VERSION ""

NS_ :

BS_:

BU_: Vector__XXX

BO_ 608 f_CellTemperatures: 8 Vector__XXX
SG_ f_CellTemperatures_Mux M : 7|8@0+ (1,0) [0|0] "" Vector__XXX
SG_ CellTemperature_000_invalidFlag m0 : 8|1@0+ (1,0) [0|1] "" Vector__XXX
SG_ CellTemperature_001_invalidFlag m0 : 9|1@0+ (1,0) [0|1] "" Vector__XXX
SG_ CellTemperature_002_invalidFlag m0 : 10|1@0+ (1,0) [0|1] "" Vector__XXX
SG_ CellTemperature_003_invalidFlag m0 : 11|1@0+ (1,0) [0|1] "" Vector__XXX
SG_ CellTemperature_004_invalidFlag m0 : 12|1@0+ (1,0) [0|1] "" Vector__XXX
SG_ CellTemperature_005_invalidFlag m0 : 13|1@0+ (1,0) [0|1] "" Vector__XXX
SG_ CellTemperature_000 m0 : 23|8@0- (1,0) [-128|127] "degC" Vector__XXX
SG_ CellTemperature_001 m0 : 31|8@0- (1,0) [-128|127] "degC" Vector__XXX
SG_ CellTemperature_002 m0 : 39|8@0- (1,0) [-128|127] "degC" Vector__XXX
SG_ CellTemperature_003 m0 : 47|8@0- (1,0) [-128|127] "degC" Vector__XXX
SG_ CellTemperature_004 m0 : 55|8@0- (1,0) [-128|127] "degC" Vector__XXX
SG_ CellTemperature_005 m0 : 63|8@0- (1,0) [-128|127] "degC" Vector__XXX
SG_ CellTemperature_006_invalidFlag m1 : 8|1@0+ (1,0) [0|1] "" Vector__XXX
SG_ CellTemperature_007_invalidFlag m1 : 9|1@0+ (1,0) [0|1] "" Vector__XXX
SG_ CellTemperature_008_invalidFlag m1 : 10|1@0+ (1,0) [0|1] "" Vector__XXX
SG_ CellTemperature_009_invalidFlag m1 : 11|1@0+ (1,0) [0|1] "" Vector__XXX
SG_ CellTemperature_010_invalidFlag m1 : 12|1@0+ (1,0) [0|1] "" Vector__XXX
SG_ CellTemperature_011_invalidFlag m1 : 13|1@0+ (1,0) [0|1] "" Vector__XXX
SG_ CellTemperature_006 m1 : 23|8@0- (1,0) [-128|127] "degC" Vector__XXX
SG_ CellTemperature_007 m1 : 31|8@0- (1,0) [-128|127] "degC" Vector__XXX
SG_ CellTemperature_008 m1 : 39|8@0- (1,0) [-128|127] "degC" Vector__XXX
SG_ CellTemperature_009 m1 : 47|8@0- (1,0) [-128|127] "degC" Vector__XXX
SG_ CellTemperature_010 m1 : 55|8@0- (1,0) [-128|127] "degC" Vector__XXX
SG_ CellTemperature_011 m1 : 63|8@0- (1,0) [-128|127] "degC" Vector__XXX
SG_ CellTemperature_012_invalidFlag m2 : 8|1@0+ (1,0) [0|1] "" Vector__XXX
SG_ CellTemperature_013_invalidFlag m2 : 9|1@0+ (1,0) [0|1] "" Vector__XXX
SG_ CellTemperature_014_invalidFlag m2 : 10|1@0+ (1,0) [0|1] "" Vector__XXX
SG_ CellTemperature_015_invalidFlag m2 : 11|1@0+ (1,0) [0|1] "" Vector__XXX
SG_ CellTemperature_016_invalidFlag m2 : 12|1@0+ (1,0) [0|1] "" Vector__XXX
SG_ CellTemperature_017_invalidFlag m2 : 13|1@0+ (1,0) [0|1] "" Vector__XXX
SG_ CellTemperature_012 m2 : 23|8@0- (1,0) [-128|127] "degC" Vector__XXX
SG_ CellTemperature_013 m2 : 31|8@0- (1,0) [-128|127] "degC" Vector__XXX
SG_ CellTemperature_014 m2 : 39|8@0- (1,0) [-128|127] "degC" Vector__XXX
SG_ CellTemperature_015 m2 : 47|8@0- (1,0) [-128|127] "degC" Vector__XXX
SG_ CellTemperature_016 m2 : 55|8@0- (1,0) [-128|127] "degC" Vector__XXX
SG_ CellTemperature_017 m2 : 63|8@0- (1,0) [-128|127] "degC" Vector__XXX
SG_ CellTemperature_018_invalidFlag m3 : 8|1@0+ (1,0) [0|1] "" Vector__XXX
SG_ CellTemperature_019_invalidFlag m3 : 9|1@0+ (1,0) [0|1] "" Vector__XXX
SG_ CellTemperature_020_invalidFlag m3 : 10|1@0+ (1,0) [0|1] "" Vector__XXX
SG_ CellTemperature_021_invalidFlag m3 : 11|1@0+ (1,0) [0|1] "" Vector__XXX
SG_ CellTemperature_022_invalidFlag m3 : 12|1@0+ (1,0) [0|1] "" Vector__XXX
SG_ CellTemperature_023_invalidFlag m3 : 13|1@0+ (1,0) [0|1] "" Vector__XXX
SG_ CellTemperature_018 m3 : 23|8@0- (1,0) [-128|127] "degC" Vector__XXX
SG_ CellTemperature_019 m3 : 31|8@0- (1,0) [-128|127] "degC" Vector__XXX
SG_ CellTemperature_020 m3 : 39|8@0- (1,0) [-128|127] "degC" Vector__XXX
SG_ CellTemperature_021 m3 : 47|8@0- (1,0) [-128|127] "degC" Vector__XXX
SG_ CellTemperature_022 m3 : 55|8@0- (1,0) [-128|127] "degC" Vector__XXX
SG_ CellTemperature_023 m3 : 63|8@0- (1,0) [-128|127] "degC" Vector__XXX
SG_ CellTemperature_024_invalidFlag m4 : 8|1@0+ (1,0) [0|1] "" Vector__XXX
SG_ CellTemperature_025_invalidFlag m4 : 9|1@0+ (1,0) [0|1] "" Vector__XXX
SG_ CellTemperature_026_invalidFlag m4 : 10|1@0+ (1,0) [0|1] "" Vector__XXX
SG_ CellTemperature_027_invalidFlag m4 : 11|1@0+ (1,0) [0|1] "" Vector__XXX
SG_ CellTemperature_028_invalidFlag m4 : 12|1@0+ (1,0) [0|1] "" Vector__XXX
SG_ CellTemperature_029_invalidFlag m4 : 13|1@0+ (1,0) [0|1] "" Vector__XXX
SG_ CellTemperature_024 m4 : 23|8@0- (1,0) [-128|127] "degC" Vector__XXX
SG_ CellTemperature_025 m4 : 31|8@0- (1,0) [-128|127] "degC" Vector__XXX
SG_ CellTemperature_026 m4 : 39|8@0- (1,0) [-128|127] "degC" Vector__XXX
SG_ CellTemperature_027 m4 : 47|8@0- (1,0) [-128|127] "degC" Vector__XXX
SG_ CellTemperature_028 m4 : 55|8@0- (1,0) [-128|127] "degC" Vector__XXX
SG_ CellTemperature_029 m4 : 63|8@0- (1,0) [-128|127] "degC" Vector__XXX
SG_ CellTemperature_030_invalidFlag m5 : 8|1@0+ (1,0) [0|1] "" Vector__XXX
SG_ CellTemperature_031_invalidFlag m5 : 9|1@0+ (1,0) [0|1] "" Vector__XXX
SG_ CellTemperature_032_invalidFlag m5 : 10|1@0+ (1,0) [0|1] "" Vector__XXX
SG_ CellTemperature_033_invalidFlag m5 : 11|1@0+ (1,0) [0|1] "" Vector__XXX
SG_ CellTemperature_034_invalidFlag m5 : 12|1@0+ (1,0) [0|1] "" Vector__XXX
SG_ CellTemperature_035_invalidFlag m5 : 13|1@0+ (1,0) [0|1] "" Vector__XXX
SG_ CellTemperature_030 m5 : 23|8@0- (1,0) [-128|127] "degC" Vector__XXX
SG_ CellTemperature_031 m5 : 31|8@0- (1,0) [-128|127] "degC" Vector__XXX
SG_ CellTemperature_032 m5 : 39|8@0- (1,0) [-128|127] "degC" Vector__XXX
SG_ CellTemperature_033 m5 : 47|8@0- (1,0) [-128|127] "degC" Vector__XXX
SG_ CellTemperature_034 m5 : 55|8@0- (1,0) [-128|127] "degC" Vector__XXX
SG_ CellTemperature_035 m5 : 63|8@0- (1,0) [-128|127] "degC" Vector__XXX
SG_ CellTemperature_036_invalidFlag m6 : 8|1@0+ (1,0) [0|1] "" Vector__XXX
SG_ CellTemperature_037_invalidFlag m6 : 9|1@0+ (1,0) [0|1] "" Vector__XXX
SG_ CellTemperature_038_invalidFlag m6 : 10|1@0+ (1,0) [0|1] "" Vector__XXX
SG_ CellTemperature_039_invalidFlag m6 : 11|1@0+ (1,0) [0|1] "" Vector__XXX
SG_ CellTemperature_040_invalidFlag m6 : 12|1@0+ (1,0) [0|1] "" Vector__XXX
SG_ CellTemperature_041_invalidFlag m6 : 13|1@0+ (1,0) [0|1] "" Vector__XXX
SG_ CellTemperature_036 m6 : 23|8@0- (1,0) [-128|127] "degC" Vector__XXX
SG_ CellTemperature_037 m6 : 31|8@0- (1,0) [-128|127] "degC" Vector__XXX
SG_ CellTemperature_038 m6 : 39|8@0- (1,0) [-128|127] "degC" Vector__XXX
SG_ CellTemperature_039 m6 : 47|8@0- (1,0) [-128|127] "degC" Vector__XXX
SG_ CellTemperature_040 m6 : 55|8@0- (1,0) [-128|127] "degC" Vector__XXX
SG_ CellTemperature_041 m6 : 63|8@0- (1,0) [-128|127] "degC" Vector__XXX
SG_ CellTemperature_042_invalidFlag m7 : 8|1@0+ (1,0) [0|1] "" Vector__XXX
SG_ CellTemperature_043_invalidFlag m7 : 9|1@0+ (1,0) [0|1] "" Vector__XXX
SG_ CellTemperature_044_invalidFlag m7 : 10|1@0+ (1,0) [0|1] "" Vector__XXX
SG_ CellTemperature_045_invalidFlag m7 : 11|1@0+ (1,0) [0|1] "" Vector__XXX
SG_ CellTemperature_046_invalidFlag m7 : 12|1@0+ (1,0) [0|1] "" Vector__XXX
SG_ CellTemperature_047_invalidFlag m7 : 13|1@0+ (1,0) [0|1] "" Vector__XXX
SG_ CellTemperature_042 m7 : 23|8@0- (1,0) [-128|127] "degC" Vector__XXX
SG_ CellTemperature_043 m7 : 31|8@0- (1,0) [-128|127] "degC" Vector__XXX
SG_ CellTemperature_044 m7 : 39|8@0- (1,0) [-128|127] "degC" Vector__XXX
SG_ CellTemperature_045 m7 : 47|8@0- (1,0) [-128|127] "degC" Vector__XXX
SG_ CellTemperature_046 m7 : 55|8@0- (1,0) [-128|127] "degC" Vector__XXX
SG_ CellTemperature_047 m7 : 63|8@0- (1,0) [-128|127] "degC" Vector__XXX
SG_ CellTemperature_048_invalidFlag m8 : 8|1@0+ (1,0) [0|1] "" Vector__XXX
SG_ CellTemperature_049_invalidFlag m8 : 9|1@0+ (1,0) [0|1] "" Vector__XXX
SG_ CellTemperature_050_invalidFlag m8 : 10|1@0+ (1,0) [0|1] "" Vector__XXX
SG_ CellTemperature_051_invalidFlag m8 : 11|1@0+ (1,0) [0|1] "" Vector__XXX
SG_ CellTemperature_052_invalidFlag m8 : 12|1@0+ (1,0) [0|1] "" Vector__XXX
SG_ CellTemperature_053_invalidFlag m8 : 13|1@0+ (1,0) [0|1] "" Vector__XXX
SG_ CellTemperature_048 m8 : 23|8@0- (1,0) [-128|127] "degC" Vector__XXX
SG_ CellTemperature_049 m8 : 31|8@0- (1,0) [-128|127] "degC" Vector__XXX
SG_ CellTemperature_050 m8 : 39|8@0- (1,0) [-128|127] "degC" Vector__XXX
SG_ CellTemperature_051 m8 : 47|8@0- (1,0) [-128|127] "degC" Vector__XXX
SG_ CellTemperature_052 m8 : 55|8@0- (1,0) [-128|127] "degC" Vector__XXX
SG_ CellTemperature_053 m8 : 63|8@0- (1,0) [-128|127] "degC" Vector__XXX
SG_ CellTemperature_054_invalidFlag m9 : 8|1@0+ (1,0) [0|1] "" Vector__XXX
SG_ CellTemperature_055_invalidFlag m9 : 9|1@0+ (1,0) [0|1] "" Vector__XXX
SG_ CellTemperature_056_invalidFlag m9 : 10|1@0+ (1,0) [0|1] "" Vector__XXX
SG_ CellTemperature_057_invalidFlag m9 : 11|1@0+ (1,0) [0|1] "" Vector__XXX
SG_ CellTemperature_058_invalidFlag m9 : 12|1@0+ (1,0) [0|1] "" Vector__XXX
SG_ CellTemperature_059_invalidFlag m9 : 13|1@0+ (1,0) [0|1] "" Vector__XXX
SG_ CellTemperature_054 m9 : 23|8@0- (1,0) [-128|127] "degC" Vector__XXX
SG_ CellTemperature_055 m9 : 31|8@0- (1,0) [-128|127] "degC" Vector__XXX
SG_ CellTemperature_056 m9 : 39|8@0- (1,0) [-128|127] "degC" Vector__XXX
SG_ CellTemperature_057 m9 : 47|8@0- (1,0) [-128|127] "degC" Vector__XXX
SG_ CellTemperature_058 m9 : 55|8@0- (1,0) [-128|127] "degC" Vector__XXX
SG_ CellTemperature_059 m9 : 63|8@0- (1,0) [-128|127] "degC" Vector__XXX
SG_ CellTemperature_060_invalidFlag m10 : 8|1@0+ (1,0) [0|1] "" Vector__XXX
SG_ CellTemperature_061_invalidFlag m10 : 9|1@0+ (1,0) [0|1] "" Vector__XXX
SG_ CellTemperature_062_invalidFlag m10 : 10|1@0+ (1,0) [0|1] "" Vector__XXX
SG_ CellTemperature_063_invalidFlag m10 : 11|1@0+ (1,0) [0|1] "" Vector__XXX
SG_ CellTemperature_064_invalidFlag m10 : 12|1@0+ (1,0) [0|1] "" Vector__XXX
SG_ CellTemperature_065_invalidFlag m10 : 13|1@0+ (1,0) [0|1] "" Vector__XXX
SG_ CellTemperature_060 m10 : 23|8@0- (1,0) [-128|127] "degC" Vector__XXX
SG_ CellTemperature_061 m10 : 31|8@0- (1,0) [-128|127] "degC" Vector__XXX
SG_ CellTemperature_062 m10 : 39|8@0- (1,0) [-128|127] "degC" Vector__XXX
SG_ CellTemperature_063 m10 : 47|8@0- (1,0) [-128|127] "degC" Vector__XXX
SG_ CellTemperature_064 m10 : 55|8@0- (1,0) [-128|127] "degC" Vector__XXX
SG_ CellTemperature_065 m10 : 63|8@0- (1,0) [-128|127] "degC" Vector__XXX
SG_ CellTemperature_066_invalidFlag m11 : 8|1@0+ (1,0) [0|1] "" Vector__XXX
SG_ CellTemperature_067_invalidFlag m11 : 9|1@0+ (1,0) [0|1] "" Vector__XXX
SG_ CellTemperature_068_invalidFlag m11 : 10|1@0+ (1,0) [0|1] "" Vector__XXX
SG_ CellTemperature_069_invalidFlag m11 : 11|1@0+ (1,0) [0|1] "" Vector__XXX
SG_ CellTemperature_070_invalidFlag m11 : 12|1@0+ (1,0) [0|1] "" Vector__XXX
SG_ CellTemperature_071_invalidFlag m11 : 13|1@0+ (1,0) [0|1] "" Vector__XXX
SG_ CellTemperature_066 m11 : 23|8@0- (1,0) [-128|127] "degC" Vector__XXX
SG_ CellTemperature_067 m11 : 31|8@0- (1,0) [-128|127] "degC" Vector__XXX
SG_ CellTemperature_068 m11 : 39|8@0- (1,0) [-128|127] "degC" Vector__XXX
SG_ CellTemperature_069 m11 : 47|8@0- (1,0) [-128|127] "degC" Vector__XXX
SG_ CellTemperature_070 m11 : 55|8@0- (1,0) [-128|127] "degC" Vector__XXX
SG_ CellTemperature_071 m11 : 63|8@0- (1,0) [-128|127] "degC" Vector__XXX
SG_ CellTemperature_072_invalidFlag m12 : 8|1@0+ (1,0) [0|1] "" Vector__XXX
SG_ CellTemperature_073_invalidFlag m12 : 9|1@0+ (1,0) [0|1] "" Vector__XXX
SG_ CellTemperature_074_invalidFlag m12 : 10|1@0+ (1,0) [0|1] "" Vector__XXX
SG_ CellTemperature_075_invalidFlag m12 : 11|1@0+ (1,0) [0|1] "" Vector__XXX
SG_ CellTemperature_076_invalidFlag m12 : 12|1@0+ (1,0) [0|1] "" Vector__XXX
SG_ CellTemperature_077_invalidFlag m12 : 13|1@0+ (1,0) [0|1] "" Vector__XXX
SG_ CellTemperature_072 m12 : 23|8@0- (1,0) [-128|127] "degC" Vector__XXX
SG_ CellTemperature_073 m12 : 31|8@0- (1,0) [-128|127] "degC" Vector__XXX
SG_ CellTemperature_074 m12 : 39|8@0- (1,0) [-128|127] "degC" Vector__XXX
SG_ CellTemperature_075 m12 : 47|8@0- (1,0) [-128|127] "degC" Vector__XXX
SG_ CellTemperature_076 m12 : 55|8@0- (1,0) [-128|127] "degC" Vector__XXX
SG_ CellTemperature_077 m12 : 63|8@0- (1,0) [-128|127] "degC" Vector__XXX
SG_ CellTemperature_078_invalidFlag m13 : 8|1@0+ (1,0) [0|1] "" Vector__XXX
SG_ CellTemperature_079_invalidFlag m13 : 9|1@0+ (1,0) [0|1] "" Vector__XXX
SG_ CellTemperature_080_invalidFlag m13 : 10|1@0+ (1,0) [0|1] "" Vector__XXX
SG_ CellTemperature_081_invalidFlag m13 : 11|1@0+ (1,0) [0|1] "" Vector__XXX
SG_ CellTemperature_082_invalidFlag m13 : 12|1@0+ (1,0) [0|1] "" Vector__XXX
SG_ CellTemperature_083_invalidFlag m13 : 13|1@0+ (1,0) [0|1] "" Vector__XXX
SG_ CellTemperature_078 m13 : 23|8@0- (1,0) [-128|127] "degC" Vector__XXX
SG_ CellTemperature_079 m13 : 31|8@0- (1,0) [-128|127] "degC" Vector__XXX
SG_ CellTemperature_080 m13 : 39|8@0- (1,0) [-128|127] "degC" Vector__XXX
SG_ CellTemperature_081 m13 : 47|8@0- (1,0) [-128|127] "degC" Vector__XXX
SG_ CellTemperature_082 m13 : 55|8@0- (1,0) [-128|127] "degC" Vector__XXX
SG_ CellTemperature_083 m13 : 63|8@0- (1,0) [-128|127] "degC" Vector__XXX
SG_ CellTemperature_084_invalidFlag m14 : 8|1@0+ (1,0) [0|1] "" Vector__XXX
SG_ CellTemperature_085_invalidFlag m14 : 9|1@0+ (1,0) [0|1] "" Vector__XXX
SG_ CellTemperature_086_invalidFlag m14 : 10|1@0+ (1,0) [0|1] "" Vector__XXX
SG_ CellTemperature_087_invalidFlag m14 : 11|1@0+ (1,0) [0|1] "" Vector__XXX
SG_ CellTemperature_088_invalidFlag m14 : 12|1@0+ (1,0) [0|1] "" Vector__XXX
SG_ CellTemperature_089_invalidFlag m14 : 13|1@0+ (1,0) [0|1] "" Vector__XXX
SG_ CellTemperature_084 m14 : 23|8@0- (1,0) [-128|127] "degC" Vector__XXX
SG_ CellTemperature_085 m14 : 31|8@0- (1,0) [-128|127] "degC" Vector__XXX
SG_ CellTemperature_086 m14 : 39|8@0- (1,0) [-128|127] "degC" Vector__XXX
SG_ CellTemperature_087 m14 : 47|8@0- (1,0) [-128|127] "degC" Vector__XXX
SG_ CellTemperature_088 m14 : 55|8@0- (1,0) [-128|127] "degC" Vector__XXX
SG_ CellTemperature_089 m14 : 63|8@0- (1,0) [-128|127] "degC" Vector__XXX
SG_ CellTemperature_090_invalidFlag m15 : 8|1@0+ (1,0) [0|1] "" Vector__XXX
SG_ CellTemperature_091_invalidFlag m15 : 9|1@0+ (1,0) [0|1] "" Vector__XXX
SG_ CellTemperature_092_invalidFlag m15 : 10|1@0+ (1,0) [0|1] "" Vector__XXX
SG_ CellTemperature_093_invalidFlag m15 : 11|1@0+ (1,0) [0|1] "" Vector__XXX
SG_ CellTemperature_094_invalidFlag m15 : 12|1@0+ (1,0) [0|1] "" Vector__XXX
SG_ CellTemperature_095_invalidFlag m15 : 13|1@0+ (1,0) [0|1] "" Vector__XXX
SG_ CellTemperature_090 m15 : 23|8@0- (1,0) [-128|127] "degC" Vector__XXX
SG_ CellTemperature_091 m15 : 31|8@0- (1,0) [-128|127] "degC" Vector__XXX
SG_ CellTemperature_092 m15 : 39|8@0- (1,0) [-128|127] "degC" Vector__XXX
SG_ CellTemperature_093 m15 : 47|8@0- (1,0) [-128|127] "degC" Vector__XXX
SG_ CellTemperature_094 m15 : 55|8@0- (1,0) [-128|127] "degC" Vector__XXX
SG_ CellTemperature_095 m15 : 63|8@0- (1,0) [-128|127] "degC" Vector__XXX
SG_ CellTemperature_096_invalidFlag m16 : 8|1@0+ (1,0) [0|1] "" Vector__XXX
SG_ CellTemperature_097_invalidFlag m16 : 9|1@0+ (1,0) [0|1] "" Vector__XXX
SG_ CellTemperature_098_invalidFlag m16 : 10|1@0+ (1,0) [0|1] "" Vector__XXX
SG_ CellTemperature_099_invalidFlag m16 : 11|1@0+ (1,0) [0|1] "" Vector__XXX
SG_ CellTemperature_100_invalidFlag m16 : 12|1@0+ (1,0) [0|1] "" Vector__XXX
SG_ CellTemperature_101_invalidFlag m16 : 13|1@0+ (1,0) [0|1] "" Vector__XXX
SG_ CellTemperature_096 m16 : 23|8@0- (1,0) [-128|127] "degC" Vector__XXX
SG_ CellTemperature_097 m16 : 31|8@0- (1,0) [-128|127] "degC" Vector__XXX
SG_ CellTemperature_098 m16 : 39|8@0- (1,0) [-128|127] "degC" Vector__XXX
SG_ CellTemperature_099 m16 : 47|8@0- (1,0) [-128|127] "degC" Vector__XXX
SG_ CellTemperature_100 m16 : 55|8@0- (1,0) [-128|127] "degC" Vector__XXX
SG_ CellTemperature_101 m16 : 63|8@0- (1,0) [-128|127] "degC" Vector__XXX
SG_ CellTemperature_102_invalidFlag m17 : 8|1@0+ (1,0) [0|1] "" Vector__XXX
SG_ CellTemperature_103_invalidFlag m17 : 9|1@0+ (1,0) [0|1] "" Vector__XXX
SG_ CellTemperature_104_invalidFlag m17 : 10|1@0+ (1,0) [0|1] "" Vector__XXX
SG_ CellTemperature_105_invalidFlag m17 : 11|1@0+ (1,0) [0|1] "" Vector__XXX
SG_ CellTemperature_106_invalidFlag m17 : 12|1@0+ (1,0) [0|1] "" Vector__XXX
SG_ CellTemperature_107_invalidFlag m17 : 13|1@0+ (1,0) [0|1] "" Vector__XXX
SG_ CellTemperature_102 m17 : 23|8@0- (1,0) [-128|127] "degC" Vector__XXX
SG_ CellTemperature_103 m17 : 31|8@0- (1,0) [-128|127] "degC" Vector__XXX
SG_ CellTemperature_104 m17 : 39|8@0- (1,0) [-128|127] "degC" Vector__XXX
SG_ CellTemperature_105 m17 : 47|8@0- (1,0) [-128|127] "degC" Vector__XXX
SG_ CellTemperature_106 m17 : 55|8@0- (1,0) [-128|127] "degC" Vector__XXX
SG_ CellTemperature_107 m17 : 63|8@0- (1,0) [-128|127] "degC" Vector__XXX
SG_ CellTemperature_108_invalidFlag m18 : 8|1@0+ (1,0) [0|1] "" Vector__XXX
SG_ CellTemperature_109_invalidFlag m18 : 9|1@0+ (1,0) [0|1] "" Vector__XXX
SG_ CellTemperature_110_invalidFlag m18 : 10|1@0+ (1,0) [0|1] "" Vector__XXX
SG_ CellTemperature_111_invalidFlag m18 : 11|1@0+ (1,0) [0|1] "" Vector__XXX
SG_ CellTemperature_112_invalidFlag m18 : 12|1@0+ (1,0) [0|1] "" Vector__XXX
SG_ CellTemperature_113_invalidFlag m18 : 13|1@0+ (1,0) [0|1] "" Vector__XXX
SG_ CellTemperature_108 m18 : 23|8@0- (1,0) [-128|127] "degC" Vector__XXX
SG_ CellTemperature_109 m18 : 31|8@0- (1,0) [-128|127] "degC" Vector__XXX
SG_ CellTemperature_110 m18 : 39|8@0- (1,0) [-128|127] "degC" Vector__XXX
SG_ CellTemperature_111 m18 : 47|8@0- (1,0) [-128|127] "degC" Vector__XXX
SG_ CellTemperature_112 m18 : 55|8@0- (1,0) [-128|127] "degC" Vector__XXX
SG_ CellTemperature_113 m18 : 63|8@0- (1,0) [-128|127] "degC" Vector__XXX
SG_ CellTemperature_114_invalidFlag m19 : 8|1@0+ (1,0) [0|1] "" Vector__XXX
SG_ CellTemperature_115_invalidFlag m19 : 9|1@0+ (1,0) [0|1] "" Vector__XXX
SG_ CellTemperature_116_invalidFlag m19 : 10|1@0+ (1,0) [0|1] "" Vector__XXX
SG_ CellTemperature_117_invalidFlag m19 : 11|1@0+ (1,0) [0|1] "" Vector__XXX
SG_ CellTemperature_118_invalidFlag m19 : 12|1@0+ (1,0) [0|1] "" Vector__XXX
SG_ CellTemperature_119_invalidFlag m19 : 13|1@0+ (1,0) [0|1] "" Vector__XXX
SG_ CellTemperature_114 m19 : 23|8@0- (1,0) [-128|127] "degC" Vector__XXX
SG_ CellTemperature_115 m19 : 31|8@0- (1,0) [-128|127] "degC" Vector__XXX
SG_ CellTemperature_116 m19 : 39|8@0- (1,0) [-128|127] "degC" Vector__XXX
SG_ CellTemperature_117 m19 : 47|8@0- (1,0) [-128|127] "degC" Vector__XXX
SG_ CellTemperature_118 m19 : 55|8@0- (1,0) [-128|127] "degC" Vector__XXX
SG_ CellTemperature_119 m19 : 63|8@0- (1,0) [-128|127] "degC" Vector__XXX
SG_ CellTemperature_120_invalidFlag m20 : 8|1@0+ (1,0) [0|1] "" Vector__XXX
SG_ CellTemperature_121_invalidFlag m20 : 9|1@0+ (1,0) [0|1] "" Vector__XXX
SG_ CellTemperature_122_invalidFlag m20 : 10|1@0+ (1,0) [0|1] "" Vector__XXX
SG_ CellTemperature_123_invalidFlag m20 : 11|1@0+ (1,0) [0|1] "" Vector__XXX
SG_ CellTemperature_124_invalidFlag m20 : 12|1@0+ (1,0) [0|1] "" Vector__XXX
SG_ CellTemperature_125_invalidFlag m20 : 13|1@0+ (1,0) [0|1] "" Vector__XXX
SG_ CellTemperature_120 m20 : 23|8@0- (1,0) [-128|127] "degC" Vector__XXX
SG_ CellTemperature_121 m20 : 31|8@0- (1,0) [-128|127] "degC" Vector__XXX
SG_ CellTemperature_122 m20 : 39|8@0- (1,0) [-128|127] "degC" Vector__XXX
SG_ CellTemperature_123 m20 : 47|8@0- (1,0) [-128|127] "degC" Vector__XXX
SG_ CellTemperature_124 m20 : 55|8@0- (1,0) [-128|127] "degC" Vector__XXX
SG_ CellTemperature_125 m20 : 63|8@0- (1,0) [-128|127] "degC" Vector__XXX
SG_ CellTemperature_126_invalidFlag m21 : 8|1@0+ (1,0) [0|1] "" Vector__XXX
SG_ CellTemperature_127_invalidFlag m21 : 9|1@0+ (1,0) [0|1] "" Vector__XXX
SG_ CellTemperature_128_invalidFlag m21 : 10|1@0+ (1,0) [0|1] "" Vector__XXX
SG_ CellTemperature_129_invalidFlag m21 : 11|1@0+ (1,0) [0|1] "" Vector__XXX
SG_ CellTemperature_130_invalidFlag m21 : 12|1@0+ (1,0) [0|1] "" Vector__XXX
SG_ CellTemperature_131_invalidFlag m21 : 13|1@0+ (1,0) [0|1] "" Vector__XXX
SG_ CellTemperature_126 m21 : 23|8@0- (1,0) [-128|127] "degC" Vector__XXX
SG_ CellTemperature_127 m21 : 31|8@0- (1,0) [-128|127] "degC" Vector__XXX
SG_ CellTemperature_128 m21 : 39|8@0- (1,0) [-128|127] "degC" Vector__XXX
SG_ CellTemperature_129 m21 : 47|8@0- (1,0) [-128|127] "degC" Vector__XXX
SG_ CellTemperature_130 m21 : 55|8@0- (1,0) [-128|127] "degC" Vector__XXX
SG_ CellTemperature_131 m21 : 63|8@0- (1,0) [-128|127] "degC" Vector__XXX
SG_ CellTemperature_132_invalidFlag m22 : 8|1@0+ (1,0) [0|1] "" Vector__XXX
SG_ CellTemperature_133_invalidFlag m22 : 9|1@0+ (1,0) [0|1] "" Vector__XXX
SG_ CellTemperature_134_invalidFlag m22 : 10|1@0+ (1,0) [0|1] "" Vector__XXX
SG_ CellTemperature_135_invalidFlag m22 : 11|1@0+ (1,0) [0|1] "" Vector__XXX
SG_ CellTemperature_136_invalidFlag m22 : 12|1@0+ (1,0) [0|1] "" Vector__XXX
SG_ CellTemperature_137_invalidFlag m22 : 13|1@0+ (1,0) [0|1] "" Vector__XXX
SG_ CellTemperature_132 m22 : 23|8@0- (1,0) [-128|127] "degC" Vector__XXX
SG_ CellTemperature_133 m22 : 31|8@0- (1,0) [-128|127] "degC" Vector__XXX
SG_ CellTemperature_134 m22 : 39|8@0- (1,0) [-128|127] "degC" Vector__XXX
SG_ CellTemperature_135 m22 : 47|8@0- (1,0) [-128|127] "degC" Vector__XXX
SG_ CellTemperature_136 m22 : 55|8@0- (1,0) [-128|127] "degC" Vector__XXX
SG_ CellTemperature_137 m22 : 63|8@0- (1,0) [-128|127] "degC" Vector__XXX
SG_ CellTemperature_138_invalidFlag m23 : 8|1@0+ (1,0) [0|1] "" Vector__XXX
SG_ CellTemperature_139_invalidFlag m23 : 9|1@0+ (1,0) [0|1] "" Vector__XXX
SG_ CellTemperature_140_invalidFlag m23 : 10|1@0+ (1,0) [0|1] "" Vector__XXX
SG_ CellTemperature_141_invalidFlag m23 : 11|1@0+ (1,0) [0|1] "" Vector__XXX
SG_ CellTemperature_142_invalidFlag m23 : 12|1@0+ (1,0) [0|1] "" Vector__XXX
SG_ CellTemperature_143_invalidFlag m23 : 13|1@0+ (1,0) [0|1] "" Vector__XXX
SG_ CellTemperature_138 m23 : 23|8@0- (1,0) [-128|127] "degC" Vector__XXX
SG_ CellTemperature_139 m23 : 31|8@0- (1,0) [-128|127] "degC" Vector__XXX
SG_ CellTemperature_140 m23 : 39|8@0- (1,0) [-128|127] "degC" Vector__XXX
SG_ CellTemperature_141 m23 : 47|8@0- (1,0) [-128|127] "degC" Vector__XXX
SG_ CellTemperature_142 m23 : 55|8@0- (1,0) [-128|127] "degC" Vector__XXX
SG_ CellTemperature_143 m23 : 63|8@0- (1,0) [-128|127] "degC" Vector__XXX
SG_ CellTemperature_144_invalidFlag m24 : 8|1@0+ (1,0) [0|1] "" Vector__XXX
SG_ CellTemperature_145_invalidFlag m24 : 9|1@0+ (1,0) [0|1] "" Vector__XXX
SG_ CellTemperature_146_invalidFlag m24 : 10|1@0+ (1,0) [0|1] "" Vector__XXX
SG_ CellTemperature_147_invalidFlag m24 : 11|1@0+ (1,0) [0|1] "" Vector__XXX
SG_ CellTemperature_148_invalidFlag m24 : 12|1@0+ (1,0) [0|1] "" Vector__XXX
SG_ CellTemperature_149_invalidFlag m24 : 13|1@0+ (1,0) [0|1] "" Vector__XXX
SG_ CellTemperature_144 m24 : 23|8@0- (1,0) [-128|127] "degC" Vector__XXX
SG_ CellTemperature_145 m24 : 31|8@0- (1,0) [-128|127] "degC" Vector__XXX
SG_ CellTemperature_146 m24 : 39|8@0- (1,0) [-128|127] "degC" Vector__XXX
SG_ CellTemperature_147 m24 : 47|8@0- (1,0) [-128|127] "degC" Vector__XXX
SG_ CellTemperature_148 m24 : 55|8@0- (1,0) [-128|127] "degC" Vector__XXX
SG_ CellTemperature_149 m24 : 63|8@0- (1,0) [-128|127] "degC" Vector__XXX
SG_ CellTemperature_150_invalidFlag m25 : 8|1@0+ (1,0) [0|1] "" Vector__XXX
SG_ CellTemperature_151_invalidFlag m25 : 9|1@0+ (1,0) [0|1] "" Vector__XXX
SG_ CellTemperature_152_invalidFlag m25 : 10|1@0+ (1,0) [0|1] "" Vector__XXX
SG_ CellTemperature_153_invalidFlag m25 : 11|1@0+ (1,0) [0|1] "" Vector__XXX
SG_ CellTemperature_154_invalidFlag m25 : 12|1@0+ (1,0) [0|1] "" Vector__XXX
SG_ CellTemperature_155_invalidFlag m25 : 13|1@0+ (1,0) [0|1] "" Vector__XXX
SG_ CellTemperature_150 m25 : 23|8@0- (1,0) [-128|127] "degC" Vector__XXX
SG_ CellTemperature_151 m25 : 31|8@0- (1,0) [-128|127] "degC" Vector__XXX
SG_ CellTemperature_152 m25 : 39|8@0- (1,0) [-128|127] "degC" Vector__XXX
SG_ CellTemperature_153 m25 : 47|8@0- (1,0) [-128|127] "degC" Vector__XXX
SG_ CellTemperature_154 m25 : 55|8@0- (1,0) [-128|127] "degC" Vector__XXX
SG_ CellTemperature_155 m25 : 63|8@0- (1,0) [-128|127] "degC" Vector__XXX
SG_ CellTemperature_156_invalidFlag m26 : 8|1@0+ (1,0) [0|1] "" Vector__XXX
SG_ CellTemperature_157_invalidFlag m26 : 9|1@0+ (1,0) [0|1] "" Vector__XXX
SG_ CellTemperature_158_invalidFlag m26 : 10|1@0+ (1,0) [0|1] "" Vector__XXX
SG_ CellTemperature_159_invalidFlag m26 : 11|1@0+ (1,0) [0|1] "" Vector__XXX
SG_ CellTemperature_160_invalidFlag m26 : 12|1@0+ (1,0) [0|1] "" Vector__XXX
SG_ CellTemperature_161_invalidFlag m26 : 13|1@0+ (1,0) [0|1] "" Vector__XXX
SG_ CellTemperature_156 m26 : 23|8@0- (1,0) [-128|127] "degC" Vector__XXX
SG_ CellTemperature_157 m26 : 31|8@0- (1,0) [-128|127] "degC" Vector__XXX
SG_ CellTemperature_158 m26 : 39|8@0- (1,0) [-128|127] "degC" Vector__XXX
SG_ CellTemperature_159 m26 : 47|8@0- (1,0) [-128|127] "degC" Vector__XXX
SG_ CellTemperature_160 m26 : 55|8@0- (1,0) [-128|127] "degC" Vector__XXX
SG_ CellTemperature_161 m26 : 63|8@0- (1,0) [-128|127] "degC" Vector__XXX
SG_ CellTemperature_162_invalidFlag m27 : 8|1@0+ (1,0) [0|1] "" Vector__XXX
SG_ CellTemperature_163_invalidFlag m27 : 9|1@0+ (1,0) [0|1] "" Vector__XXX
SG_ CellTemperature_164_invalidFlag m27 : 10|1@0+ (1,0) [0|1] "" Vector__XXX
SG_ CellTemperature_165_invalidFlag m27 : 11|1@0+ (1,0) [0|1] "" Vector__XXX
SG_ CellTemperature_166_invalidFlag m27 : 12|1@0+ (1,0) [0|1] "" Vector__XXX
SG_ CellTemperature_167_invalidFlag m27 : 13|1@0+ (1,0) [0|1] "" Vector__XXX
SG_ CellTemperature_162 m27 : 23|8@0- (1,0) [-128|127] "degC" Vector__XXX
SG_ CellTemperature_163 m27 : 31|8@0- (1,0) [-128|127] "degC" Vector__XXX
SG_ CellTemperature_164 m27 : 39|8@0- (1,0) [-128|127] "degC" Vector__XXX
SG_ CellTemperature_165 m27 : 47|8@0- (1,0) [-128|127] "degC" Vector__XXX
SG_ CellTemperature_166 m27 : 55|8@0- (1,0) [-128|127] "degC" Vector__XXX
SG_ CellTemperature_167 m27 : 63|8@0- (1,0) [-128|127] "degC" Vector__XXX
SG_ CellTemperature_168_invalidFlag m28 : 8|1@0+ (1,0) [0|1] "" Vector__XXX
SG_ CellTemperature_169_invalidFlag m28 : 9|1@0+ (1,0) [0|1] "" Vector__XXX
SG_ CellTemperature_170_invalidFlag m28 : 10|1@0+ (1,0) [0|1] "" Vector__XXX
SG_ CellTemperature_171_invalidFlag m28 : 11|1@0+ (1,0) [0|1] "" Vector__XXX
SG_ CellTemperature_172_invalidFlag m28 : 12|1@0+ (1,0) [0|1] "" Vector__XXX
SG_ CellTemperature_173_invalidFlag m28 : 13|1@0+ (1,0) [0|1] "" Vector__XXX
SG_ CellTemperature_168 m28 : 23|8@0- (1,0) [-128|127] "degC" Vector__XXX
SG_ CellTemperature_169 m28 : 31|8@0- (1,0) [-128|127] "degC" Vector__XXX
SG_ CellTemperature_170 m28 : 39|8@0- (1,0) [-128|127] "degC" Vector__XXX
SG_ CellTemperature_171 m28 : 47|8@0- (1,0) [-128|127] "degC" Vector__XXX
SG_ CellTemperature_172 m28 : 55|8@0- (1,0) [-128|127] "degC" Vector__XXX
SG_ CellTemperature_173 m28 : 63|8@0- (1,0) [-128|127] "degC" Vector__XXX
SG_ CellTemperature_174_invalidFlag m29 : 8|1@0+ (1,0) [0|1] "" Vector__XXX
SG_ CellTemperature_175_invalidFlag m29 : 9|1@0+ (1,0) [0|1] "" Vector__XXX
SG_ CellTemperature_176_invalidFlag m29 : 10|1@0+ (1,0) [0|1] "" Vector__XXX
SG_ CellTemperature_177_invalidFlag m29 : 11|1@0+ (1,0) [0|1] "" Vector__XXX
SG_ CellTemperature_178_invalidFlag m29 : 12|1@0+ (1,0) [0|1] "" Vector__XXX
SG_ CellTemperature_179_invalidFlag m29 : 13|1@0+ (1,0) [0|1] "" Vector__XXX
SG_ CellTemperature_174 m29 : 23|8@0- (1,0) [-128|127] "degC" Vector__XXX
SG_ CellTemperature_175 m29 : 31|8@0- (1,0) [-128|127] "degC" Vector__XXX
SG_ CellTemperature_176 m29 : 39|8@0- (1,0) [-128|127] "degC" Vector__XXX
SG_ CellTemperature_177 m29 : 47|8@0- (1,0) [-128|127] "degC" Vector__XXX
SG_ CellTemperature_178 m29 : 55|8@0- (1,0) [-128|127] "degC" Vector__XXX
SG_ CellTemperature_179 m29 : 63|8@0- (1,0) [-128|127] "degC" Vector__XXX

BO_ 592 f_CellVoltages: 8 Vector__XXX
SG_ f_CellVoltages_Mux M : 7|8@0+ (1,0) [0|0] "" Vector__XXX
SG_ CellVoltage_000_invalidFlag m0 : 12|1@0+ (1,0) [0|1] "" Vector__XXX
SG_ CellVoltage_001_invalidFlag m0 : 13|1@0+ (1,0) [0|1] "" Vector__XXX
SG_ CellVoltage_002_invalidFlag m0 : 14|1@0+ (1,0) [0|1] "" Vector__XXX
SG_ CellVoltage_003_invalidFlag m0 : 15|1@0+ (1,0) [0|1] "" Vector__XXX
SG_ CellVoltage_000 m0 : 11|13@0+ (1,0) [0|8191] "mV" Vector__XXX
SG_ CellVoltage_001 m0 : 30|13@0+ (1,0) [0|8191] "mV" Vector__XXX
SG_ CellVoltage_002 m0 : 33|13@0+ (1,0) [0|8191] "mV" Vector__XXX
SG_ CellVoltage_003 m0 : 52|13@0+ (1,0) [0|8191] "mV" Vector__XXX
SG_ CellVoltage_004_invalidFlag m1 : 12|1@0+ (1,0) [0|1] "" Vector__XXX
SG_ CellVoltage_005_invalidFlag m1 : 13|1@0+ (1,0) [0|1] "" Vector__XXX
SG_ CellVoltage_006_invalidFlag m1 : 14|1@0+ (1,0) [0|1] "" Vector__XXX
SG_ CellVoltage_007_invalidFlag m1 : 15|1@0+ (1,0) [0|1] "" Vector__XXX
SG_ CellVoltage_004 m1 : 11|13@0+ (1,0) [0|8191] "mV" Vector__XXX
SG_ CellVoltage_005 m1 : 30|13@0+ (1,0) [0|8191] "mV" Vector__XXX
SG_ CellVoltage_006 m1 : 33|13@0+ (1,0) [0|8191] "mV" Vector__XXX
SG_ CellVoltage_007 m1 : 52|13@0+ (1,0) [0|8191] "mV" Vector__XXX
SG_ CellVoltage_008_invalidFlag m2 : 12|1@0+ (1,0) [0|1] "" Vector__XXX
SG_ CellVoltage_009_invalidFlag m2 : 13|1@0+ (1,0) [0|1] "" Vector__XXX
SG_ CellVoltage_010_invalidFlag m2 : 14|1@0+ (1,0) [0|1] "" Vector__XXX
SG_ CellVoltage_011_invalidFlag m2 : 15|1@0+ (1,0) [0|1] "" Vector__XXX
SG_ CellVoltage_008 m2 : 11|13@0+ (1,0) [0|8191] "mV" Vector__XXX
SG_ CellVoltage_009 m2 : 30|13@0+ (1,0) [0|8191] "mV" Vector__XXX
SG_ CellVoltage_010 m2 : 33|13@0+ (1,0) [0|8191] "mV" Vector__XXX
SG_ CellVoltage_011 m2 : 52|13@0+ (1,0) [0|8191] "mV" Vector__XXX
SG_ CellVoltage_012_invalidFlag m3 : 12|1@0+ (1,0) [0|1] "" Vector__XXX
SG_ CellVoltage_013_invalidFlag m3 : 13|1@0+ (1,0) [0|1] "" Vector__XXX
SG_ CellVoltage_014_invalidFlag m3 : 14|1@0+ (1,0) [0|1] "" Vector__XXX
SG_ CellVoltage_015_invalidFlag m3 : 15|1@0+ (1,0) [0|1] "" Vector__XXX
SG_ CellVoltage_012 m3 : 11|13@0+ (1,0) [0|8191] "mV" Vector__XXX
SG_ CellVoltage_013 m3 : 30|13@0+ (1,0) [0|8191] "mV" Vector__XXX
SG_ CellVoltage_014 m3 : 33|13@0+ (1,0) [0|8191] "mV" Vector__XXX
SG_ CellVoltage_015 m3 : 52|13@0+ (1,0) [0|8191] "mV" Vector__XXX
SG_ CellVoltage_016_invalidFlag m4 : 12|1@0+ (1,0) [0|1] "" Vector__XXX
SG_ CellVoltage_017_invalidFlag m4 : 13|1@0+ (1,0) [0|1] "" Vector__XXX
SG_ CellVoltage_018_invalidFlag m4 : 14|1@0+ (1,0) [0|1] "" Vector__XXX
SG_ CellVoltage_019_invalidFlag m4 : 15|1@0+ (1,0) [0|1] "" Vector__XXX
SG_ CellVoltage_016 m4 : 11|13@0+ (1,0) [0|8191] "mV" Vector__XXX
SG_ CellVoltage_017 m4 : 30|13@0+ (1,0) [0|8191] "mV" Vector__XXX
SG_ CellVoltage_018 m4 : 33|13@0+ (1,0) [0|8191] "mV" Vector__XXX
SG_ CellVoltage_019 m4 : 52|13@0+ (1,0) [0|8191] "mV" Vector__XXX
SG_ CellVoltage_020_invalidFlag m5 : 12|1@0+ (1,0) [0|1] "" Vector__XXX
SG_ CellVoltage_021_invalidFlag m5 : 13|1@0+ (1,0) [0|1] "" Vector__XXX
SG_ CellVoltage_022_invalidFlag m5 : 14|1@0+ (1,0) [0|1] "" Vector__XXX
SG_ CellVoltage_023_invalidFlag m5 : 15|1@0+ (1,0) [0|1] "" Vector__XXX
SG_ CellVoltage_020 m5 : 11|13@0+ (1,0) [0|8191] "mV" Vector__XXX
SG_ CellVoltage_021 m5 : 30|13@0+ (1,0) [0|8191] "mV" Vector__XXX
SG_ CellVoltage_022 m5 : 33|13@0+ (1,0) [0|8191] "mV" Vector__XXX
SG_ CellVoltage_023 m5 : 52|13@0+ (1,0) [0|8191] "mV" Vector__XXX
SG_ CellVoltage_024_invalidFlag m6 : 12|1@0+ (1,0) [0|1] "" Vector__XXX
SG_ CellVoltage_025_invalidFlag m6 : 13|1@0+ (1,0) [0|1] "" Vector__XXX
SG_ CellVoltage_026_invalidFlag m6 : 14|1@0+ (1,0) [0|1] "" Vector__XXX
SG_ CellVoltage_027_invalidFlag m6 : 15|1@0+ (1,0) [0|1] "" Vector__XXX
SG_ CellVoltage_024 m6 : 11|13@0+ (1,0) [0|8191] "mV" Vector__XXX
SG_ CellVoltage_025 m6 : 30|13@0+ (1,0) [0|8191] "mV" Vector__XXX
SG_ CellVoltage_026 m6 : 33|13@0+ (1,0) [0|8191] "mV" Vector__XXX
SG_ CellVoltage_027 m6 : 52|13@0+ (1,0) [0|8191] "mV" Vector__XXX
SG_ CellVoltage_028_invalidFlag m7 : 12|1@0+ (1,0) [0|1] "" Vector__XXX
SG_ CellVoltage_029_invalidFlag m7 : 13|1@0+ (1,0) [0|1] "" Vector__XXX
SG_ CellVoltage_030_invalidFlag m7 : 14|1@0+ (1,0) [0|1] "" Vector__XXX
SG_ CellVoltage_031_invalidFlag m7 : 15|1@0+ (1,0) [0|1] "" Vector__XXX
SG_ CellVoltage_028 m7 : 11|13@0+ (1,0) [0|8191] "mV" Vector__XXX
SG_ CellVoltage_029 m7 : 30|13@0+ (1,0) [0|8191] "mV" Vector__XXX
SG_ CellVoltage_030 m7 : 33|13@0+ (1,0) [0|8191] "mV" Vector__XXX
SG_ CellVoltage_031 m7 : 52|13@0+ (1,0) [0|8191] "mV" Vector__XXX
SG_ CellVoltage_032_invalidFlag m8 : 12|1@0+ (1,0) [0|1] "" Vector__XXX
SG_ CellVoltage_033_invalidFlag m8 : 13|1@0+ (1,0) [0|1] "" Vector__XXX
SG_ CellVoltage_034_invalidFlag m8 : 14|1@0+ (1,0) [0|1] "" Vector__XXX
SG_ CellVoltage_035_invalidFlag m8 : 15|1@0+ (1,0) [0|1] "" Vector__XXX
SG_ CellVoltage_032 m8 : 11|13@0+ (1,0) [0|8191] "mV" Vector__XXX
SG_ CellVoltage_033 m8 : 30|13@0+ (1,0) [0|8191] "mV" Vector__XXX
SG_ CellVoltage_034 m8 : 33|13@0+ (1,0) [0|8191] "mV" Vector__XXX
SG_ CellVoltage_035 m8 : 52|13@0+ (1,0) [0|8191] "mV" Vector__XXX
SG_ CellVoltage_036_invalidFlag m9 : 12|1@0+ (1,0) [0|1] "" Vector__XXX
SG_ CellVoltage_037_invalidFlag m9 : 13|1@0+ (1,0) [0|1] "" Vector__XXX
SG_ CellVoltage_038_invalidFlag m9 : 14|1@0+ (1,0) [0|1] "" Vector__XXX
SG_ CellVoltage_039_invalidFlag m9 : 15|1@0+ (1,0) [0|1] "" Vector__XXX
SG_ CellVoltage_036 m9 : 11|13@0+ (1,0) [0|8191] "mV" Vector__XXX
SG_ CellVoltage_037 m9 : 30|13@0+ (1,0) [0|8191] "mV" Vector__XXX
SG_ CellVoltage_038 m9 : 33|13@0+ (1,0) [0|8191] "mV" Vector__XXX
SG_ CellVoltage_039 m9 : 52|13@0+ (1,0) [0|8191] "mV" Vector__XXX
SG_ CellVoltage_040_invalidFlag m10 : 12|1@0+ (1,0) [0|1] "" Vector__XXX
SG_ CellVoltage_041_invalidFlag m10 : 13|1@0+ (1,0) [0|1] "" Vector__XXX
SG_ CellVoltage_042_invalidFlag m10 : 14|1@0+ (1,0) [0|1] "" Vector__XXX
SG_ CellVoltage_043_invalidFlag m10 : 15|1@0+ (1,0) [0|1] "" Vector__XXX
SG_ CellVoltage_040 m10 : 11|13@0+ (1,0) [0|8191] "mV" Vector__XXX
SG_ CellVoltage_041 m10 : 30|13@0+ (1,0) [0|8191] "mV" Vector__XXX
SG_ CellVoltage_042 m10 : 33|13@0+ (1,0) [0|8191] "mV" Vector__XXX
SG_ CellVoltage_043 m10 : 52|13@0+ (1,0) [0|8191] "mV" Vector__XXX
SG_ CellVoltage_044_invalidFlag m11 : 12|1@0+ (1,0) [0|1] "" Vector__XXX
SG_ CellVoltage_045_invalidFlag m11 : 13|1@0+ (1,0) [0|1] "" Vector__XXX
SG_ CellVoltage_046_invalidFlag m11 : 14|1@0+ (1,0) [0|1] "" Vector__XXX
SG_ CellVoltage_047_invalidFlag m11 : 15|1@0+ (1,0) [0|1] "" Vector__XXX
SG_ CellVoltage_044 m11 : 11|13@0+ (1,0) [0|8191] "mV" Vector__XXX
SG_ CellVoltage_045 m11 : 30|13@0+ (1,0) [0|8191] "mV" Vector__XXX
SG_ CellVoltage_046 m11 : 33|13@0+ (1,0) [0|8191] "mV" Vector__XXX
SG_ CellVoltage_047 m11 : 52|13@0+ (1,0) [0|8191] "mV" Vector__XXX
SG_ CellVoltage_048_invalidFlag m12 : 12|1@0+ (1,0) [0|1] "" Vector__XXX
SG_ CellVoltage_049_invalidFlag m12 : 13|1@0+ (1,0) [0|1] "" Vector__XXX
SG_ CellVoltage_050_invalidFlag m12 : 14|1@0+ (1,0) [0|1] "" Vector__XXX
SG_ CellVoltage_051_invalidFlag m12 : 15|1@0+ (1,0) [0|1] "" Vector__XXX
SG_ CellVoltage_048 m12 : 11|13@0+ (1,0) [0|8191] "mV" Vector__XXX
SG_ CellVoltage_049 m12 : 30|13@0+ (1,0) [0|8191] "mV" Vector__XXX
SG_ CellVoltage_050 m12 : 33|13@0+ (1,0) [0|8191] "mV" Vector__XXX
SG_ CellVoltage_051 m12 : 52|13@0+ (1,0) [0|8191] "mV" Vector__XXX
SG_ CellVoltage_052_invalidFlag m13 : 12|1@0+ (1,0) [0|1] "" Vector__XXX
SG_ CellVoltage_053_invalidFlag m13 : 13|1@0+ (1,0) [0|1] "" Vector__XXX
SG_ CellVoltage_054_invalidFlag m13 : 14|1@0+ (1,0) [0|1] "" Vector__XXX
SG_ CellVoltage_055_invalidFlag m13 : 15|1@0+ (1,0) [0|1] "" Vector__XXX
SG_ CellVoltage_052 m13 : 11|13@0+ (1,0) [0|8191] "mV" Vector__XXX
SG_ CellVoltage_053 m13 : 30|13@0+ (1,0) [0|8191] "mV" Vector__XXX
SG_ CellVoltage_054 m13 : 33|13@0+ (1,0) [0|8191] "mV" Vector__XXX
SG_ CellVoltage_055 m13 : 52|13@0+ (1,0) [0|8191] "mV" Vector__XXX
SG_ CellVoltage_056_invalidFlag m14 : 12|1@0+ (1,0) [0|1] "" Vector__XXX
SG_ CellVoltage_057_invalidFlag m14 : 13|1@0+ (1,0) [0|1] "" Vector__XXX
SG_ CellVoltage_058_invalidFlag m14 : 14|1@0+ (1,0) [0|1] "" Vector__XXX
SG_ CellVoltage_059_invalidFlag m14 : 15|1@0+ (1,0) [0|1] "" Vector__XXX
SG_ CellVoltage_056 m14 : 11|13@0+ (1,0) [0|8191] "mV" Vector__XXX
SG_ CellVoltage_057 m14 : 30|13@0+ (1,0) [0|8191] "mV" Vector__XXX
SG_ CellVoltage_058 m14 : 33|13@0+ (1,0) [0|8191] "mV" Vector__XXX
SG_ CellVoltage_059 m14 : 52|13@0+ (1,0) [0|8191] "mV" Vector__XXX
SG_ CellVoltage_060_invalidFlag m15 : 12|1@0+ (1,0) [0|1] "" Vector__XXX
SG_ CellVoltage_061_invalidFlag m15 : 13|1@0+ (1,0) [0|1] "" Vector__XXX
SG_ CellVoltage_062_invalidFlag m15 : 14|1@0+ (1,0) [0|1] "" Vector__XXX
SG_ CellVoltage_063_invalidFlag m15 : 15|1@0+ (1,0) [0|1] "" Vector__XXX
SG_ CellVoltage_060 m15 : 11|13@0+ (1,0) [0|8191] "mV" Vector__XXX
SG_ CellVoltage_061 m15 : 30|13@0+ (1,0) [0|8191] "mV" Vector__XXX
SG_ CellVoltage_062 m15 : 33|13@0+ (1,0) [0|8191] "mV" Vector__XXX
SG_ CellVoltage_063 m15 : 52|13@0+ (1,0) [0|8191] "mV" Vector__XXX
SG_ CellVoltage_064_invalidFlag m16 : 12|1@0+ (1,0) [0|1] "" Vector__XXX
SG_ CellVoltage_065_invalidFlag m16 : 13|1@0+ (1,0) [0|1] "" Vector__XXX
SG_ CellVoltage_066_invalidFlag m16 : 14|1@0+ (1,0) [0|1] "" Vector__XXX
SG_ CellVoltage_067_invalidFlag m16 : 15|1@0+ (1,0) [0|1] "" Vector__XXX
SG_ CellVoltage_064 m16 : 11|13@0+ (1,0) [0|8191] "mV" Vector__XXX
SG_ CellVoltage_065 m16 : 30|13@0+ (1,0) [0|8191] "mV" Vector__XXX
SG_ CellVoltage_066 m16 : 33|13@0+ (1,0) [0|8191] "mV" Vector__XXX
SG_ CellVoltage_067 m16 : 52|13@0+ (1,0) [0|8191] "mV" Vector__XXX
SG_ CellVoltage_068_invalidFlag m17 : 12|1@0+ (1,0) [0|1] "" Vector__XXX
SG_ CellVoltage_069_invalidFlag m17 : 13|1@0+ (1,0) [0|1] "" Vector__XXX
SG_ CellVoltage_070_invalidFlag m17 : 14|1@0+ (1,0) [0|1] "" Vector__XXX
SG_ CellVoltage_071_invalidFlag m17 : 15|1@0+ (1,0) [0|1] "" Vector__XXX
SG_ CellVoltage_068 m17 : 11|13@0+ (1,0) [0|8191] "mV" Vector__XXX
SG_ CellVoltage_069 m17 : 30|13@0+ (1,0) [0|8191] "mV" Vector__XXX
SG_ CellVoltage_070 m17 : 33|13@0+ (1,0) [0|8191] "mV" Vector__XXX
SG_ CellVoltage_071 m17 : 52|13@0+ (1,0) [0|8191] "mV" Vector__XXX
SG_ CellVoltage_072_invalidFlag m18 : 12|1@0+ (1,0) [0|1] "" Vector__XXX
SG_ CellVoltage_073_invalidFlag m18 : 13|1@0+ (1,0) [0|1] "" Vector__XXX
SG_ CellVoltage_074_invalidFlag m18 : 14|1@0+ (1,0) [0|1] "" Vector__XXX
SG_ CellVoltage_075_invalidFlag m18 : 15|1@0+ (1,0) [0|1] "" Vector__XXX
SG_ CellVoltage_072 m18 : 11|13@0+ (1,0) [0|8191] "mV" Vector__XXX
SG_ CellVoltage_073 m18 : 30|13@0+ (1,0) [0|8191] "mV" Vector__XXX
SG_ CellVoltage_074 m18 : 33|13@0+ (1,0) [0|8191] "mV" Vector__XXX
SG_ CellVoltage_075 m18 : 52|13@0+ (1,0) [0|8191] "mV" Vector__XXX
SG_ CellVoltage_076_invalidFlag m19 : 12|1@0+ (1,0) [0|1] "" Vector__XXX
SG_ CellVoltage_077_invalidFlag m19 : 13|1@0+ (1,0) [0|1] "" Vector__XXX
SG_ CellVoltage_078_invalidFlag m19 : 14|1@0+ (1,0) [0|1] "" Vector__XXX
SG_ CellVoltage_079_invalidFlag m19 : 15|1@0+ (1,0) [0|1] "" Vector__XXX
SG_ CellVoltage_076 m19 : 11|13@0+ (1,0) [0|8191] "mV" Vector__XXX
SG_ CellVoltage_077 m19 : 30|13@0+ (1,0) [0|8191] "mV" Vector__XXX
SG_ CellVoltage_078 m19 : 33|13@0+ (1,0) [0|8191] "mV" Vector__XXX
SG_ CellVoltage_079 m19 : 52|13@0+ (1,0) [0|8191] "mV" Vector__XXX
SG_ CellVoltage_080_invalidFlag m20 : 12|1@0+ (1,0) [0|1] "" Vector__XXX
SG_ CellVoltage_081_invalidFlag m20 : 13|1@0+ (1,0) [0|1] "" Vector__XXX
SG_ CellVoltage_082_invalidFlag m20 : 14|1@0+ (1,0) [0|1] "" Vector__XXX
SG_ CellVoltage_083_invalidFlag m20 : 15|1@0+ (1,0) [0|1] "" Vector__XXX
SG_ CellVoltage_080 m20 : 11|13@0+ (1,0) [0|8191] "mV" Vector__XXX
SG_ CellVoltage_081 m20 : 30|13@0+ (1,0) [0|8191] "mV" Vector__XXX
SG_ CellVoltage_082 m20 : 33|13@0+ (1,0) [0|8191] "mV" Vector__XXX
SG_ CellVoltage_083 m20 : 52|13@0+ (1,0) [0|8191] "mV" Vector__XXX
SG_ CellVoltage_084_invalidFlag m21 : 12|1@0+ (1,0) [0|1] "" Vector__XXX
SG_ CellVoltage_085_invalidFlag m21 : 13|1@0+ (1,0) [0|1] "" Vector__XXX
SG_ CellVoltage_086_invalidFlag m21 : 14|1@0+ (1,0) [0|1] "" Vector__XXX
SG_ CellVoltage_087_invalidFlag m21 : 15|1@0+ (1,0) [0|1] "" Vector__XXX
SG_ CellVoltage_084 m21 : 11|13@0+ (1,0) [0|8191] "mV" Vector__XXX
SG_ CellVoltage_085 m21 : 30|13@0+ (1,0) [0|8191] "mV" Vector__XXX
SG_ CellVoltage_086 m21 : 33|13@0+ (1,0) [0|8191] "mV" Vector__XXX
SG_ CellVoltage_087 m21 : 52|13@0+ (1,0) [0|8191] "mV" Vector__XXX
SG_ CellVoltage_088_invalidFlag m22 : 12|1@0+ (1,0) [0|1] "" Vector__XXX
SG_ CellVoltage_089_invalidFlag m22 : 13|1@0+ (1,0) [0|1] "" Vector__XXX
SG_ CellVoltage_090_invalidFlag m22 : 14|1@0+ (1,0) [0|1] "" Vector__XXX
SG_ CellVoltage_091_invalidFlag m22 : 15|1@0+ (1,0) [0|1] "" Vector__XXX
SG_ CellVoltage_088 m22 : 11|13@0+ (1,0) [0|8191] "mV" Vector__XXX
SG_ CellVoltage_089 m22 : 30|13@0+ (1,0) [0|8191] "mV" Vector__XXX
SG_ CellVoltage_090 m22 : 33|13@0+ (1,0) [0|8191] "mV" Vector__XXX
SG_ CellVoltage_091 m22 : 52|13@0+ (1,0) [0|8191] "mV" Vector__XXX
SG_ CellVoltage_092_invalidFlag m23 : 12|1@0+ (1,0) [0|1] "" Vector__XXX
SG_ CellVoltage_093_invalidFlag m23 : 13|1@0+ (1,0) [0|1] "" Vector__XXX
SG_ CellVoltage_094_invalidFlag m23 : 14|1@0+ (1,0) [0|1] "" Vector__XXX
SG_ CellVoltage_095_invalidFlag m23 : 15|1@0+ (1,0) [0|1] "" Vector__XXX
SG_ CellVoltage_092 m23 : 11|13@0+ (1,0) [0|8191] "mV" Vector__XXX
SG_ CellVoltage_093 m23 : 30|13@0+ (1,0) [0|8191] "mV" Vector__XXX
SG_ CellVoltage_094 m23 : 33|13@0+ (1,0) [0|8191] "mV" Vector__XXX
SG_ CellVoltage_095 m23 : 52|13@0+ (1,0) [0|8191] "mV" Vector__XXX
SG_ CellVoltage_096_invalidFlag m24 : 12|1@0+ (1,0) [0|1] "" Vector__XXX
SG_ CellVoltage_097_invalidFlag m24 : 13|1@0+ (1,0) [0|1] "" Vector__XXX
SG_ CellVoltage_098_invalidFlag m24 : 14|1@0+ (1,0) [0|1] "" Vector__XXX
SG_ CellVoltage_099_invalidFlag m24 : 15|1@0+ (1,0) [0|1] "" Vector__XXX
SG_ CellVoltage_096 m24 : 11|13@0+ (1,0) [0|8191] "mV" Vector__XXX
SG_ CellVoltage_097 m24 : 30|13@0+ (1,0) [0|8191] "mV" Vector__XXX
SG_ CellVoltage_098 m24 : 33|13@0+ (1,0) [0|8191] "mV" Vector__XXX
SG_ CellVoltage_099 m24 : 52|13@0+ (1,0) [0|8191] "mV" Vector__XXX
SG_ CellVoltage_100_invalidFlag m25 : 12|1@0+ (1,0) [0|1] "" Vector__XXX
SG_ CellVoltage_101_invalidFlag m25 : 13|1@0+ (1,0) [0|1] "" Vector__XXX
SG_ CellVoltage_102_invalidFlag m25 : 14|1@0+ (1,0) [0|1] "" Vector__XXX
SG_ CellVoltage_103_invalidFlag m25 : 15|1@0+ (1,0) [0|1] "" Vector__XXX
SG_ CellVoltage_100 m25 : 11|13@0+ (1,0) [0|8191] "mV" Vector__XXX
SG_ CellVoltage_101 m25 : 30|13@0+ (1,0) [0|8191] "mV" Vector__XXX
SG_ CellVoltage_102 m25 : 33|13@0+ (1,0) [0|8191] "mV" Vector__XXX
SG_ CellVoltage_103 m25 : 52|13@0+ (1,0) [0|8191] "mV" Vector__XXX
SG_ CellVoltage_104_invalidFlag m26 : 12|1@0+ (1,0) [0|1] "" Vector__XXX
SG_ CellVoltage_105_invalidFlag m26 : 13|1@0+ (1,0) [0|1] "" Vector__XXX
SG_ CellVoltage_106_invalidFlag m26 : 14|1@0+ (1,0) [0|1] "" Vector__XXX
SG_ CellVoltage_107_invalidFlag m26 : 15|1@0+ (1,0) [0|1] "" Vector__XXX
SG_ CellVoltage_104 m26 : 11|13@0+ (1,0) [0|8191] "mV" Vector__XXX
SG_ CellVoltage_105 m26 : 30|13@0+ (1,0) [0|8191] "mV" Vector__XXX
SG_ CellVoltage_106 m26 : 33|13@0+ (1,0) [0|8191] "mV" Vector__XXX
SG_ CellVoltage_107 m26 : 52|13@0+ (1,0) [0|8191] "mV" Vector__XXX
SG_ CellVoltage_108_invalidFlag m27 : 12|1@0+ (1,0) [0|1] "" Vector__XXX
SG_ CellVoltage_109_invalidFlag m27 : 13|1@0+ (1,0) [0|1] "" Vector__XXX
SG_ CellVoltage_110_invalidFlag m27 : 14|1@0+ (1,0) [0|1] "" Vector__XXX
SG_ CellVoltage_111_invalidFlag m27 : 15|1@0+ (1,0) [0|1] "" Vector__XXX
SG_ CellVoltage_108 m27 : 11|13@0+ (1,0) [0|8191] "mV" Vector__XXX
SG_ CellVoltage_109 m27 : 30|13@0+ (1,0) [0|8191] "mV" Vector__XXX
SG_ CellVoltage_110 m27 : 33|13@0+ (1,0) [0|8191] "mV" Vector__XXX
SG_ CellVoltage_111 m27 : 52|13@0+ (1,0) [0|8191] "mV" Vector__XXX
SG_ CellVoltage_112_invalidFlag m28 : 12|1@0+ (1,0) [0|1] "" Vector__XXX
SG_ CellVoltage_113_invalidFlag m28 : 13|1@0+ (1,0) [0|1] "" Vector__XXX
SG_ CellVoltage_114_invalidFlag m28 : 14|1@0+ (1,0) [0|1] "" Vector__XXX
SG_ CellVoltage_115_invalidFlag m28 : 15|1@0+ (1,0) [0|1] "" Vector__XXX
SG_ CellVoltage_112 m28 : 11|13@0+ (1,0) [0|8191] "mV" Vector__XXX
SG_ CellVoltage_113 m28 : 30|13@0+ (1,0) [0|8191] "mV" Vector__XXX
SG_ CellVoltage_114 m28 : 33|13@0+ (1,0) [0|8191] "mV" Vector__XXX
SG_ CellVoltage_115 m28 : 52|13@0+ (1,0) [0|8191] "mV" Vector__XXX
SG_ CellVoltage_116_invalidFlag m29 : 12|1@0+ (1,0) [0|1] "" Vector__XXX
SG_ CellVoltage_117_invalidFlag m29 : 13|1@0+ (1,0) [0|1] "" Vector__XXX
SG_ CellVoltage_118_invalidFlag m29 : 14|1@0+ (1,0) [0|1] "" Vector__XXX
SG_ CellVoltage_119_invalidFlag m29 : 15|1@0+ (1,0) [0|1] "" Vector__XXX
SG_ CellVoltage_116 m29 : 11|13@0+ (1,0) [0|8191] "mV" Vector__XXX
SG_ CellVoltage_117 m29 : 30|13@0+ (1,0) [0|8191] "mV" Vector__XXX
SG_ CellVoltage_118 m29 : 33|13@0+ (1,0) [0|8191] "mV" Vector__XXX
SG_ CellVoltage_119 m29 : 52|13@0+ (1,0) [0|8191] "mV" Vector__XXX
SG_ CellVoltage_120_invalidFlag m30 : 12|1@0+ (1,0) [0|1] "" Vector__XXX
SG_ CellVoltage_121_invalidFlag m30 : 13|1@0+ (1,0) [0|1] "" Vector__XXX
SG_ CellVoltage_122_invalidFlag m30 : 14|1@0+ (1,0) [0|1] "" Vector__XXX
SG_ CellVoltage_123_invalidFlag m30 : 15|1@0+ (1,0) [0|1] "" Vector__XXX
SG_ CellVoltage_120 m30 : 11|13@0+ (1,0) [0|8191] "mV" Vector__XXX
SG_ CellVoltage_121 m30 : 30|13@0+ (1,0) [0|8191] "mV" Vector__XXX
SG_ CellVoltage_122 m30 : 33|13@0+ (1,0) [0|8191] "mV" Vector__XXX
SG_ CellVoltage_123 m30 : 52|13@0+ (1,0) [0|8191] "mV" Vector__XXX
SG_ CellVoltage_124_invalidFlag m31 : 12|1@0+ (1,0) [0|1] "" Vector__XXX
SG_ CellVoltage_125_invalidFlag m31 : 13|1@0+ (1,0) [0|1] "" Vector__XXX
SG_ CellVoltage_126_invalidFlag m31 : 14|1@0+ (1,0) [0|1] "" Vector__XXX
SG_ CellVoltage_127_invalidFlag m31 : 15|1@0+ (1,0) [0|1] "" Vector__XXX
SG_ CellVoltage_124 m31 : 11|13@0+ (1,0) [0|8191] "mV" Vector__XXX
SG_ CellVoltage_125 m31 : 30|13@0+ (1,0) [0|8191] "mV" Vector__XXX
SG_ CellVoltage_126 m31 : 33|13@0+ (1,0) [0|8191] "mV" Vector__XXX
SG_ CellVoltage_127 m31 : 52|13@0+ (1,0) [0|8191] "mV" Vector__XXX
SG_ CellVoltage_128_invalidFlag m32 : 12|1@0+ (1,0) [0|1] "" Vector__XXX
SG_ CellVoltage_129_invalidFlag m32 : 13|1@0+ (1,0) [0|1] "" Vector__XXX
SG_ CellVoltage_130_invalidFlag m32 : 14|1@0+ (1,0) [0|1] "" Vector__XXX
SG_ CellVoltage_131_invalidFlag m32 : 15|1@0+ (1,0) [0|1] "" Vector__XXX
SG_ CellVoltage_128 m32 : 11|13@0+ (1,0) [0|8191] "mV" Vector__XXX
SG_ CellVoltage_129 m32 : 30|13@0+ (1,0) [0|8191] "mV" Vector__XXX
SG_ CellVoltage_130 m32 : 33|13@0+ (1,0) [0|8191] "mV" Vector__XXX
SG_ CellVoltage_131 m32 : 52|13@0+ (1,0) [0|8191] "mV" Vector__XXX
SG_ CellVoltage_132_invalidFlag m33 : 12|1@0+ (1,0) [0|1] "" Vector__XXX
SG_ CellVoltage_133_invalidFlag m33 : 13|1@0+ (1,0) [0|1] "" Vector__XXX
SG_ CellVoltage_134_invalidFlag m33 : 14|1@0+ (1,0) [0|1] "" Vector__XXX
SG_ CellVoltage_135_invalidFlag m33 : 15|1@0+ (1,0) [0|1] "" Vector__XXX
SG_ CellVoltage_132 m33 : 11|13@0+ (1,0) [0|8191] "mV" Vector__XXX
SG_ CellVoltage_133 m33 : 30|13@0+ (1,0) [0|8191] "mV" Vector__XXX
SG_ CellVoltage_134 m33 : 33|13@0+ (1,0) [0|8191] "mV" Vector__XXX
SG_ CellVoltage_135 m33 : 52|13@0+ (1,0) [0|8191] "mV" Vector__XXX
SG_ CellVoltage_136_invalidFlag m34 : 12|1@0+ (1,0) [0|1] "" Vector__XXX
SG_ CellVoltage_137_invalidFlag m34 : 13|1@0+ (1,0) [0|1] "" Vector__XXX
SG_ CellVoltage_138_invalidFlag m34 : 14|1@0+ (1,0) [0|1] "" Vector__XXX
SG_ CellVoltage_139_invalidFlag m34 : 15|1@0+ (1,0) [0|1] "" Vector__XXX
SG_ CellVoltage_136 m34 : 11|13@0+ (1,0) [0|8191] "mV" Vector__XXX
SG_ CellVoltage_137 m34 : 30|13@0+ (1,0) [0|8191] "mV" Vector__XXX
SG_ CellVoltage_138 m34 : 33|13@0+ (1,0) [0|8191] "mV" Vector__XXX
SG_ CellVoltage_139 m34 : 52|13@0+ (1,0) [0|8191] "mV" Vector__XXX
SG_ CellVoltage_140_invalidFlag m35 : 12|1@0+ (1,0) [0|1] "" Vector__XXX
SG_ CellVoltage_141_invalidFlag m35 : 13|1@0+ (1,0) [0|1] "" Vector__XXX
SG_ CellVoltage_142_invalidFlag m35 : 14|1@0+ (1,0) [0|1] "" Vector__XXX
SG_ CellVoltage_143_invalidFlag m35 : 15|1@0+ (1,0) [0|1] "" Vector__XXX
SG_ CellVoltage_140 m35 : 11|13@0+ (1,0) [0|8191] "mV" Vector__XXX
SG_ CellVoltage_141 m35 : 30|13@0+ (1,0) [0|8191] "mV" Vector__XXX
SG_ CellVoltage_142 m35 : 33|13@0+ (1,0) [0|8191] "mV" Vector__XXX
SG_ CellVoltage_143 m35 : 52|13@0+ (1,0) [0|8191] "mV" Vector__XXX
SG_ CellVoltage_144_invalidFlag m36 : 12|1@0+ (1,0) [0|1] "" Vector__XXX
SG_ CellVoltage_145_invalidFlag m36 : 13|1@0+ (1,0) [0|1] "" Vector__XXX
SG_ CellVoltage_146_invalidFlag m36 : 14|1@0+ (1,0) [0|1] "" Vector__XXX
SG_ CellVoltage_147_invalidFlag m36 : 15|1@0+ (1,0) [0|1] "" Vector__XXX
SG_ CellVoltage_144 m36 : 11|13@0+ (1,0) [0|8191] "mV" Vector__XXX
SG_ CellVoltage_145 m36 : 30|13@0+ (1,0) [0|8191] "mV" Vector__XXX
SG_ CellVoltage_146 m36 : 33|13@0+ (1,0) [0|8191] "mV" Vector__XXX
SG_ CellVoltage_147 m36 : 52|13@0+ (1,0) [0|8191] "mV" Vector__XXX
SG_ CellVoltage_148_invalidFlag m37 : 12|1@0+ (1,0) [0|1] "" Vector__XXX
SG_ CellVoltage_149_invalidFlag m37 : 13|1@0+ (1,0) [0|1] "" Vector__XXX
SG_ CellVoltage_150_invalidFlag m37 : 14|1@0+ (1,0) [0|1] "" Vector__XXX
SG_ CellVoltage_151_invalidFlag m37 : 15|1@0+ (1,0) [0|1] "" Vector__XXX
SG_ CellVoltage_148 m37 : 11|13@0+ (1,0) [0|8191] "mV" Vector__XXX
SG_ CellVoltage_149 m37 : 30|13@0+ (1,0) [0|8191] "mV" Vector__XXX
SG_ CellVoltage_150 m37 : 33|13@0+ (1,0) [0|8191] "mV" Vector__XXX
SG_ CellVoltage_151 m37 : 52|13@0+ (1,0) [0|8191] "mV" Vector__XXX
SG_ CellVoltage_152_invalidFlag m38 : 12|1@0+ (1,0) [0|1] "" Vector__XXX
SG_ CellVoltage_153_invalidFlag m38 : 13|1@0+ (1,0) [0|1] "" Vector__XXX
SG_ CellVoltage_154_invalidFlag m38 : 14|1@0+ (1,0) [0|1] "" Vector__XXX
SG_ CellVoltage_155_invalidFlag m38 : 15|1@0+ (1,0) [0|1] "" Vector__XXX
SG_ CellVoltage_152 m38 : 11|13@0+ (1,0) [0|8191] "mV" Vector__XXX
SG_ CellVoltage_153 m38 : 30|13@0+ (1,0) [0|8191] "mV" Vector__XXX
SG_ CellVoltage_154 m38 : 33|13@0+ (1,0) [0|8191] "mV" Vector__XXX
SG_ CellVoltage_155 m38 : 52|13@0+ (1,0) [0|8191] "mV" Vector__XXX
SG_ CellVoltage_156_invalidFlag m39 : 12|1@0+ (1,0) [0|1] "" Vector__XXX
SG_ CellVoltage_157_invalidFlag m39 : 13|1@0+ (1,0) [0|1] "" Vector__XXX
SG_ CellVoltage_158_invalidFlag m39 : 14|1@0+ (1,0) [0|1] "" Vector__XXX
SG_ CellVoltage_159_invalidFlag m39 : 15|1@0+ (1,0) [0|1] "" Vector__XXX
SG_ CellVoltage_156 m39 : 11|13@0+ (1,0) [0|8191] "mV" Vector__XXX
SG_ CellVoltage_157 m39 : 30|13@0+ (1,0) [0|8191] "mV" Vector__XXX
SG_ CellVoltage_158 m39 : 33|13@0+ (1,0) [0|8191] "mV" Vector__XXX
SG_ CellVoltage_159 m39 : 52|13@0+ (1,0) [0|8191] "mV" Vector__XXX
SG_ CellVoltage_160_invalidFlag m40 : 12|1@0+ (1,0) [0|1] "" Vector__XXX
SG_ CellVoltage_161_invalidFlag m40 : 13|1@0+ (1,0) [0|1] "" Vector__XXX
SG_ CellVoltage_162_invalidFlag m40 : 14|1@0+ (1,0) [0|1] "" Vector__XXX
SG_ CellVoltage_163_invalidFlag m40 : 15|1@0+ (1,0) [0|1] "" Vector__XXX
SG_ CellVoltage_160 m40 : 11|13@0+ (1,0) [0|8191] "mV" Vector__XXX
SG_ CellVoltage_161 m40 : 30|13@0+ (1,0) [0|8191] "mV" Vector__XXX
SG_ CellVoltage_162 m40 : 33|13@0+ (1,0) [0|8191] "mV" Vector__XXX
SG_ CellVoltage_163 m40 : 52|13@0+ (1,0) [0|8191] "mV" Vector__XXX
SG_ CellVoltage_164_invalidFlag m41 : 12|1@0+ (1,0) [0|1] "" Vector__XXX
SG_ CellVoltage_165_invalidFlag m41 : 13|1@0+ (1,0) [0|1] "" Vector__XXX
SG_ CellVoltage_166_invalidFlag m41 : 14|1@0+ (1,0) [0|1] "" Vector__XXX
SG_ CellVoltage_167_invalidFlag m41 : 15|1@0+ (1,0) [0|1] "" Vector__XXX
SG_ CellVoltage_164 m41 : 11|13@0+ (1,0) [0|8191] "mV" Vector__XXX
SG_ CellVoltage_165 m41 : 30|13@0+ (1,0) [0|8191] "mV" Vector__XXX
SG_ CellVoltage_166 m41 : 33|13@0+ (1,0) [0|8191] "mV" Vector__XXX
SG_ CellVoltage_167 m41 : 52|13@0+ (1,0) [0|8191] "mV" Vector__XXX
SG_ CellVoltage_168_invalidFlag m42 : 12|1@0+ (1,0) [0|1] "" Vector__XXX
SG_ CellVoltage_169_invalidFlag m42 : 13|1@0+ (1,0) [0|1] "" Vector__XXX
SG_ CellVoltage_170_invalidFlag m42 : 14|1@0+ (1,0) [0|1] "" Vector__XXX
SG_ CellVoltage_171_invalidFlag m42 : 15|1@0+ (1,0) [0|1] "" Vector__XXX
SG_ CellVoltage_168 m42 : 11|13@0+ (1,0) [0|8191] "mV" Vector__XXX
SG_ CellVoltage_169 m42 : 30|13@0+ (1,0) [0|8191] "mV" Vector__XXX
SG_ CellVoltage_170 m42 : 33|13@0+ (1,0) [0|8191] "mV" Vector__XXX
SG_ CellVoltage_171 m42 : 52|13@0+ (1,0) [0|8191] "mV" Vector__XXX
SG_ CellVoltage_172_invalidFlag m43 : 12|1@0+ (1,0) [0|1] "" Vector__XXX
SG_ CellVoltage_173_invalidFlag m43 : 13|1@0+ (1,0) [0|1] "" Vector__XXX
SG_ CellVoltage_174_invalidFlag m43 : 14|1@0+ (1,0) [0|1] "" Vector__XXX
SG_ CellVoltage_175_invalidFlag m43 : 15|1@0+ (1,0) [0|1] "" Vector__XXX
SG_ CellVoltage_172 m43 : 11|13@0+ (1,0) [0|8191] "mV" Vector__XXX
SG_ CellVoltage_173 m43 : 30|13@0+ (1,0) [0|8191] "mV" Vector__XXX
SG_ CellVoltage_174 m43 : 33|13@0+ (1,0) [0|8191] "mV" Vector__XXX
SG_ CellVoltage_175 m43 : 52|13@0+ (1,0) [0|8191] "mV" Vector__XXX
SG_ CellVoltage_176_invalidFlag m44 : 12|1@0+ (1,0) [0|1] "" Vector__XXX
SG_ CellVoltage_177_invalidFlag m44 : 13|1@0+ (1,0) [0|1] "" Vector__XXX
SG_ CellVoltage_178_invalidFlag m44 : 14|1@0+ (1,0) [0|1] "" Vector__XXX
SG_ CellVoltage_179_invalidFlag m44 : 15|1@0+ (1,0) [0|1] "" Vector__XXX
SG_ CellVoltage_176 m44 : 11|13@0+ (1,0) [0|8191] "mV" Vector__XXX
SG_ CellVoltage_177 m44 : 30|13@0+ (1,0) [0|8191] "mV" Vector__XXX
SG_ CellVoltage_178 m44 : 33|13@0+ (1,0) [0|8191] "mV" Vector__XXX
SG_ CellVoltage_179 m44 : 52|13@0+ (1,0) [0|8191] "mV" Vector__XXX
SG_ CellVoltage_180_invalidFlag m45 : 12|1@0+ (1,0) [0|1] "" Vector__XXX
SG_ CellVoltage_181_invalidFlag m45 : 13|1@0+ (1,0) [0|1] "" Vector__XXX
SG_ CellVoltage_182_invalidFlag m45 : 14|1@0+ (1,0) [0|1] "" Vector__XXX
SG_ CellVoltage_183_invalidFlag m45 : 15|1@0+ (1,0) [0|1] "" Vector__XXX
SG_ CellVoltage_180 m45 : 11|13@0+ (1,0) [0|8191] "mV" Vector__XXX
SG_ CellVoltage_181 m45 : 30|13@0+ (1,0) [0|8191] "mV" Vector__XXX
SG_ CellVoltage_182 m45 : 33|13@0+ (1,0) [0|8191] "mV" Vector__XXX
SG_ CellVoltage_183 m45 : 52|13@0+ (1,0) [0|8191] "mV" Vector__XXX
SG_ CellVoltage_184_invalidFlag m46 : 12|1@0+ (1,0) [0|1] "" Vector__XXX
SG_ CellVoltage_185_invalidFlag m46 : 13|1@0+ (1,0) [0|1] "" Vector__XXX
SG_ CellVoltage_186_invalidFlag m46 : 14|1@0+ (1,0) [0|1] "" Vector__XXX
SG_ CellVoltage_187_invalidFlag m46 : 15|1@0+ (1,0) [0|1] "" Vector__XXX
SG_ CellVoltage_184 m46 : 11|13@0+ (1,0) [0|8191] "mV" Vector__XXX
SG_ CellVoltage_185 m46 : 30|13@0+ (1,0) [0|8191] "mV" Vector__XXX
SG_ CellVoltage_186 m46 : 33|13@0+ (1,0) [0|8191] "mV" Vector__XXX
SG_ CellVoltage_187 m46 : 52|13@0+ (1,0) [0|8191] "mV" Vector__XXX
SG_ CellVoltage_188_invalidFlag m47 : 12|1@0+ (1,0) [0|1] "" Vector__XXX
SG_ CellVoltage_189_invalidFlag m47 : 13|1@0+ (1,0) [0|1] "" Vector__XXX
SG_ CellVoltage_190_invalidFlag m47 : 14|1@0+ (1,0) [0|1] "" Vector__XXX
SG_ CellVoltage_191_invalidFlag m47 : 15|1@0+ (1,0) [0|1] "" Vector__XXX
SG_ CellVoltage_188 m47 : 11|13@0+ (1,0) [0|8191] "mV" Vector__XXX
SG_ CellVoltage_189 m47 : 30|13@0+ (1,0) [0|8191] "mV" Vector__XXX
SG_ CellVoltage_190 m47 : 33|13@0+ (1,0) [0|8191] "mV" Vector__XXX
SG_ CellVoltage_191 m47 : 52|13@0+ (1,0) [0|8191] "mV" Vector__XXX
SG_ CellVoltage_192_invalidFlag m48 : 12|1@0+ (1,0) [0|1] "" Vector__XXX
SG_ CellVoltage_193_invalidFlag m48 : 13|1@0+ (1,0) [0|1] "" Vector__XXX
SG_ CellVoltage_194_invalidFlag m48 : 14|1@0+ (1,0) [0|1] "" Vector__XXX
SG_ CellVoltage_195_invalidFlag m48 : 15|1@0+ (1,0) [0|1] "" Vector__XXX
SG_ CellVoltage_192 m48 : 11|13@0+ (1,0) [0|8191] "mV" Vector__XXX
SG_ CellVoltage_193 m48 : 30|13@0+ (1,0) [0|8191] "mV" Vector__XXX
SG_ CellVoltage_194 m48 : 33|13@0+ (1,0) [0|8191] "mV" Vector__XXX
SG_ CellVoltage_195 m48 : 52|13@0+ (1,0) [0|8191] "mV" Vector__XXX
SG_ CellVoltage_196_invalidFlag m49 : 12|1@0+ (1,0) [0|1] "" Vector__XXX
SG_ CellVoltage_197_invalidFlag m49 : 13|1@0+ (1,0) [0|1] "" Vector__XXX
SG_ CellVoltage_198_invalidFlag m49 : 14|1@0+ (1,0) [0|1] "" Vector__XXX
SG_ CellVoltage_199_invalidFlag m49 : 15|1@0+ (1,0) [0|1] "" Vector__XXX
SG_ CellVoltage_196 m49 : 11|13@0+ (1,0) [0|8191] "mV" Vector__XXX
SG_ CellVoltage_197 m49 : 30|13@0+ (1,0) [0|8191] "mV" Vector__XXX
SG_ CellVoltage_198 m49 : 33|13@0+ (1,0) [0|8191] "mV" Vector__XXX
SG_ CellVoltage_199 m49 : 52|13@0+ (1,0) [0|8191] "mV" Vector__XXX
SG_ CellVoltage_200_invalidFlag m50 : 12|1@0+ (1,0) [0|1] "" Vector__XXX
SG_ CellVoltage_201_invalidFlag m50 : 13|1@0+ (1,0) [0|1] "" Vector__XXX
SG_ CellVoltage_202_invalidFlag m50 : 14|1@0+ (1,0) [0|1] "" Vector__XXX
SG_ CellVoltage_203_invalidFlag m50 : 15|1@0+ (1,0) [0|1] "" Vector__XXX
SG_ CellVoltage_200 m50 : 11|13@0+ (1,0) [0|8191] "mV" Vector__XXX
SG_ CellVoltage_201 m50 : 30|13@0+ (1,0) [0|8191] "mV" Vector__XXX
SG_ CellVoltage_202 m50 : 33|13@0+ (1,0) [0|8191] "mV" Vector__XXX
SG_ CellVoltage_203 m50 : 52|13@0+ (1,0) [0|8191] "mV" Vector__XXX
SG_ CellVoltage_204_invalidFlag m51 : 12|1@0+ (1,0) [0|1] "" Vector__XXX
SG_ CellVoltage_205_invalidFlag m51 : 13|1@0+ (1,0) [0|1] "" Vector__XXX
SG_ CellVoltage_206_invalidFlag m51 : 14|1@0+ (1,0) [0|1] "" Vector__XXX
SG_ CellVoltage_207_invalidFlag m51 : 15|1@0+ (1,0) [0|1] "" Vector__XXX
SG_ CellVoltage_204 m51 : 11|13@0+ (1,0) [0|8191] "mV" Vector__XXX
SG_ CellVoltage_205 m51 : 30|13@0+ (1,0) [0|8191] "mV" Vector__XXX
SG_ CellVoltage_206 m51 : 33|13@0+ (1,0) [0|8191] "mV" Vector__XXX
SG_ CellVoltage_207 m51 : 52|13@0+ (1,0) [0|8191] "mV" Vector__XXX
SG_ CellVoltage_208_invalidFlag m52 : 12|1@0+ (1,0) [0|1] "" Vector__XXX
SG_ CellVoltage_209_invalidFlag m52 : 13|1@0+ (1,0) [0|1] "" Vector__XXX
SG_ CellVoltage_210_invalidFlag m52 : 14|1@0+ (1,0) [0|1] "" Vector__XXX
SG_ CellVoltage_211_invalidFlag m52 : 15|1@0+ (1,0) [0|1] "" Vector__XXX
SG_ CellVoltage_208 m52 : 11|13@0+ (1,0) [0|8191] "mV" Vector__XXX
SG_ CellVoltage_209 m52 : 30|13@0+ (1,0) [0|8191] "mV" Vector__XXX
SG_ CellVoltage_210 m52 : 33|13@0+ (1,0) [0|8191] "mV" Vector__XXX
SG_ CellVoltage_211 m52 : 52|13@0+ (1,0) [0|8191] "mV" Vector__XXX
SG_ CellVoltage_212_invalidFlag m53 : 12|1@0+ (1,0) [0|1] "" Vector__XXX
SG_ CellVoltage_213_invalidFlag m53 : 13|1@0+ (1,0) [0|1] "" Vector__XXX
SG_ CellVoltage_214_invalidFlag m53 : 14|1@0+ (1,0) [0|1] "" Vector__XXX
SG_ CellVoltage_215_invalidFlag m53 : 15|1@0+ (1,0) [0|1] "" Vector__XXX
SG_ CellVoltage_212 m53 : 11|13@0+ (1,0) [0|8191] "mV" Vector__XXX
SG_ CellVoltage_213 m53 : 30|13@0+ (1,0) [0|8191] "mV" Vector__XXX
SG_ CellVoltage_214 m53 : 33|13@0+ (1,0) [0|8191] "mV" Vector__XXX
SG_ CellVoltage_215 m53 : 52|13@0+ (1,0) [0|8191] "mV" Vector__XXX

BO_ 255 f_CrashDump: 8 Vector__XXX
SG_ f_CrashDump_Mux M : 7|8@0+ (1,0) [0|0] "" Vector__XXX

BO_ 768 f_Debug: 8 Vector__XXX
SG_ f_Debug_Mux M : 7|8@0+ (1,0) [0|0] "" Vector__XXX
SG_ SetHundredthOfSeconds m1 : 15|7@0+ (1,0) [0|127] "" Vector__XXX
SG_ SetSeconds m1 : 8|6@0+ (1,0) [0|63] "" Vector__XXX
SG_ SetMinutes m1 : 18|6@0+ (1,0) [0|63] "" Vector__XXX
SG_ SetHours m1 : 28|5@0+ (1,0) [0|31] "" Vector__XXX
SG_ SetWeekday m1 : 39|3@0+ (1,0) [0|7] "" Vector__XXX
SG_ SetDay m1 : 36|5@0+ (1,0) [0|31] "" Vector__XXX
SG_ SetMonth m1 : 47|4@0+ (1,0) [0|15] "" Vector__XXX
SG_ SetYear m1 : 43|7@0+ (1,0) [0|127] "" Vector__XXX
SG_ GetMcuLotNumber m0 : 10|1@0+ (1,0) [0|1] "" Vector__XXX
SG_ GetBmsSoftwareVersion m0 : 8|1@0+ (1,0) [0|1] "" Vector__XXX
SG_ GetMcuUniqueDieId m0 : 9|1@0+ (1,0) [0|1] "" Vector__XXX
SG_ GetMcuWaferInformation m0 : 11|1@0+ (1,0) [0|1] "" Vector__XXX
SG_ GetCommitHash m0 : 12|1@1+ (1,0) [0|1] "" Vector__XXX
SG_ GetBuildConfiguration m0 : 13|1@0+ (1,0) [0|1] "" Vector__XXX
SG_ TriggerSoftwareReset m2 : 39|1@0+ (1,0) [0|1] "" Vector__XXX
SG_ InitializeFram m3 : 27|1@0+ (1,0) [0|1] "" Vector__XXX
SG_ RequestRtcTime m4 : 8|1@0+ (1,0) [0|1] "" Vector__XXX
SG_ RequestBootTimestamp m4 : 9|1@1+ (1,0) [0|1] "" Vector__XXX
SG_ RequestUptime m5 : 16|1@0+ (1,0) [0|1] "" Vector__XXX
SG_ FramCalibrationChannel m11 : 15|8@0+ (1,0) [0|255] "" Vector__XXX
SG_ CalibrationValue11 m11 : 39|32@0- (0.0001,0) [-214748.3648|214748.3647] "" Vector__XXX
SG_ RequestIdentifyHardware m7 : 15|1@1+ (1,0) [0|1] "" Vector__XXX
SG_ CalibrationChannel9 m9 : 15|8@0+ (1,0) [0|255] "" Vector__XXX
SG_ CalibrationChannel8 m8 : 15|8@0+ (1,0) [0|255] "" Vector__XXX
SG_ CalibrationChannel10 m10 : 15|8@0+ (1,0) [0|255] "" Vector__XXX
SG_ CalibrationValue10 m10 : 39|32@0- (0.0001,0) [-214748.3648|214748.3647] "" Vector__XXX

BO_ 771 f_DebugBuildConfiguration: 8 Vector__XXX
SG_ f_DebugBuildConfiguration_Mux M : 0|8@1+ (1,0) [0|0] "" Vector__XXX
SG_ MaxDischargeTemperature_MSL m36 : 15|18@0- (0.1,0) [-13107.2|13107.1] "degC" Vector__XXX
SG_ MaxDischargeTemperature_RSL m36 : 29|18@0- (0.1,0) [-13107.2|13107.1] "degC" Vector__XXX
SG_ MaxdischargeTemperature_MOL m36 : 43|18@0- (0.1,0) [-13107.2|13107.1] "degC" Vector__XXX
SG_ MinDischargeTemperature_MSL m39 : 15|18@0- (0.1,0) [-13107.2|13107.1] "degC" Vector__XXX
SG_ MinDischargeTemperature_RSL m39 : 29|18@0- (0.1,0) [-13107.2|13107.1] "degC" Vector__XXX
SG_ MinDischargeTemperature_MOL m39 : 43|18@0- (0.1,0) [-13107.2|13107.1] "degC" Vector__XXX
SG_ MaxChargeTemperature_MSL m34 : 15|18@0- (0.1,0) [-13107.2|13107.1] "degC" Vector__XXX
SG_ MaxChargeTemperature_RSL m34 : 29|18@0- (0.1,0) [-13107.2|13107.1] "degC" Vector__XXX
SG_ MaxChargeTemperature_MOL m34 : 43|18@0- (0.1,0) [-13107.2|13107.1] "degC" Vector__XXX
SG_ MinChargeTemperature_MSL m38 : 15|18@0- (0.1,0) [-13107.2|13107.1] "degC" Vector__XXX
SG_ MinChargeTemperature_RSL m38 : 29|18@0- (0.1,0) [-13107.2|13107.1] "degC" Vector__XXX
SG_ MinChargeTemperature_MOL m38 : 43|18@0- (0.1,0) [-13107.2|13107.1] "degC" Vector__XXX
SG_ MaxVoltage_MSL m37 : 15|18@0- (1,0) [0|1] "mV" Vector__XXX
SG_ MaxVoltage_RSL m37 : 29|18@0- (1,0) [0|1] "mV" Vector__XXX
SG_ MaxVoltage_MOL m37 : 43|18@0- (1,0) [0|1] "mV" Vector__XXX
SG_ MinVoltage_MSL m40 : 15|18@0- (1,0) [0|1] "mV" Vector__XXX
SG_ MinVoltage_RSL m40 : 29|18@0- (1,0) [0|1] "mV" Vector__XXX
SG_ MinVoltge_MOL m40 : 43|18@0- (1,0) [0|1] "mV" Vector__XXX
SG_ NominalCellVoltage m32 : 15|16@0+ (1,0) [0|1] "mV" Vector__XXX
SG_ DeepDischargeCellVoltage m32 : 31|16@0+ (1,0) [0|1] "mV" Vector__XXX
SG_ CellCapacity m32 : 47|16@0+ (1,0) [0|1] "mAh" Vector__XXX
SG_ CellEnergy m32 : 63|8@0+ (1,0) [0|1] "Wh" Vector__XXX
SG_ MaxChargeCurrent_MSL m33 : 15|18@0+ (1,0) [0|262143] "mA" Vector__XXX
SG_ MaxChargeCurrent_RSL m33 : 29|18@0+ (1,0) [0|1] "mA" Vector__XXX
SG_ MaxChargeCurrent_MOL m33 : 43|18@0+ (1,0) [0|1] "mA" Vector__XXX
SG_ MaxDischargeCurrent_MSL m35 : 15|18@0+ (1,0) [0|1] "mA" Vector__XXX
SG_ MaxDischargeCurrent_RSL m35 : 29|18@0+ (1,0) [0|1] "mA" Vector__XXX
SG_ MaxDischargeCurrent_MOL m35 : 43|18@0+ (1,0) [0|1] "mA" Vector__XXX
SG_ NrOfStrings m48 : 15|8@0+ (1,0) [0|1] "" Vector__XXX
SG_ NrOfModulesPerString m48 : 23|8@0+ (1,0) [0|1] "" Vector__XXX
SG_ NrOfCellBlocksPerModule m48 : 31|8@0+ (1,0) [0|1] "" Vector__XXX
SG_ NrOfParallelCellsPerCellBlock m48 : 39|8@0+ (1,0) [0|1] "" Vector__XXX
SG_ NrOfGpiosPerModule m48 : 47|8@0+ (1,0) [0|1] "" Vector__XXX
SG_ NrOfGpasPerModule m48 : 55|8@0+ (1,0) [0|1] "" Vector__XXX
SG_ NrOfTemperatureSensorsPerModule m48 : 63|8@0+ (1,0) [0|1] "" Vector__XXX
SG_ NrOfCellBlocksPerString m55 : 15|14@0+ (1,0) [0|1] "" Vector__XXX
SG_ NrOfCellBlocks m55 : 17|14@0+ (1,0) [0|1] "" Vector__XXX
SG_ NrOfTempSensorsPerString m55 : 35|14@0+ (1,0) [0|1] "" Vector__XXX
SG_ NrOfTempSensors m55 : 53|14@0+ (1,0) [0|1] "" Vector__XXX
SG_ CurrentMeasurementTimeout m51 : 11|12@0+ (1,0) [0|1] "ms" Vector__XXX
SG_ CoulombCountingMeasurementTimeou m51 : 31|12@0+ (1,0) [0|1] "ms" Vector__XXX
SG_ EnergyCountingMeasurementTimeout m51 : 35|12@0+ (1,0) [0|1] "ms" Vector__XXX
SG_ ThresholdNoCurrent m51 : 55|12@0+ (1,0) [0|1] "mA" Vector__XXX
SG_ MainContactorsMaxBreakCurrent m50 : 31|32@0+ (1,0) [0|1] "mA" Vector__XXX
SG_ NrOfContactors m50 : 23|8@0+ (1,0) [0|1] "" Vector__XXX
SG_ NrOfContactorsOutsideStrings m50 : 15|8@0+ (1,0) [0|1] "" Vector__XXX
SG_ CheckFusePlacedInChargePath m52 : 15|1@0+ (1,0) [0|1] "" Vector__XXX
SG_ CheckFusePlacedInNormalPath m52 : 14|1@0+ (1,0) [0|1] "" Vector__XXX
SG_ MaxVoltageDropOverFuse m52 : 11|12@0+ (1,0) [0|1] "mV" Vector__XXX
SG_ MainFuseMaximumTriggerDuration m52 : 31|16@0+ (1,0) [0|1] "ms" Vector__XXX
SG_ PositiveDischargeCurrent m49 : 15|1@0+ (1,0) [0|1] "" Vector__XXX
SG_ IgnoreInterlockFeedback m49 : 14|1@1+ (1,0) [0|1] "" Vector__XXX
SG_ CheckCanTiming m49 : 13|1@1+ (1,0) [0|1] "" Vector__XXX
SG_ BalancingDefaultInactive m49 : 12|1@1+ (1,0) [0|1] "" Vector__XXX
SG_ BalancingResistance m49 : 11|12@0+ (1,0) [0|1] "Ohm" Vector__XXX
SG_ RestCurrent m49 : 31|12@0+ (1,0) [0|1] "mA" Vector__XXX
SG_ RelaxationPeriod m49 : 35|16@0+ (10,0) [0|1] "s" Vector__XXX
SG_ MaxStringCurrent m53 : 15|28@0+ (1,0) [0|1] "mA" Vector__XXX
SG_ MaxPackCurrent m53 : 35|28@0+ (1,0) [0|1] "mA" Vector__XXX
SG_ SOC_algorithm m16 : 15|4@0+ (1,0) [0|1] "" Vector__XXX
SG_ SOE_algorithm m16 : 11|4@0+ (1,0) [0|1] "" Vector__XXX
SG_ SOF_algorithm m16 : 23|4@0+ (1,0) [0|1] "" Vector__XXX
SG_ SOH_algorithm m16 : 19|4@0+ (1,0) [0|1] "" Vector__XXX
SG_ Balancing_strategy m16 : 31|4@0+ (1,0) [0|1] "" Vector__XXX
SG_ IMD m16 : 27|4@0+ (1,0) [0|1] "" Vector__XXX
SG_ Rtos m16 : 39|4@0+ (1,0) [0|1] "" Vector__XXX
SG_ AFE m0 : 15|16@0+ (1,0) [0|65535] "" Vector__XXX
SG_ TemperatureSensor m0 : 31|8@0+ (1,0) [0|255] "" Vector__XXX
SG_ TemperatureSensorMethod m0 : 39|8@0+ (1,0) [0|255] "" Vector__XXX

BO_ 772 f_DebugIdentifyHardware: 8 Vector__XXX
SG_ f_DebugIdentifyHardware_Mux M : 7|1@0+ (1,0) [0|0] "" Vector__XXX
SG_ SerialId m1 : 23|48@0+ (1,0) [0|281474976710655] "" Vector__XXX
SG_ AfeNumber m1 : 6|15@0+ (1,0) [0|32767] "" Vector__XXX

BO_ 769 f_DebugResponse: 8 Vector__XXX
SG_ f_DebugResponse_Mux M : 7|8@0+ (1,0) [0|0] "" Vector__XXX
SG_ Number m3 : 15|8@0+ (1,0) [0|1] "" Vector__XXX
SG_ CoordinateX m3 : 27|12@0+ (1,0) [0|1] "" Vector__XXX
SG_ CoordinateY m3 : 23|12@0+ (1,0) [0|1] "" Vector__XXX
SG_ LotNumber m2 : 15|32@0+ (1,0) [0|1] "" Vector__XXX
SG_ UniqueId m1 : 15|32@0+ (1,0) [0|4294967295] "" Vector__XXX
SG_ DirtyFlag m0 : 33|1@0+ (1,0) [0|1] "" Vector__XXX
SG_ MajorVersionNumber m0 : 15|8@0+ (1,0) [0|255] "" Vector__XXX
SG_ MinorVersionNumber m0 : 23|8@0+ (1,0) [0|255] "" Vector__XXX
SG_ PatchVersionNumber m0 : 31|8@0+ (1,0) [0|255] "" Vector__XXX
SG_ ReleaseDistance m0 : 39|5@0+ (1,0) [0|31] "" Vector__XXX
SG_ ReleaseDistanceOverflow m0 : 34|1@0+ (1,0) [0|1] "" Vector__XXX
SG_ UnderVersionControl m0 : 32|1@0+ (1,0) [0|1] "" Vector__XXX
SG_ MagicBootData m15 : 15|56@0+ (1,0) [0|1] "" Vector__XXX
SG_ GetDay m4 : 36|5@0+ (1,0) [0|31] "" Vector__XXX
SG_ GetHours m4 : 28|5@0+ (1,0) [0|31] "" Vector__XXX
SG_ GetHundredthOfSeconds m4 : 15|7@0+ (1,0) [0|127] "" Vector__XXX
SG_ GetMinutes m4 : 18|6@0+ (1,0) [0|63] "" Vector__XXX
SG_ GetMonth m4 : 47|4@0+ (1,0) [0|15] "" Vector__XXX
SG_ GetSeconds m4 : 8|6@0+ (1,0) [0|63] "" Vector__XXX
SG_ GetWeekday m4 : 39|3@0+ (1,0) [0|7] "" Vector__XXX
SG_ GetYear m4 : 43|7@0+ (1,0) [0|127] "" Vector__XXX
SG_ RtcRequestFlag m4 : 52|2@0+ (1,0) [0|2] "" Vector__XXX
SG_ shortHashLow7 m6 : 15|56@0+ (1,0) [0|0] "" Vector__XXX
SG_ shortHashHigh7 m5 : 15|56@0+ (1,0) [0|0] "" Vector__XXX
SG_ GetUptimeThousandthOfSeconds m7 : 15|10@0+ (1,0) [0|1023] "" Vector__XXX
SG_ GetUptimeHundredthOfSeconds m7 : 21|7@0+ (1,0) [0|127] "" Vector__XXX
SG_ GetUptimeTenthOfSeconds m7 : 30|4@0+ (1,0) [0|15] "" Vector__XXX
SG_ GetUptimeSeconds m7 : 26|6@0+ (1,0) [0|63] "" Vector__XXX
SG_ GetUptimeMinutes m7 : 36|6@0+ (1,0) [0|63] "" Vector__XXX
SG_ GetUptimeHours m7 : 46|5@0+ (1,0) [0|31] "" Vector__XXX
SG_ GetUptimeDays m7 : 41|5@0+ (1,0) [0|31] "" Vector__XXX
SG_ GetBootDay m14 : 36|5@0+ (1,0) [0|31] "" Vector__XXX
SG_ GetBootHours m14 : 28|5@0+ (1,0) [0|31] "" Vector__XXX
SG_ GetBootHundredthOfSeconds m14 : 15|7@0+ (1,0) [0|127] "" Vector__XXX
SG_ GetBootMinutes m14 : 18|6@0+ (1,0) [0|63] "" Vector__XXX
SG_ GetBootMonth m14 : 47|4@0+ (1,0) [0|15] "" Vector__XXX
SG_ GetBootSeconds m14 : 8|6@0+ (1,0) [0|63] "" Vector__XXX
SG_ GetbootWeekday m14 : 39|3@0+ (1,0) [0|7] "" Vector__XXX
SG_ GetBootYear m14 : 43|7@0+ (1,0) [0|127] "" Vector__XXX
SG_ MeasurementValue m8 : 39|32@0- (1,0) [-2147483648|2147483647] "" Vector__XXX
SG_ CalibrationChannel8 m8 : 15|8@0+ (1,0) [0|255] "" Vector__XXX
SG_ CalibrationValue9 m9 : 39|32@0- (0.0001,0) [-214748.3648|214748.3647] "" Vector__XXX
SG_ CalibrationChannel9 m9 : 15|8@0+ (1,0) [0|255] "" Vector__XXX
SG_ CalibrationValue10 m10 : 39|32@0- (0.0001,0) [-214748.3648|214748.3647] "" Vector__XXX
SG_ CalibrationChannel10 m10 : 15|8@0+ (1,0) [0|255] "" Vector__XXX

BO_ 770 f_DebugUnsupportedMultiplexerVal: 8 Vector__XXX
SG_ MessageId : 7|32@0+ (1,0) [0|1] "" Vector__XXX
SG_ MultiplexerValue : 39|32@0+ (1,0) [0|1] "" Vector__XXX

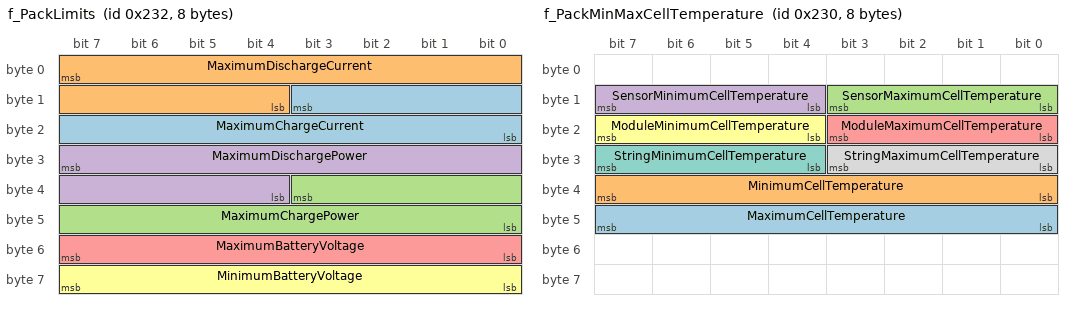
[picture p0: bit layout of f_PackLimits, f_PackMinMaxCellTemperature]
BO_ 562 f_PackLimits: 8 Vector__XXX
SG_ MaximumChargeCurrent : 11|12@0+ (0.25,0) [0|1023.75] "A" Vector__XXX
SG_ MaximumDischargeCurrent : 7|12@0+ (0.25,0) [0|1023.75] "A" Vector__XXX
SG_ MaximumChargePower : 35|12@0+ (0.1,0) [0|409.5] "kW" Vector__XXX
SG_ MaximumDischargePower : 31|12@0+ (0.1,0) [0|409.5] "kW" Vector__XXX
SG_ MaximumBatteryVoltage : 55|8@0+ (4,0) [0|1020] "V" Vector__XXX
SG_ MinimumBatteryVoltage : 63|8@0+ (4,0) [0|1020] "V" Vector__XXX

BO_ 560 f_PackMinMaxCellTemperature: 8 Vector__XXX
SG_ MaximumCellTemperature : 47|8@0- (1,0) [-128|127] "degC" Vector__XXX
SG_ MinimumCellTemperature : 39|8@0- (1,0) [-128|127] "degC" Vector__XXX
SG_ SensorMaximumCellTemperature : 11|4@0+ (1,0) [0|1] "" Vector__XXX
SG_ SensorMinimumCellTemperature : 15|4@0+ (1,0) [0|1] "" Vector__XXX
SG_ ModuleMaximumCellTemperature : 19|4@0+ (1,0) [0|1] "" Vector__XXX
SG_ ModuleMinimumCellTemperature : 23|4@0+ (1,0) [0|1] "" Vector__XXX
SG_ StringMinimumCellTemperature : 31|4@0+ (1,0) [0|1] "" Vector__XXX
SG_ StringMaximumCellTemperature : 27|4@0+ (1,0) [0|1] "" Vector__XXX

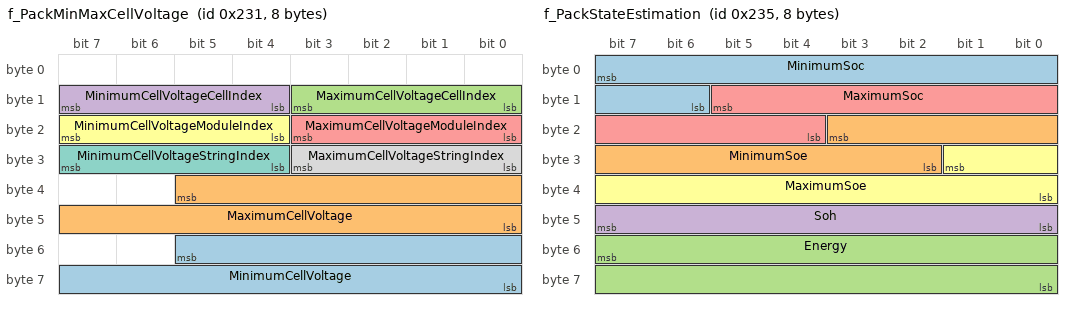
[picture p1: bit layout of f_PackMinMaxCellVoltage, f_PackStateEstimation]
BO_ 561 f_PackMinMaxCellVoltage: 8 Vector__XXX
SG_ MinimumCellVoltage : 53|14@0- (1,0) [-8192|8191] "mV" Vector__XXX
SG_ MaximumCellVoltage : 37|14@0- (1,0) [-8192|8191] "mV" Vector__XXX
SG_ MaximumCellVoltageCellIndex : 11|4@0+ (1,0) [0|1] "" Vector__XXX
SG_ MinimumCellVoltageCellIndex : 15|4@0+ (1,0) [0|1] "" Vector__XXX
SG_ MaximumCellVoltageModuleIndex : 19|4@0+ (1,0) [0|1] "" Vector__XXX
SG_ MinimumCellVoltageModuleIndex : 23|4@0+ (1,0) [0|1] "" Vector__XXX
SG_ MinimumCellVoltageStringIndex : 31|4@0+ (1,0) [0|1] "" Vector__XXX
SG_ MaximumCellVoltageStringIndex : 27|4@0+ (1,0) [0|1] "" Vector__XXX

BO_ 565 f_PackStateEstimation: 8 Vector__XXX
SG_ MinimumSoc : 7|10@0+ (0.1,0) [0|102.3] "%" Vector__XXX
SG_ MinimumSoe : 19|10@0+ (0.1,0) [0|102.3] "%" Vector__XXX
SG_ Energy : 55|16@0+ (0.1,0) [0|6553.5] "kWh" Vector__XXX
SG_ Soh : 47|8@0+ (0.5,0) [0|127.5] "%" Vector__XXX
SG_ MaximumSoc : 13|10@0+ (0.1,0) [0|102.3] "%" Vector__XXX
SG_ MaximumSoe : 25|10@0+ (0.1,0) [0|102.3] "%" Vector__XXX

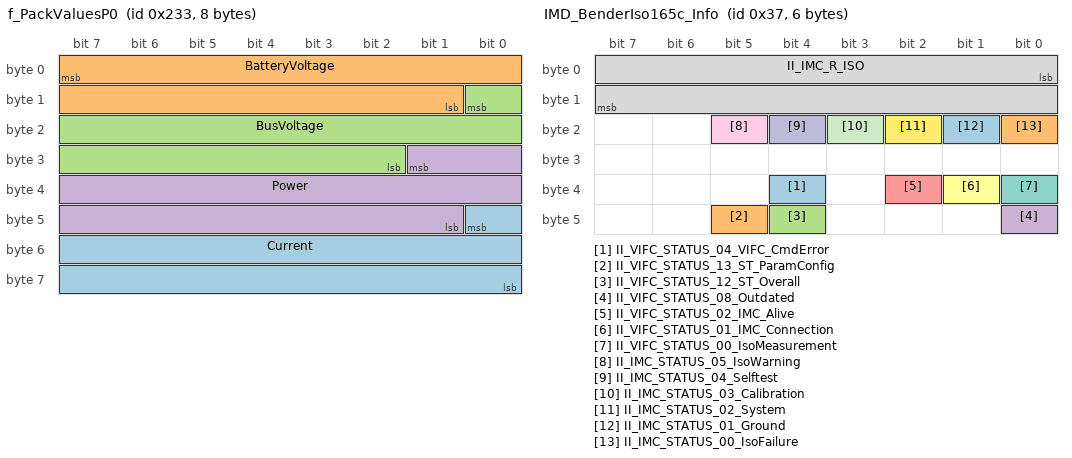
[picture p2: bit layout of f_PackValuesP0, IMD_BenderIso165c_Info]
BO_ 563 f_PackValuesP0: 8 Vector__XXX
SG_ Current : 40|17@0- (0.01,0) [-655.36|655.35] "A" Vector__XXX
SG_ BatteryVoltage : 7|15@0- (0.1,0) [-1638.4|1638.3] "V" Vector__XXX
SG_ BusVoltage : 8|15@0- (0.1,0) [-1638.4|1638.3] "V" Vector__XXX
SG_ Power : 25|17@0- (0.01,0) [-655.36|655.35] "kW" Vector__XXX

BO_ 564 f_PackValuesP1: 8 Vector__XXX
SG_ InsulationResistance : 7|13@0+ (7,0) [0|57337] "kOhm" Vector__XXX

BO_ 577 f_StringMinMaxCellTemperature: 8 Vector__XXX
SG_ f_StringMinMaxCellTemperature_Mux M : 3|4@0+ (1,0) [0|0] "" Vector__XXX
SG_ MaximumCellTemperature m0 : 31|8@0- (0.5,0) [-64|63.5] "degC" Vector__XXX
SG_ MinimumCellTemperature m0 : 39|8@0- (0.5,0) [-64|63.5] "degC" Vector__XXX
SG_ SensorMaximumCellTemperature m0 : 11|4@0+ (1,0) [0|1] "" Vector__XXX
SG_ SensorMinimumCellTemperature m0 : 15|4@0+ (1,0) [0|1] "" Vector__XXX
SG_ ModuleMaximumCellTemperature m0 : 19|4@0+ (1,0) [0|1] "" Vector__XXX
SG_ ModuleMinimumCellTemperature m0 : 23|4@0+ (1,0) [0|1] "" Vector__XXX

BO_ 578 f_StringMinMaxCellVoltage: 8 Vector__XXX
SG_ f_StringMinMaxCellVoltage_Mux M : 3|4@0+ (1,0) [0|0] "" Vector__XXX
SG_ MinimumCellVoltage m0 : 33|14@0- (1,0) [-8192|8191] "mV" Vector__XXX
SG_ MaximumCellVoltage m0 : 31|14@0- (1,0) [-8192|8191] "mV" Vector__XXX
SG_ SensorMaximumCellVoltage m0 : 11|4@0+ (1,0) [0|1] "" Vector__XXX
SG_ SensorMinimumCellVoltage m0 : 15|4@0+ (1,0) [0|1] "" Vector__XXX
SG_ ModuleMaximumCellVoltage m0 : 19|4@0+ (1,0) [0|1] "" Vector__XXX
SG_ ModuleMinimumCellVoltage m0 : 23|4@0+ (1,0) [0|1] "" Vector__XXX

BO_ 576 f_StringState: 8 Vector__XXX
SG_ f_StringState_Mux M : 3|4@0+ (1,0) [0|0] "" Vector__XXX
SG_ IsStringConnected m0 : 4|1@0+ (1,0) [0|1] "" Vector__XXX
SG_ IsBalancingActive m0 : 5|1@0+ (1,0) [0|1] "" Vector__XXX
SG_ OvertemperatureChargeMslError m0 : 8|1@0+ (1,0) [0|1] "" Vector__XXX
SG_ UndertemperatureChargeMslError m0 : 9|1@0+ (1,0) [0|1] "" Vector__XXX
SG_ OvertemperatureDischargeMslError m0 : 10|1@0+ (1,0) [0|1] "" Vector__XXX
SG_ UndertemperatureDischargeMslErro m0 : 11|1@0+ (1,0) [0|1] "" Vector__XXX
SG_ CellOvercurrentChargeMslError m0 : 12|1@0+ (1,0) [0|1] "" Vector__XXX
SG_ CellOvercurrentDischargeMslError m0 : 13|1@0+ (1,0) [0|1] "" Vector__XXX
SG_ OvervoltageMslError m0 : 14|1@0+ (1,0) [0|1] "" Vector__XXX
SG_ UndervoltageMslError m0 : 15|1@0+ (1,0) [0|1] "" Vector__XXX
SG_ DeepDischargeError m0 : 7|1@0+ (1,0) [0|1] "" Vector__XXX
SG_ StringCurrentMeasurementError m0 : 43|1@0+ (1,0) [0|1] "" Vector__XXX
SG_ PositiveContactorError m0 : 32|1@0+ (1,0) [0|1] "" Vector__XXX
SG_ OpenWireError m0 : 49|1@0+ (1,0) [0|1] "" Vector__XXX
SG_ CellVoltagePlausibilityError m0 : 52|1@0+ (1,0) [0|1] "" Vector__XXX
SG_ CellTemperaturePlausibilityError m0 : 51|1@0+ (1,0) [0|1] "" Vector__XXX
SG_ StringVoltagePlausibilityError m0 : 53|1@0+ (1,0) [0|1] "" Vector__XXX
SG_ SlaveHardwareError m0 : 34|1@0+ (1,0) [0|1] "" Vector__XXX
SG_ DaisyChainBaseCommunicationError m0 : 35|1@0+ (1,0) [0|1] "" Vector__XXX
SG_ DaisyChainBaseCrcError m0 : 37|1@0+ (1,0) [0|1] "" Vector__XXX
SG_ DaisyChainBaseVoltMeasOorError m0 : 39|1@0+ (1,0) [0|1] "" Vector__XXX
SG_ DaisyChainBaseTempMeasOorError m0 : 41|1@0+ (1,0) [0|1] "" Vector__XXX
SG_ CoulombCountingMeasurementError m0 : 44|1@0+ (1,0) [0|1] "" Vector__XXX
SG_ EnergyCountingMeasurementError m0 : 45|1@0+ (1,0) [0|1] "" Vector__XXX
SG_ VoltageSpreadPlausibilityError m0 : 55|1@0+ (1,0) [0|1] "" Vector__XXX
SG_ TemperatureSpreadPlausibilityErr m0 : 54|1@0+ (1,0) [0|1] "" Vector__XXX
SG_ IsStringFuseBlown m0 : 6|1@0+ (1,0) [0|1] "" Vector__XXX
SG_ OvervoltageMolWarning m0 : 22|1@0+ (1,0) [0|1] "" Vector__XXX
SG_ UndervoltageMolWarning m0 : 23|1@0+ (1,0) [0|1] "" Vector__XXX
SG_ OvertemperatureChargeMolWarning m0 : 16|1@0+ (1,0) [0|1] "" Vector__XXX
SG_ OvertemperatureDischargeMolWarni m0 : 18|1@0+ (1,0) [0|1] "" Vector__XXX
SG_ UndertemperatureChargeMolWarning m0 : 17|1@0+ (1,0) [0|1] "" Vector__XXX
SG_ UndertemperatureDischargeMolWarn m0 : 19|1@0+ (1,0) [0|1] "" Vector__XXX
SG_ CellOvercurrentChargeMolWarning m0 : 20|1@0+ (1,0) [0|1] "" Vector__XXX
SG_ CellOvercurrentDischargeMolWarni m0 : 21|1@0+ (1,0) [0|1] "" Vector__XXX
SG_ OvertemperatureChargeRslWarning m0 : 24|1@0+ (1,0) [0|1] "" Vector__XXX
SG_ UndertemperatureChargeRslWarning m0 : 25|1@0+ (1,0) [0|1] "" Vector__XXX
SG_ OvertemperatureDischargeRslWarni m0 : 26|1@0+ (1,0) [0|1] "" Vector__XXX
SG_ UndertemperatureDischargeRslWarn m0 : 27|1@0+ (1,0) [0|1] "" Vector__XXX
SG_ CellOvercurrentChargeRslWarning m0 : 28|1@0+ (1,0) [0|1] "" Vector__XXX
SG_ CellOvercurrentDischargeRslWarni m0 : 29|1@0+ (1,0) [0|1] "" Vector__XXX
SG_ OvervoltageRslWarning m0 : 30|1@0+ (1,0) [0|1] "" Vector__XXX
SG_ UndervoltageRslWarning m0 : 31|1@0+ (1,0) [0|1] "" Vector__XXX
SG_ NegativeContactorError m0 : 33|1@0+ (1,0) [0|1] "" Vector__XXX
SG_ StringVoltageMeasurementError m0 : 46|1@0+ (1,0) [0|1] "" Vector__XXX
SG_ FusedStringVoltageMeasurementErr m0 : 47|1@0+ (1,0) [0|1] "" Vector__XXX
SG_ PackVoltageMeasurementError m0 : 48|1@0+ (1,0) [0|1] "" Vector__XXX
SG_ StringOvercurrentError m0 : 63|1@0+ (1,0) [0|1] "" Vector__XXX

BO_ 581 f_StringStateEstimation: 8 Vector__XXX
SG_ f_StringStateEstimation_Mux M : 7|4@0+ (1,0) [0|0] "" Vector__XXX
SG_ MinimumSoc m0 : 3|9@0+ (0.2,0) [0|102.2] "%" Vector__XXX
SG_ MaximumSoc m0 : 10|9@0+ (0.2,0) [0|102.2] "%" Vector__XXX
SG_ MinimumSoe m0 : 17|9@0+ (0.2,0) [0|102.2] "%" Vector__XXX
SG_ Energy m0 : 54|15@0+ (0.01,0) [0|327.67] "kWh" Vector__XXX
SG_ Soh m0 : 47|9@0+ (0.2,0) [0|102.2] "%" Vector__XXX
SG_ MaximumSoe m0 : 24|9@0+ (0.2,0) [0|102.2] "%" Vector__XXX

BO_ 579 f_StringValuesP0: 8 Vector__XXX
SG_ f_StringValuesP0_Mux M : 7|3@0+ (1,0) [0|0] "" Vector__XXX
SG_ Current m0 : 18|18@0- (0.01,0) [-1310.72|1310.71] "A" Vector__XXX
SG_ Voltage m0 : 4|18@0- (0.01,0) [-1310.72|1310.71] "V" Vector__XXX
SG_ Power m0 : 32|18@0- (0.01,0) [-1310.72|1310.71] "kW" Vector__XXX

BO_ 580 f_StringValuesP1: 8 Vector__XXX
SG_ f_StringValuesP1_Mux M : 7|4@0+ (1,0) [0|0] "" Vector__XXX
SG_ EnergyCounter m0 : 15|32@0- (1,0) [-2147483648|2147483647] "Wh" Vector__XXX

BO_ 537 f_SystemState: 8 Vector__XXX
SG_ State : 0|5@0+ (1,0) [0|31] "" Vector__XXX
SG_ Substate : 7|7@0+ (1,0) [0|127] "" Vector__XXX

BO_ 55 IMD_BenderIso165c_Info: 6 Vector__XXX
SG_ II_VIFC_STATUS_04_VIFC_CmdError : 36|1@1+ (1,0) [0|1] "" Vector__XXX
SG_ II_VIFC_STATUS_13_ST_ParamConfig : 45|1@1+ (1,0) [0|1] "" Vector__XXX
SG_ II_VIFC_STATUS_12_ST_Overall : 44|1@1+ (1,0) [0|1] "" Vector__XXX
SG_ II_VIFC_STATUS_08_Outdated : 40|1@1+ (1,0) [0|1] "" Vector__XXX
SG_ II_VIFC_STATUS_02_IMC_Alive : 34|1@1+ (1,0) [0|1] "" Vector__XXX
SG_ II_VIFC_STATUS_01_IMC_Connection : 33|1@1+ (1,0) [0|1] "" Vector__XXX
SG_ II_VIFC_STATUS_00_IsoMeasurement : 32|1@1+ (1,0) [0|1] "" Vector__XXX
SG_ II_IMC_R_ISO : 0|16@1+ (1,0) [0|65535] "kOhm" Vector__XXX
SG_ II_IMC_STATUS_05_IsoWarning : 21|1@1+ (1,0) [0|1] "" Vector__XXX
SG_ II_IMC_STATUS_04_Selftest : 20|1@1+ (1,0) [0|1] "" Vector__XXX
SG_ II_IMC_STATUS_03_Calibration : 19|1@1+ (1,0) [0|1] "" Vector__XXX
SG_ II_IMC_STATUS_02_System : 18|1@1+ (1,0) [0|1] "" Vector__XXX
SG_ II_IMC_STATUS_01_Ground : 17|1@1+ (1,0) [0|1] "" Vector__XXX
SG_ II_IMC_STATUS_00_IsoFailure : 16|1@1+ (1,0) [0|1] "" Vector__XXX

BO_ 34 IMD_BenderIso165c_Request: 5 Vector__XXX
SG_ IMD_BenderIso165c_Request_Mux M : 0|8@1+ (1,0) [0|0] "" Vector__XXX
SG_ MG_IMC_MANUFACT_INDEX m61 : 8|16@1+ (1,0) [0|65535] "" Vector__XXX
SG_ MG_VIFC_POWER_MODE m223 : 8|16@1+ (1,0) [0|65535] "" Vector__XXX
SG_ MC_VIFC_POWER_MODE m201 : 8|16@1+ (1,0) [0|65535] "" Vector__XXX
SG_ MG_VIFC_VERSION_INDEX m222 : 8|16@1+ (1,0) [0|65535] "" Vector__XXX
SG_ MG_IMC_VERSION_INDEX m51 : 8|16@1+ (1,0) [0|65535] "" Vector__XXX
SG_ MG_IMC_EEPROM_INDEX m59 : 8|16@1+ (1,0) [0|65535] "" Vector__XXX
SG_ MC_VIFC_MEASURE_MODE m203 : 8|16@1+ (1,0) [0|65535] "" Vector__XXX
SG_ MS_IMC_MEAN_FACTOR m43 : 8|16@1+ (1,0) [1|20] "" Vector__XXX
SG_ MS_IMC_EEPROM_DATA m42 : 24|16@1+ (1,0) [0|65535] "" Vector__XXX
SG_ MS_IMC_EEPROM_INDEX m42 : 8|16@1+ (1,0) [0|65535] "" Vector__XXX
SG_ MC_VIFC_LOCK_PWD m202 : 24|16@1+ (1,0) [0|65535] "" Vector__XXX
SG_ MC_VIFC_LOCK_MODE m202 : 8|16@1+ (1,0) [0|65535] "" Vector__XXX
SG_ IMD_Request_DataWord2 m0 : 24|16@1+ (1,0) [0|65535] "" Vector__XXX
SG_ IMD_Request_DataWord1 m0 : 8|16@1+ (1,0) [0|65535] "" Vector__XXX
SG_ MS_VIFC_HV_RELAIS_STATE m210 : 24|16@1+ (1,0) [0|65535] "" Vector__XXX
SG_ MS_VIFC_HV_RELAIS m210 : 8|16@1+ (1,0) [0|65535] "" Vector__XXX
SG_ MS_IMC_R_ISO_WRN_THR m41 : 8|16@1+ (1,0) [40|2000] "kOhm" Vector__XXX
SG_ MC_IMC_CALIB_STEP m34 : 8|16@1+ (1,0) [0|65535] "" Vector__XXX
SG_ MC_IMC_SELFTEST_SCR m33 : 8|16@1+ (1,0) [0|65535] "" Vector__XXX
SG_ MS_IMC_R_ISO_ERR_THR m40 : 8|16@1+ (1,0) [30|1000] "kOhm" Vector__XXX

BO_ 35 IMD_BenderIso165c_Response: 5 Vector__XXX
SG_ IMD_BenderIso165c_Response_Mux M : 0|8@1+ (1,0) [0|0] "" Vector__XXX
SG_ IG_VIFC_STATUS_04_VIFC_CmdError m220 : 12|1@1+ (1,0) [0|1] "" Vector__XXX
SG_ IG_VIFC_STATUS_13_ST_ParamConfig m220 : 21|1@1+ (1,0) [0|1] "" Vector__XXX
SG_ IG_VIFC_STATUS_12_ST_Overall m220 : 20|1@1+ (1,0) [0|1] "" Vector__XXX
SG_ IG_VIFC_STATUS_08_Outdated m220 : 16|1@1+ (1,0) [0|1] "" Vector__XXX
SG_ IG_VIFC_STATUS_02_IMC_Alive m220 : 10|1@1+ (1,0) [0|1] "" Vector__XXX
SG_ IG_VIFC_STATUS_01_IMCConnection m220 : 9|1@1+ (1,0) [0|1] "" Vector__XXX
SG_ IG_VIFC_STATUS_00_IsoMeasurement m220 : 8|1@1+ (1,0) [0|1] "" Vector__XXX
SG_ IG_IMC_STATUS_EXT_15_Reserved m55 : 39|1@1+ (1,0) [0|1] "" Vector__XXX
SG_ IG_IMC_STATUS_EXT_06_Reserved m55 : 30|1@1+ (1,0) [0|1] "" Vector__XXX
SG_ IG_IMC_STATUS_EXT_14_IDString m55 : 38|1@1+ (1,0) [0|1] "" Vector__XXX
SG_ IG_IMC_STATUS_EXT_13_HV2 m55 : 37|1@1+ (1,0) [0|1] "" Vector__XXX
SG_ IG_IMC_STATUS_EXT_12_HV1 m55 : 36|1@1+ (1,0) [0|1] "" Vector__XXX
SG_ IG_IMC_STATUS_EXT_11_FuseBits m55 : 35|1@1+ (1,0) [0|1] "" Vector__XXX
SG_ IG_IMC_STATUS_EXT_10_12V_NEG m55 : 34|1@1+ (1,0) [0|1] "" Vector__XXX
SG_ IG_IMC_STATUS_EXT_09_12V_POS m55 : 33|1@1+ (1,0) [0|1] "" Vector__XXX
SG_ IG_IMC_STATUS_EXT_08_TestPulse m55 : 32|1@1+ (1,0) [0|1] "" Vector__XXX
SG_ IG_IMC_STATUS_EXT_07_Parameter m55 : 31|1@1+ (1,0) [0|1] "" Vector__XXX
SG_ IG_IMC_STATUS_EXT_05_Stack m55 : 29|1@1+ (1,0) [0|1] "" Vector__XXX
SG_ IG_IMC_STATUS_EXT_04_RAM m55 : 28|1@1+ (1,0) [0|1] "" Vector__XXX
SG_ IG_IMC_STATUS_EXT_03_Flash m55 : 27|1@1+ (1,0) [0|1] "" Vector__XXX
SG_ IG_IMC_STATUS_EXT_02_EEPROM m55 : 26|1@1+ (1,0) [0|1] "" Vector__XXX
SG_ IG_IMC_STATUS_EXT_01_Hardware m55 : 25|1@1+ (1,0) [0|1] "" Vector__XXX
SG_ IG_IMC_STATUS_EXT_00_Calibration m55 : 24|1@1+ (1,0) [0|1] "" Vector__XXX
SG_ IG_IMC_STATUS_05_IsoWarning m55 : 13|1@1+ (1,0) [0|1] "" Vector__XXX
SG_ IG_IMC_STATUS_04_Selftest m55 : 12|1@1+ (1,0) [0|1] "" Vector__XXX
SG_ IG_IMC_STATUS_03_Calibration m55 : 11|1@1+ (1,0) [0|1] "" Vector__XXX
SG_ IG_IMC_STATUS_02_System m55 : 10|1@1+ (1,0) [0|1] "" Vector__XXX
SG_ IG_IMC_STATUS_01_Ground m55 : 9|1@1+ (1,0) [0|1] "" Vector__XXX
SG_ IG_IMC_STATUS_00_IsoFailure m55 : 8|1@1+ (1,0) [0|1] "" Vector__XXX
SG_ IG_VIFC_VERSION_MIN m222 : 24|8@1+ (1,0) [0|255] "" Vector__XXX
SG_ IG_VIFC_VERSION_INDEX m222 : 8|16@1+ (1,0) [0|65535] "" Vector__XXX
SG_ IG_VIFC_VERSION_MAJ m222 : 32|8@1+ (1,0) [0|255] "" Vector__XXX
SG_ IG_IMC_VERSION_MIN m51 : 24|8@1+ (1,0) [0|255] "" Vector__XXX
SG_ IG_IMC_VERSION_INDEX m51 : 8|16@1+ (1,0) [0|65535] "" Vector__XXX
SG_ IG_IMC_VERSION_MAJ m51 : 32|8@1+ (1,0) [0|255] "" Vector__XXX
SG_ IG_IMC_MANUFACT_INDEX m61 : 8|16@1+ (1,0) [0|65535] "" Vector__XXX
SG_ IG_IMC_MANUFACT_DATA m61 : 24|16@1+ (1,0) [0|65535] "" Vector__XXX
SG_ IG_IMC_R_ISO_CNT m53 : 32|8@1+ (1,0) [0|255] "Count" Vector__XXX
SG_ IG_IMC_R_ISO_BIAS m53 : 24|8@1+ (1,0) [0|255] "" Vector__XXX
SG_ IG_IMC_R_ISO m53 : 8|16@1+ (1,0) [0|65535] "kOhm" Vector__XXX
SG_ IG_VIFC_TEMP m225 : 8|16@1+ (1,0) [0|65535] "degC" Vector__XXX
SG_ IG_VIFC_IMC_ALIVE m226 : 8|16@1+ (1,0) [0|65535] "" Vector__XXX
SG_ IG_VIFC_POWER_MODE m223 : 8|16@1+ (1,0) [0|65535] "" Vector__XXX
SG_ IC_VIFC_POWER_MODE m201 : 8|16@1+ (1,0) [0|65535] "" Vector__XXX
SG_ IS_IMC_MEAN_FACTOR m43 : 8|16@1+ (1,0) [0|65535] "" Vector__XXX
SG_ IS_IMC_EEPROM_INDEX m42 : 8|16@1+ (1,0) [0|65535] "" Vector__XXX
SG_ IS_IMC_EEPROM_DATA m42 : 24|16@1+ (1,0) [0|65535] "" Vector__XXX
SG_ IC_IMC_CALIB_STEP m34 : 8|16@1+ (1,0) [0|65535] "" Vector__XXX
SG_ IS_IMC_R_ISO_WRN_THR m41 : 8|16@1+ (1,0) [0|65535] "kOhm" Vector__XXX
SG_ IS_IMC_R_ISO_ERR_THR m40 : 8|16@1+ (1,0) [0|65535] "kOhm" Vector__XXX
SG_ IC_VIFC_LOCK_MODE m202 : 8|16@1+ (1,0) [0|65535] "" Vector__XXX
SG_ IC_VIFC_MEASURE_MODE m203 : 8|16@1+ (1,0) [0|65535] "" Vector__XXX
SG_ IS_VIFC_HV_RELAIS_STATE m210 : 24|16@1+ (1,0) [0|65535] "" Vector__XXX
SG_ IS_VIFC_HV_RELAIS m210 : 8|16@1+ (1,0) [0|65535] "" Vector__XXX
SG_ IG_IMC_EEPROM_DATA m59 : 24|16@1+ (1,0) [0|65535] "" Vector__XXX
SG_ IG_IMC_EEPROM_INDEX m59 : 8|16@1+ (1,0) [0|65535] "" Vector__XXX
SG_ IG_IMC_MEAN_FACTOR m60 : 8|16@1+ (1,0) [0|65535] "" Vector__XXX
SG_ IG_VIFC_LOCK_MODE m224 : 8|16@1+ (1,0) [0|65535] "" Vector__XXX
SG_ IG_VIFC_HV_RELAIS_STATE m221 : 24|16@1+ (1,0) [0|65535] "" Vector__XXX
SG_ IG_VIFC_HV_RELAIS m221 : 8|16@1+ (1,0) [0|65535] "" Vector__XXX
SG_ IG_IMD_ERROR_CODE m255 : 8|16@1+ (1,0) [0|65535] "" Vector__XXX
SG_ IG_IMD_FAILED_CMD m255 : 24|8@1+ (1,0) [0|255] "" Vector__XXX
SG_ IG_IMC_HV_2 m58 : 8|16@1+ (1,0) [0|65535] "Volt" Vector__XXX
SG_ IG_IMC_HV_1 m54 : 8|16@1+ (1,0) [0|65535] "Volt" Vector__XXX
SG_ IG_IMC_R_ISO_WRN_THR m57 : 8|16@1+ (1,0) [0|65535] "kOhm" Vector__XXX
SG_ IG_IMC_R_ISO_ERR_THR m50 : 8|16@1+ (1,0) [0|65535] "kOhm" Vector__XXX
SG_ IC_IMC_SELFTEST_SCR m33 : 8|16@1+ (1,0) [0|65535] "" Vector__XXX
SG_ IG_IMC_TEST_CNT m90 : 8|16@1+ (1,0) [0|65535] "Calls" Vector__XXX
SG_ IMD_Response_DataWord2 m0 : 24|16@1+ (1,0) [0|65535] "" Vector__XXX
SG_ IMD_Response_DataWord1 m0 : 8|16@1+ (1,0) [0|65535] "" Vector__XXX

CM_ SG_ 2147483904 IVT_HVBattery_Status "Status of measured battery voltage";
CM_ SG_ 2147483904 IVT_HVBattery "Measured battery voltage";
CM_ SG_ 2147483904 IVT_Current_Status "Status of current measurement";
CM_ SG_ 2147483904 IVT_Current "Measured current value";
CM_ SG_ 2147483911 IVT_ShuntTemp_Status "Status of shunt temperature measurement";
CM_ SG_ 2147483911 IVT_ShuntTemp "Measured temperature of the shunt";
CM_ BO_ 608 "Cell temperature measurement data (in:can_cbs_tx_f_cell-temperatures.c:CANTX_CellTemperatures, fv:tx, type:Cell Information)";
CM_ SG_ 608 CellTemperature_000 "Temperature of cell 0";
CM_ SG_ 608 CellTemperature_001 "Temperature of cell 1";
CM_ SG_ 608 CellTemperature_002 "Temperature of cell 2";
CM_ SG_ 608 CellTemperature_003 "Temperature of cell 3";
CM_ SG_ 608 CellTemperature_004 "Temperature of cell 4";
CM_ SG_ 608 CellTemperature_005 "Temperature of cell 5";
CM_ SG_ 608 CellTemperature_006 "Temperature of cell 6";
CM_ SG_ 608 CellTemperature_007 "Temperature of cell 7";
CM_ SG_ 608 CellTemperature_008 "Temperature of cell 8";
CM_ SG_ 608 CellTemperature_009 "Temperature of cell 9";
CM_ SG_ 608 CellTemperature_010 "Temperature of cell 10";
CM_ SG_ 608 CellTemperature_011 "Temperature of cell 11";
CM_ SG_ 608 CellTemperature_012 "Temperature of cell 12";
CM_ SG_ 608 CellTemperature_013 "Temperature of cell 13";
CM_ SG_ 608 CellTemperature_014 "Temperature of cell 14";
CM_ SG_ 608 CellTemperature_015 "Temperature of cell 15";
CM_ SG_ 608 CellTemperature_016 "Temperature of cell 16";
CM_ SG_ 608 CellTemperature_017 "Temperature of cell 17";
CM_ SG_ 608 CellTemperature_018 "Temperature of cell 18";
CM_ SG_ 608 CellTemperature_019 "Temperature of cell 19";
CM_ SG_ 608 CellTemperature_020 "Temperature of cell 20";
CM_ SG_ 608 CellTemperature_021 "Temperature of cell 21";
CM_ SG_ 608 CellTemperature_022 "Temperature of cell 22";
CM_ SG_ 608 CellTemperature_023 "Temperature of cell 23";
CM_ SG_ 608 CellTemperature_024 "Temperature of cell 24";
CM_ SG_ 608 CellTemperature_025 "Temperature of cell 25";
CM_ SG_ 608 CellTemperature_026 "Temperature of cell 26";
CM_ SG_ 608 CellTemperature_027 "Temperature of cell 27";
CM_ SG_ 608 CellTemperature_028 "Temperature of cell 28";
CM_ SG_ 608 CellTemperature_029 "Temperature of cell 29";
CM_ SG_ 608 CellTemperature_030 "Temperature of cell 30";
CM_ SG_ 608 CellTemperature_031 "Temperature of cell 31";
CM_ SG_ 608 CellTemperature_032 "Temperature of cell 32";
CM_ SG_ 608 CellTemperature_033 "Temperature of cell 33";
CM_ SG_ 608 CellTemperature_034 "Temperature of cell 34";
CM_ SG_ 608 CellTemperature_035 "Temperature of cell 35";
CM_ SG_ 608 CellTemperature_036 "Temperature of cell 36";
CM_ SG_ 608 CellTemperature_037 "Temperature of cell 37";
CM_ SG_ 608 CellTemperature_038 "Temperature of cell 38";
CM_ SG_ 608 CellTemperature_039 "Temperature of cell 39";
CM_ SG_ 608 CellTemperature_040 "Temperature of cell 40";
CM_ SG_ 608 CellTemperature_041 "Temperature of cell 41";
CM_ SG_ 608 CellTemperature_042 "Temperature of cell 42";
CM_ SG_ 608 CellTemperature_043 "Temperature of cell 43";
CM_ SG_ 608 CellTemperature_044 "Temperature of cell 44";
CM_ SG_ 608 CellTemperature_045 "Temperature of cell 45";
CM_ SG_ 608 CellTemperature_046 "Temperature of cell 46";
CM_ SG_ 608 CellTemperature_047 "Temperature of cell 47";
CM_ SG_ 608 CellTemperature_048 "Temperature of cell 48";
CM_ SG_ 608 CellTemperature_049 "Temperature of cell 49";
CM_ SG_ 608 CellTemperature_050 "Temperature of cell 50";
CM_ SG_ 608 CellTemperature_051 "Temperature of cell 51";
CM_ SG_ 608 CellTemperature_052 "Temperature of cell 52";
CM_ SG_ 608 CellTemperature_053 "Temperature of cell 53";
CM_ SG_ 608 CellTemperature_054 "Temperature of cell 54";
CM_ SG_ 608 CellTemperature_055 "Temperature of cell 55";
CM_ SG_ 608 CellTemperature_056 "Temperature of cell 56";
CM_ SG_ 608 CellTemperature_057 "Temperature of cell 57";
CM_ SG_ 608 CellTemperature_058 "Temperature of cell 58";
CM_ SG_ 608 CellTemperature_059 "Temperature of cell 59";
CM_ SG_ 608 CellTemperature_060 "Temperature of cell 60";
CM_ SG_ 608 CellTemperature_061 "Temperature of cell 61";
CM_ SG_ 608 CellTemperature_062 "Temperature of cell 62";
CM_ SG_ 608 CellTemperature_063 "Temperature of cell 63";
CM_ SG_ 608 CellTemperature_064 "Temperature of cell 64";
CM_ SG_ 608 CellTemperature_065 "Temperature of cell 65";
CM_ SG_ 608 CellTemperature_066 "Temperature of cell 66";
CM_ SG_ 608 CellTemperature_067 "Temperature of cell 67";
CM_ SG_ 608 CellTemperature_068 "Temperature of cell 68";
CM_ SG_ 608 CellTemperature_069 "Temperature of cell 69";
CM_ SG_ 608 CellTemperature_070 "Temperature of cell 70";
CM_ SG_ 608 CellTemperature_071 "Temperature of cell 71";
CM_ SG_ 608 CellTemperature_072 "Temperature of cell 72";
CM_ SG_ 608 CellTemperature_073 "Temperature of cell 73";
CM_ SG_ 608 CellTemperature_074 "Temperature of cell 74";
CM_ SG_ 608 CellTemperature_075 "Temperature of cell 75";
CM_ SG_ 608 CellTemperature_076 "Temperature of cell 76";
CM_ SG_ 608 CellTemperature_077 "Temperature of cell 77";
CM_ SG_ 608 CellTemperature_078 "Temperature of cell 78";
CM_ SG_ 608 CellTemperature_079 "Temperature of cell 79";
CM_ SG_ 608 CellTemperature_080 "Temperature of cell 80";
CM_ SG_ 608 CellTemperature_081 "Temperature of cell 81";
CM_ SG_ 608 CellTemperature_082 "Temperature of cell 82";
CM_ SG_ 608 CellTemperature_083 "Temperature of cell 83";
CM_ SG_ 608 CellTemperature_084 "Temperature of cell 84";
CM_ SG_ 608 CellTemperature_085 "Temperature of cell 85";
CM_ SG_ 608 CellTemperature_086 "Temperature of cell 86";
CM_ SG_ 608 CellTemperature_087 "Temperature of cell 87";
CM_ SG_ 608 CellTemperature_088 "Temperature of cell 88";
CM_ SG_ 608 CellTemperature_089 "Temperature of cell 89";
CM_ SG_ 608 CellTemperature_090 "Temperature of cell 90";
CM_ SG_ 608 CellTemperature_091 "Temperature of cell 91";
CM_ SG_ 608 CellTemperature_092 "Temperature of cell 92";
CM_ SG_ 608 CellTemperature_093 "Temperature of cell 93";
CM_ SG_ 608 CellTemperature_094 "Temperature of cell 94";
CM_ SG_ 608 CellTemperature_095 "Temperature of cell 95";
CM_ SG_ 608 CellTemperature_096 "Temperature of cell 96";
CM_ SG_ 608 CellTemperature_097 "Temperature of cell 97";
CM_ SG_ 608 CellTemperature_098 "Temperature of cell 98";
CM_ SG_ 608 CellTemperature_099 "Temperature of cell 99";
CM_ SG_ 608 CellTemperature_100 "Temperature of cell 100";
CM_ SG_ 608 CellTemperature_101 "Temperature of cell 101";
CM_ SG_ 608 CellTemperature_102 "Temperature of cell 102";
CM_ SG_ 608 CellTemperature_103 "Temperature of cell 103";
CM_ SG_ 608 CellTemperature_104 "Temperature of cell 104";
CM_ SG_ 608 CellTemperature_105 "Temperature of cell 105";
CM_ SG_ 608 CellTemperature_106 "Temperature of cell 106";
CM_ SG_ 608 CellTemperature_107 "Temperature of cell 107";
CM_ SG_ 608 CellTemperature_108 "Temperature of cell 108";
CM_ SG_ 608 CellTemperature_109 "Temperature of cell 109";
CM_ SG_ 608 CellTemperature_110 "Temperature of cell 110";
CM_ SG_ 608 CellTemperature_111 "Temperature of cell 111";
CM_ SG_ 608 CellTemperature_112 "Temperature of cell 112";
CM_ SG_ 608 CellTemperature_113 "Temperature of cell 113";
CM_ SG_ 608 CellTemperature_114 "Temperature of cell 114";
CM_ SG_ 608 CellTemperature_115 "Temperature of cell 115";
CM_ SG_ 608 CellTemperature_116 "Temperature of cell 116";
CM_ SG_ 608 CellTemperature_117 "Temperature of cell 117";
CM_ SG_ 608 CellTemperature_118 "Temperature of cell 118";
CM_ SG_ 608 CellTemperature_119 "Temperature of cell 119";
CM_ SG_ 608 CellTemperature_120 "Temperature of cell 120";
CM_ SG_ 608 CellTemperature_121 "Temperature of cell 121";
CM_ SG_ 608 CellTemperature_122 "Temperature of cell 122";
CM_ SG_ 608 CellTemperature_123 "Temperature of cell 123";
CM_ SG_ 608 CellTemperature_124 "Temperature of cell 124";
CM_ SG_ 608 CellTemperature_125 "Temperature of cell 125";
CM_ SG_ 608 CellTemperature_126 "Temperature of cell 126";
CM_ SG_ 608 CellTemperature_127 "Temperature of cell 127";
CM_ SG_ 608 CellTemperature_128 "Temperature of cell 128";
CM_ SG_ 608 CellTemperature_129 "Temperature of cell 129";
CM_ SG_ 608 CellTemperature_130 "Temperature of cell 130";
CM_ SG_ 608 CellTemperature_131 "Temperature of cell 131";
CM_ SG_ 608 CellTemperature_132 "Temperature of cell 132";
CM_ SG_ 608 CellTemperature_133 "Temperature of cell 133";
CM_ SG_ 608 CellTemperature_134 "Temperature of cell 134";
CM_ SG_ 608 CellTemperature_135 "Temperature of cell 135";
CM_ SG_ 608 CellTemperature_136 "Temperature of cell 136";
CM_ SG_ 608 CellTemperature_137 "Temperature of cell 137";
CM_ SG_ 608 CellTemperature_138 "Temperature of cell 138";
CM_ SG_ 608 CellTemperature_139 "Temperature of cell 139";
CM_ SG_ 608 CellTemperature_140 "Temperature of cell 140";
CM_ SG_ 608 CellTemperature_141 "Temperature of cell 141";
CM_ SG_ 608 CellTemperature_142 "Temperature of cell 142";
CM_ SG_ 608 CellTemperature_143 "Temperature of cell 143";
CM_ SG_ 608 CellTemperature_144 "Temperature of cell 144";
CM_ SG_ 608 CellTemperature_145 "Temperature of cell 145";
CM_ SG_ 608 CellTemperature_146 "Temperature of cell 146";
CM_ SG_ 608 CellTemperature_147 "Temperature of cell 147";
CM_ SG_ 608 CellTemperature_148 "Temperature of cell 148";
CM_ SG_ 608 CellTemperature_149 "Temperature of cell 149";
CM_ SG_ 608 CellTemperature_150 "Temperature of cell 150";
CM_ SG_ 608 CellTemperature_151 "Temperature of cell 151";
CM_ SG_ 608 CellTemperature_152 "Temperature of cell 152";
CM_ SG_ 608 CellTemperature_153 "Temperature of cell 153";
CM_ SG_ 608 CellTemperature_154 "Temperature of cell 154";
CM_ SG_ 608 CellTemperature_155 "Temperature of cell 155";
CM_ SG_ 608 CellTemperature_156 "Temperature of cell 156";
CM_ SG_ 608 CellTemperature_157 "Temperature of cell 157";
CM_ SG_ 608 CellTemperature_158 "Temperature of cell 158";
CM_ SG_ 608 CellTemperature_159 "Temperature of cell 159";
CM_ SG_ 608 CellTemperature_160 "Temperature of cell 160";
CM_ SG_ 608 CellTemperature_161 "Temperature of cell 161";
CM_ SG_ 608 CellTemperature_162 "Temperature of cell 162";
CM_ SG_ 608 CellTemperature_163 "Temperature of cell 163";
CM_ SG_ 608 CellTemperature_164 "Temperature of cell 164";
CM_ SG_ 608 CellTemperature_165 "Temperature of cell 165";
CM_ SG_ 608 CellTemperature_166 "Temperature of cell 166";
CM_ SG_ 608 CellTemperature_167 "Temperature of cell 167";
CM_ SG_ 608 CellTemperature_168 "Temperature of cell 168";
CM_ SG_ 608 CellTemperature_169 "Temperature of cell 169";
CM_ SG_ 608 CellTemperature_170 "Temperature of cell 170";
CM_ SG_ 608 CellTemperature_171 "Temperature of cell 171";
CM_ SG_ 608 CellTemperature_172 "Temperature of cell 172";
CM_ SG_ 608 CellTemperature_173 "Temperature of cell 173";
CM_ SG_ 608 CellTemperature_174 "Temperature of cell 174";
CM_ SG_ 608 CellTemperature_175 "Temperature of cell 175";
CM_ SG_ 608 CellTemperature_176 "Temperature of cell 176";
CM_ SG_ 608 CellTemperature_177 "Temperature of cell 177";
CM_ SG_ 608 CellTemperature_178 "Temperature of cell 178";
CM_ SG_ 608 CellTemperature_179 "Temperature of cell 179";
CM_ BO_ 592 "Cell voltage measurement data (in:can_cbs_tx_f_cell-voltages.c:CANTX_CellVoltages, fv:tx, type:Cell Information)";
CM_ SG_ 592 CellVoltage_000 "Voltage of cell 0";
CM_ SG_ 592 CellVoltage_001 "Voltage of cell 1";
CM_ SG_ 592 CellVoltage_002 "Voltage of cell 2";
CM_ SG_ 592 CellVoltage_003 "Voltage of cell 3";
CM_ SG_ 592 CellVoltage_004 "Voltage of cell 4";
CM_ SG_ 592 CellVoltage_005 "Voltage of cell 5";
CM_ SG_ 592 CellVoltage_006 "Voltage of cell 6";
CM_ SG_ 592 CellVoltage_007 "Voltage of cell 7";
CM_ SG_ 592 CellVoltage_008 "Voltage of cell 8";
CM_ SG_ 592 CellVoltage_009 "Voltage of cell 9";
CM_ SG_ 592 CellVoltage_010 "Voltage of cell 10";
CM_ SG_ 592 CellVoltage_011 "Voltage of cell 11";
CM_ SG_ 592 CellVoltage_012 "Voltage of cell 12";
CM_ SG_ 592 CellVoltage_013 "Voltage of cell 13";
CM_ SG_ 592 CellVoltage_014 "Voltage of cell 14";
CM_ SG_ 592 CellVoltage_015 "Voltage of cell 15";
CM_ SG_ 592 CellVoltage_016 "Voltage of cell 16";
CM_ SG_ 592 CellVoltage_017 "Voltage of cell 17";
CM_ SG_ 592 CellVoltage_018 "Voltage of cell 18";
CM_ SG_ 592 CellVoltage_019 "Voltage of cell 19";
CM_ SG_ 592 CellVoltage_020 "Voltage of cell 20";
CM_ SG_ 592 CellVoltage_021 "Voltage of cell 21";
CM_ SG_ 592 CellVoltage_022 "Voltage of cell 22";
CM_ SG_ 592 CellVoltage_023 "Voltage of cell 23";
CM_ SG_ 592 CellVoltage_024 "Voltage of cell 24";
CM_ SG_ 592 CellVoltage_025 "Voltage of cell 25";
CM_ SG_ 592 CellVoltage_026 "Voltage of cell 26";
CM_ SG_ 592 CellVoltage_027 "Voltage of cell 27";
CM_ SG_ 592 CellVoltage_028 "Voltage of cell 28";
CM_ SG_ 592 CellVoltage_029 "Voltage of cell 29";
CM_ SG_ 592 CellVoltage_030 "Voltage of cell 30";
CM_ SG_ 592 CellVoltage_031 "Voltage of cell 31";
CM_ SG_ 592 CellVoltage_032 "Voltage of cell 32";
CM_ SG_ 592 CellVoltage_033 "Voltage of cell 33";
CM_ SG_ 592 CellVoltage_034 "Voltage of cell 34";
CM_ SG_ 592 CellVoltage_035 "Voltage of cell 35";
CM_ SG_ 592 CellVoltage_036 "Voltage of cell 36";
CM_ SG_ 592 CellVoltage_037 "Voltage of cell 37";
CM_ SG_ 592 CellVoltage_038 "Voltage of cell 38";
CM_ SG_ 592 CellVoltage_039 "Voltage of cell 39";
CM_ SG_ 592 CellVoltage_040 "Voltage of cell 40";
CM_ SG_ 592 CellVoltage_041 "Voltage of cell 41";
CM_ SG_ 592 CellVoltage_042 "Voltage of cell 42";
CM_ SG_ 592 CellVoltage_043 "Voltage of cell 43";
CM_ SG_ 592 CellVoltage_044 "Voltage of cell 44";
CM_ SG_ 592 CellVoltage_045 "Voltage of cell 45";
CM_ SG_ 592 CellVoltage_046 "Voltage of cell 46";
CM_ SG_ 592 CellVoltage_047 "Voltage of cell 47";
CM_ SG_ 592 CellVoltage_048 "Voltage of cell 48";
CM_ SG_ 592 CellVoltage_049 "Voltage of cell 49";
CM_ SG_ 592 CellVoltage_050 "Voltage of cell 50";
CM_ SG_ 592 CellVoltage_051 "Voltage of cell 51";
CM_ SG_ 592 CellVoltage_052 "Voltage of cell 52";
CM_ SG_ 592 CellVoltage_053 "Voltage of cell 53";
CM_ SG_ 592 CellVoltage_054 "Voltage of cell 54";
CM_ SG_ 592 CellVoltage_055 "Voltage of cell 55";
CM_ SG_ 592 CellVoltage_056 "Voltage of cell 56";
CM_ SG_ 592 CellVoltage_057 "Voltage of cell 57";
CM_ SG_ 592 CellVoltage_058 "Voltage of cell 58";
CM_ SG_ 592 CellVoltage_059 "Voltage of cell 59";
CM_ SG_ 592 CellVoltage_060 "Voltage of cell 60";
CM_ SG_ 592 CellVoltage_061 "Voltage of cell 61";
CM_ SG_ 592 CellVoltage_062 "Voltage of cell 62";
CM_ SG_ 592 CellVoltage_063 "Voltage of cell 63";
CM_ SG_ 592 CellVoltage_064 "Voltage of cell 64";
CM_ SG_ 592 CellVoltage_065 "Voltage of cell 65";
CM_ SG_ 592 CellVoltage_066 "Voltage of cell 66";
CM_ SG_ 592 CellVoltage_067 "Voltage of cell 67";
CM_ SG_ 592 CellVoltage_068 "Voltage of cell 68";
CM_ SG_ 592 CellVoltage_069 "Voltage of cell 69";
CM_ SG_ 592 CellVoltage_070 "Voltage of cell 70";
CM_ SG_ 592 CellVoltage_071 "Voltage of cell 71";
CM_ SG_ 592 CellVoltage_072 "Voltage of cell 72";
CM_ SG_ 592 CellVoltage_073 "Voltage of cell 73";
CM_ SG_ 592 CellVoltage_074 "Voltage of cell 74";
CM_ SG_ 592 CellVoltage_075 "Voltage of cell 75";
CM_ SG_ 592 CellVoltage_076 "Voltage of cell 76";
CM_ SG_ 592 CellVoltage_077 "Voltage of cell 77";
CM_ SG_ 592 CellVoltage_078 "Voltage of cell 78";
CM_ SG_ 592 CellVoltage_079 "Voltage of cell 79";
CM_ SG_ 592 CellVoltage_080 "Voltage of cell 80";
CM_ SG_ 592 CellVoltage_081 "Voltage of cell 81";
CM_ SG_ 592 CellVoltage_082 "Voltage of cell 82";
CM_ SG_ 592 CellVoltage_083 "Voltage of cell 83";
CM_ SG_ 592 CellVoltage_084 "Voltage of cell 84";
CM_ SG_ 592 CellVoltage_085 "Voltage of cell 85";
CM_ SG_ 592 CellVoltage_086 "Voltage of cell 86";
CM_ SG_ 592 CellVoltage_087 "Voltage of cell 87";
CM_ SG_ 592 CellVoltage_088 "Voltage of cell 88";
CM_ SG_ 592 CellVoltage_089 "Voltage of cell 89";
CM_ SG_ 592 CellVoltage_090 "Voltage of cell 90";
CM_ SG_ 592 CellVoltage_091 "Voltage of cell 91";
CM_ SG_ 592 CellVoltage_092 "Voltage of cell 92";
CM_ SG_ 592 CellVoltage_093 "Voltage of cell 93";
CM_ SG_ 592 CellVoltage_094 "Voltage of cell 94";
CM_ SG_ 592 CellVoltage_095 "Voltage of cell 95";
CM_ SG_ 592 CellVoltage_096 "Voltage of cell 96";
CM_ SG_ 592 CellVoltage_097 "Voltage of cell 97";
CM_ SG_ 592 CellVoltage_098 "Voltage of cell 98";
CM_ SG_ 592 CellVoltage_099 "Voltage of cell 99";
CM_ SG_ 592 CellVoltage_100 "Voltage of cell 100";
CM_ SG_ 592 CellVoltage_101 "Voltage of cell 101";
CM_ SG_ 592 CellVoltage_102 "Voltage of cell 102";
CM_ SG_ 592 CellVoltage_103 "Voltage of cell 103";
CM_ SG_ 592 CellVoltage_104 "Voltage of cell 104";
CM_ SG_ 592 CellVoltage_105 "Voltage of cell 105";
CM_ SG_ 592 CellVoltage_106 "Voltage of cell 106";
CM_ SG_ 592 CellVoltage_107 "Voltage of cell 107";
CM_ SG_ 592 CellVoltage_108 "Voltage of cell 108";
CM_ SG_ 592 CellVoltage_109 "Voltage of cell 109";
CM_ SG_ 592 CellVoltage_110 "Voltage of cell 110";
CM_ SG_ 592 CellVoltage_111 "Voltage of cell 111";
CM_ SG_ 592 CellVoltage_112 "Voltage of cell 112";
CM_ SG_ 592 CellVoltage_113 "Voltage of cell 113";
CM_ SG_ 592 CellVoltage_114 "Voltage of cell 114";
CM_ SG_ 592 CellVoltage_115 "Voltage of cell 115";
CM_ SG_ 592 CellVoltage_116 "Voltage of cell 116";
CM_ SG_ 592 CellVoltage_117 "Voltage of cell 117";
CM_ SG_ 592 CellVoltage_118 "Voltage of cell 118";
CM_ SG_ 592 CellVoltage_119 "Voltage of cell 119";
CM_ SG_ 592 CellVoltage_120 "Voltage of cell 120";
CM_ SG_ 592 CellVoltage_121 "Voltage of cell 121";
CM_ SG_ 592 CellVoltage_122 "Voltage of cell 122";
CM_ SG_ 592 CellVoltage_123 "Voltage of cell 123";
CM_ SG_ 592 CellVoltage_124 "Voltage of cell 124";
CM_ SG_ 592 CellVoltage_125 "Voltage of cell 125";
CM_ SG_ 592 CellVoltage_126 "Voltage of cell 126";
CM_ SG_ 592 CellVoltage_127 "Voltage of cell 127";
CM_ SG_ 592 CellVoltage_128 "Voltage of cell 128";
CM_ SG_ 592 CellVoltage_129 "Voltage of cell 129";
CM_ SG_ 592 CellVoltage_130 "Voltage of cell 130";
CM_ SG_ 592 CellVoltage_131 "Voltage of cell 131";
CM_ SG_ 592 CellVoltage_132 "Voltage of cell 132";
CM_ SG_ 592 CellVoltage_133 "Voltage of cell 133";
CM_ SG_ 592 CellVoltage_134 "Voltage of cell 134";
CM_ SG_ 592 CellVoltage_135 "Voltage of cell 135";
CM_ SG_ 592 CellVoltage_136 "Voltage of cell 136";
CM_ SG_ 592 CellVoltage_137 "Voltage of cell 137";
CM_ SG_ 592 CellVoltage_138 "Voltage of cell 138";
CM_ SG_ 592 CellVoltage_139 "Voltage of cell 139";
CM_ SG_ 592 CellVoltage_140 "Voltage of cell 140";
CM_ SG_ 592 CellVoltage_141 "Voltage of cell 141";
CM_ SG_ 592 CellVoltage_142 "Voltage of cell 142";
CM_ SG_ 592 CellVoltage_143 "Voltage of cell 143";
CM_ SG_ 592 CellVoltage_144 "Voltage of cell 144";
CM_ SG_ 592 CellVoltage_145 "Voltage of cell 145";
CM_ SG_ 592 CellVoltage_146 "Voltage of cell 146";
CM_ SG_ 592 CellVoltage_147 "Voltage of cell 147";
CM_ SG_ 592 CellVoltage_148 "Voltage of cell 148";
CM_ SG_ 592 CellVoltage_149 "Voltage of cell 149";
CM_ SG_ 592 CellVoltage_150 "Voltage of cell 150";
CM_ SG_ 592 CellVoltage_151 "Voltage of cell 151";
CM_ SG_ 592 CellVoltage_152 "Voltage of cell 152";
CM_ SG_ 592 CellVoltage_153 "Voltage of cell 153";
CM_ SG_ 592 CellVoltage_154 "Voltage of cell 154";
CM_ SG_ 592 CellVoltage_155 "Voltage of cell 155";
CM_ SG_ 592 CellVoltage_156 "Voltage of cell 156";
CM_ SG_ 592 CellVoltage_157 "Voltage of cell 157";
CM_ SG_ 592 CellVoltage_158 "Voltage of cell 158";
CM_ SG_ 592 CellVoltage_159 "Voltage of cell 159";
CM_ SG_ 592 CellVoltage_160 "Voltage of cell 160";
CM_ SG_ 592 CellVoltage_161 "Voltage of cell 161";
CM_ SG_ 592 CellVoltage_162 "Voltage of cell 162";
CM_ SG_ 592 CellVoltage_163 "Voltage of cell 163";
CM_ SG_ 592 CellVoltage_164 "Voltage of cell 164";
CM_ SG_ 592 CellVoltage_165 "Voltage of cell 165";
CM_ SG_ 592 CellVoltage_166 "Voltage of cell 166";
CM_ SG_ 592 CellVoltage_167 "Voltage of cell 167";
CM_ SG_ 592 CellVoltage_168 "Voltage of cell 168";
CM_ SG_ 592 CellVoltage_169 "Voltage of cell 169";
CM_ SG_ 592 CellVoltage_170 "Voltage of cell 170";
CM_ SG_ 592 CellVoltage_171 "Voltage of cell 171";
CM_ SG_ 592 CellVoltage_172 "Voltage of cell 172";
CM_ SG_ 592 CellVoltage_173 "Voltage of cell 173";
CM_ SG_ 592 CellVoltage_174 "Voltage of cell 174";
CM_ SG_ 592 CellVoltage_175 "Voltage of cell 175";
CM_ SG_ 592 CellVoltage_176 "Voltage of cell 176";
CM_ SG_ 592 CellVoltage_177 "Voltage of cell 177";
CM_ SG_ 592 CellVoltage_178 "Voltage of cell 178";
CM_ SG_ 592 CellVoltage_179 "Voltage of cell 179";
CM_ SG_ 592 CellVoltage_180 "Voltage of cell 180";
CM_ SG_ 592 CellVoltage_181 "Voltage of cell 181";
CM_ SG_ 592 CellVoltage_182 "Voltage of cell 182";
CM_ SG_ 592 CellVoltage_183 "Voltage of cell 183";
CM_ SG_ 592 CellVoltage_184 "Voltage of cell 184";
CM_ SG_ 592 CellVoltage_185 "Voltage of cell 185";
CM_ SG_ 592 CellVoltage_186 "Voltage of cell 186";
CM_ SG_ 592 CellVoltage_187 "Voltage of cell 187";
CM_ SG_ 592 CellVoltage_188 "Voltage of cell 188";
CM_ SG_ 592 CellVoltage_189 "Voltage of cell 189";
CM_ SG_ 592 CellVoltage_190 "Voltage of cell 190";
CM_ SG_ 592 CellVoltage_191 "Voltage of cell 191";
CM_ SG_ 592 CellVoltage_192 "Voltage of cell 192";
CM_ SG_ 592 CellVoltage_193 "Voltage of cell 193";
CM_ SG_ 592 CellVoltage_194 "Voltage of cell 194";
CM_ SG_ 592 CellVoltage_195 "Voltage of cell 195";
CM_ SG_ 592 CellVoltage_196 "Voltage of cell 196";
CM_ SG_ 592 CellVoltage_197 "Voltage of cell 197";
CM_ SG_ 592 CellVoltage_198 "Voltage of cell 198";
CM_ SG_ 592 CellVoltage_199 "Voltage of cell 199";
CM_ SG_ 592 CellVoltage_200 "Voltage of cell 200";
CM_ SG_ 592 CellVoltage_201 "Voltage of cell 201";
CM_ SG_ 592 CellVoltage_202 "Voltage of cell 202";
CM_ SG_ 592 CellVoltage_203 "Voltage of cell 203";
CM_ SG_ 592 CellVoltage_204 "Voltage of cell 204";
CM_ SG_ 592 CellVoltage_205 "Voltage of cell 205";
CM_ SG_ 592 CellVoltage_206 "Voltage of cell 206";
CM_ SG_ 592 CellVoltage_207 "Voltage of cell 207";
CM_ SG_ 592 CellVoltage_208 "Voltage of cell 208";
CM_ SG_ 592 CellVoltage_209 "Voltage of cell 209";
CM_ SG_ 592 CellVoltage_210 "Voltage of cell 210";
CM_ SG_ 592 CellVoltage_211 "Voltage of cell 211";
CM_ SG_ 592 CellVoltage_212 "Voltage of cell 212";
CM_ SG_ 592 CellVoltage_213 "Voltage of cell 213";
CM_ SG_ 592 CellVoltage_214 "Voltage of cell 214";
CM_ SG_ 592 CellVoltage_215 "Voltage of cell 215";
CM_ BO_ 255 "Fatal error information (in:can_cbs_tx_f_crash-dump.c:CANTX_CrashDump, fv:tx, type:Crash Dump)";
CM_ BO_ 768 "Reserved - for debug/development purpose only (in:can_cbs_rx_f_debug.c:CANRX_Debug, fv:rx, type:Debug)";
CM_ SG_ 768 f_Debug_Mux "Contains signals to set the BMS's RTC driver to certain values";
CM_ SG_ 768 SetHundredthOfSeconds "Instructs the BMS to set the hundredth of seconds in the RTC driver";
CM_ SG_ 768 SetSeconds "Instructs the BMS to set the seconds in the RTC driver";
CM_ SG_ 768 SetMinutes "Instructs the BMS to set the minutes in the RTC driver";
CM_ SG_ 768 SetHours "Instructs the BMS to set the hours in the RTC driver";
CM_ SG_ 768 SetWeekday "Instructs the BMS to set the weekday in the RTC driver";
CM_ SG_ 768 SetDay "Instructs the BMS to set the day in the RTC driver";
CM_ SG_ 768 SetMonth "Instructs the BMS to set the month in the RTC driver";
CM_ SG_ 768 SetYear "Instructs the BMS to set the year in the RTC driver";
CM_ SG_ 768 GetMcuLotNumber "Instructs the BMS to communicate the lot number of the MCU";
CM_ SG_ 768 GetBmsSoftwareVersion "Instructs the BMS to communicate its software version";
CM_ SG_ 768 GetMcuUniqueDieId "Instructs the BMS to communicate the unique ID of the MCU";
CM_ SG_ 768 GetMcuWaferInformation "Instructs the BMS to communicate the wafer information of the MCU it was made of";
CM_ SG_ 768 GetCommitHash "Instructs the BMS to communicate the commit hash the software version was built with";
CM_ SG_ 768 TriggerSoftwareReset "Instructs the BMS to perform a software reset";
CM_ SG_ 768 InitializeFram "Instructs the BMS to initialize the FRAM";
CM_ SG_ 768 RequestRtcTime "Instructs the BMS to communicate its current time";
CM_ SG_ 768 RequestBootTimestamp "Instructs the BMS to communicate its current boot timestamp";
CM_ SG_ 768 RequestUptime "Instructs the BMS to communicate its current uptime";
CM_ SG_ 768 FramCalibrationChannel "Set the calibration channel";
CM_ SG_ 768 CalibrationValue11 "Set slope calibration value";
CM_ SG_ 768 CalibrationChannel10 "Set the calibration channel";
CM_ SG_ 768 CalibrationValue10 "Set offset calibration value";
CM_ BO_ 771 "Contains the build configuration (in:can_cbs_tx_f_debug-build-configuration.c:CANTX_DebugBuildConfiguration, fv:tx, type:Debug)";
CM_ BO_ 772 "Contains the hardware identifications (in:can_cbs_tx_f_debug-identify-hardware.c:CANTX_DebugIdentifyHardware, fv:tx, type:Debug)";
CM_ BO_ 769 "Responses to the 'Debug' message (in:can_cbs_tx_f_debug-response.c:CANTX_DebugResponse, fv:tx, type:Debug)";
CM_ SG_ 769 Number "wafer number of the MCU (read from DIEDL register)";
CM_ SG_ 769 CoordinateX "x coordinate of the MCU die on the wafer (read from DIEIDL register)";
CM_ SG_ 769 CoordinateY "y coordinate of the MCU die on the wafer (read from DIEIDL register)";
CM_ SG_ 769 LotNumber "lot number of the MCU (read from DIEIDH register)";
CM_ SG_ 769 UniqueId "Content of Device Identification Register (DEVID)";
CM_ SG_ 769 MeasurementValue "Set the calibration value";
CM_ SG_ 769 CalibrationChannel8 "Set the calibration channel";
CM_ SG_ 769 CalibrationValue9 "Configured slope calibration value";
CM_ SG_ 769 CalibrationChannel9 "Set the calibration channel";
CM_ SG_ 769 CalibrationValue10 "Configured offset calibration value";
CM_ SG_ 769 CalibrationChannel10 "Set the calibration channel";
CM_ BO_ 770 "(in:can_cbs_tx_f_debug-unsupported-multiplexer-values.c:CANTX_DebugUnsupportedMultiplexerVal, fv:tx, type:Debug)";
CM_ BO_ 562 "Electrical limit information (in:can_cbs_tx_f_pack-limits.c:CANTX_PackLimits, fv:tx, type:Pack Information)";
CM_ SG_ 562 MaximumChargeCurrent "Maximum battery pack charge current";
CM_ SG_ 562 MaximumDischargeCurrent "Maximum battery pack discharge current";
CM_ SG_ 562 MaximumChargePower "Maximum battery pack charge power";
CM_ SG_ 562 MaximumDischargePower "Maximum battery pack discharge power";
CM_ SG_ 562 MaximumBatteryVoltage "Maximum allowed battery pack voltage (defined by either cell limits or restricted by the charging algorithm)";
CM_ SG_ 562 MinimumBatteryVoltage "Minimum allowed battery pack voltage (defined by the cell limits or application specification)";
CM_ BO_ 560 "(in:can_cbs_tx_f_pack-minimum-maximum-values.c:CANTX_PackMinimumMaximumTemp, fv:tx, type:Pack Information)";
CM_ SG_ 560 MaximumCellTemperature "Maximum cell temperature of an individual cell in all connected strings, if no string connected, the maximum value of whole system is transmitted";
CM_ SG_ 560 MinimumCellTemperature "Minimum cell temperature of an individual cell in all connected strings, if no string connected, the minimum value of whole system is transmitted";
CM_ SG_ 560 SensorMaximumCellTemperature "Sensor index of the sensor with the highest temperature";
CM_ SG_ 560 SensorMinimumCellTemperature "Sensor index of the sensor with the lowest temperature";
CM_ SG_ 560 ModuleMaximumCellTemperature "Module index of the sensor with the highest temperature";
CM_ SG_ 560 ModuleMinimumCellTemperature "Module index of the sensor with the lowest temperature";
CM_ SG_ 560 StringMinimumCellTemperature "String index of the sensor with the highest temperature";
CM_ SG_ 560 StringMaximumCellTemperature "String index of the sensor with the lowest temperature";
CM_ BO_ 561 "(in:can_cbs_tx_f_pack-minimum-maximum-values.c:CANTX_PackMinimumMaximumVoltage, fv:tx, type:Pack Information)";
CM_ SG_ 561 MinimumCellVoltage "Minimum cell voltage of an idividual cell in all connected strings, if no string connected maximum value of whole system is transmitted";
CM_ SG_ 561 MaximumCellVoltage "Maximum cell voltage of an idividual cell in all connected strings, if no string connected maximum value of whole system is transmitted";
CM_ SG_ 561 MaximumCellVoltageCellIndex "Cell index of cell with the highest Voltage in the battery";
CM_ SG_ 561 MinimumCellVoltageCellIndex "Cell index of cell with the lowest Voltage in the battery";
CM_ SG_ 561 MaximumCellVoltageModuleIndex "Module index of the cell with the highest Voltage";
CM_ SG_ 561 MinimumCellVoltageModuleIndex "Module index of the cell with the lowest Voltage";
CM_ SG_ 561 MinimumCellVoltageStringIndex "String index of the cellwith the highest Voltage";
CM_ SG_ 561 MaximumCellVoltageStringIndex "String index of the cell with the lowest Voltage";
CM_ BO_ 565 "(in:can_cbs_tx_f_pack-state-estimation.c:CANTX_PackStateEstimation, fv:tx, type:Pack Information)";
CM_ SG_ 565 MinimumSoc "Minimum SOC currently connected to HV bus (100% if all strings connected and all strings at 100%)";
CM_ SG_ 565 MinimumSoe "Minimum SOE currently connected to HV bus (100% if all strings connected and all strings at 100%)";
CM_ SG_ 565 Energy "Energy left in Wh that is currently connected to HV bus";
CM_ SG_ 565 MaximumSoc "Maximum SOC currently connected to HV bus (100% if all strings connected and all strings at 100%)";
CM_ SG_ 565 MaximumSoe "Maximum SOE currently connected to HV bus (100% if all strings connected and all strings at 100%)";
CM_ BO_ 563 "(in:can_cbs_tx_f_pack-values-p0.c:CANTX_PackValuesP0, fv:tx, type:Pack Information)";
CM_ SG_ 563 Current "Battery pack current";
CM_ SG_ 563 BatteryVoltage "Battery voltage between negative and positive pole of the battery";
CM_ SG_ 563 BusVoltage "Battery voltage between negative pole and after main positive contactor TODO";
CM_ SG_ 563 Power "Battery power";
CM_ BO_ 564 "(in:can_cbs_tx_f_pack-values-p1.c:CANTX_PackValuesP1, fv:tx, type:Pack Information)";
CM_ SG_ 564 InsulationResistance "Shows the latest measured insulation resistance value";
CM_ BO_ 577 "Message contains minimum and maximum cell temperature values and their indices of respective string (in:can_cbs_tx_f_string-minimum-maximum-values.c:CANTX_StringMinimumMaximumTemp, fv:tx, type:String Information)";
CM_ SG_ 577 MaximumCellTemperature "Maximum cell temperature in string 0";
CM_ SG_ 577 MinimumCellTemperature "Minium cell temperature in string 0";
CM_ SG_ 577 SensorMaximumCellTemperature "Sensor index of the sensor with the highest temperature";
CM_ SG_ 577 SensorMinimumCellTemperature "Sensor index of the sensor with the lowest temperature";
CM_ SG_ 577 ModuleMaximumCellTemperature "Module index of the sensor with the highest temperature";
CM_ SG_ 577 ModuleMinimumCellTemperature "Module index of the sensor with the lowest temperature";
CM_ BO_ 578 "Message contains minimum and maximum cell voltage values and their indices of respective string (in:can_cbs_tx_f_string-minimum-maximum-values.c:CANTX_StringMinimumMaximumVoltage, fv:tx, type:String Information)";
CM_ SG_ 578 MinimumCellVoltage "Minimum cell voltage in string 0";
CM_ SG_ 578 MaximumCellVoltage "Maximum cell voltage in string 0";
CM_ SG_ 578 SensorMaximumCellVoltage "Sensor index of the sensor with the highest Voltage";
CM_ SG_ 578 SensorMinimumCellVoltage "Sensor index of the sensor with the lowest Voltage";
CM_ SG_ 578 ModuleMaximumCellVoltage "Module index of the sensor with the highest Voltage";
CM_ SG_ 578 ModuleMinimumCellVoltage "Module index of the sensor with the lowest Voltage";
CM_ BO_ 576 "Message contains string related error and warning flags (in:can_cbs_tx_f_string-state.c:CANTX_StringState, fv:tx, type:String Information)";
CM_ SG_ 576 IsStringConnected "0x00: String not connected, 0x01: String connected to HV bus";
CM_ SG_ 576 IsBalancingActive "0x00: No cell in this string is current balanced, 0x01: At least one cell in this string is currently balanced";
CM_ SG_ 576 OvertemperatureChargeMslError "0x00: No error, 0x01: Error: Flag will be set if maximum cell temperature is above 45 degree celsius.";
CM_ SG_ 576 UndertemperatureChargeMslError "0x00: No error, 0x01: Error: Flag will be set if minimum cell temperature is below 0 degree celsius.";
CM_ SG_ 576 OvertemperatureDischargeMslError "0x00: No error, 0x01: Error: Flag will be set if maximum cell temperature is above 60 degree celsius.";
CM_ SG_ 576 UndertemperatureDischargeMslErro "Flag indicates if the minimum cell temperature is below -20 degree celsius during discharge";
CM_ SG_ 576 CellOvercurrentChargeMslError "Flag will be set if string charge current is above .";
CM_ SG_ 576 CellOvercurrentDischargeMslError "0x00: No error, 0x01: Error: Flag will be set if discharge current is above maximum string current.";
CM_ SG_ 576 OvervoltageMslError "0x00: No error, 0x01: Error: Flag will be set if maximum cell voltage is above 4200mV.";
CM_ SG_ 576 UndervoltageMslError "0x00: No error, 0x01: Error: Flag will be set if minimum cell voltage is below 3000mV. This equals roughly 4% remaining SOC. Minimum datasheet values if 2500mV.";
CM_ SG_ 576 DeepDischargeError "A deep dicharge in at least one cell in the string has been detected";
CM_ SG_ 576 StringCurrentMeasurementError "Current measurement not working";
CM_ SG_ 576 PositiveContactorError "0x00: No error, 0x01: Error";
CM_ SG_ 576 OpenWireError "Indicates broken/not connected sense wire to at least one cell in the string";
CM_ SG_ 576 CellVoltagePlausibilityError "0x00: No error, 0x01: Error";
CM_ SG_ 576 CellTemperaturePlausibilityError "0x00: No error, 0x01: Error";
CM_ SG_ 576 StringVoltagePlausibilityError "0x00: No error, 0x01: Error";
CM_ SG_ 576 SlaveHardwareError "0x00: No error, 0x01: Error";
CM_ SG_ 576 DaisyChainBaseCommunicationError "Indicates whether a generic error (i.e., SPI communication error) occurred in one of the AFEs in the main diasy chain (i.e., base diasy chain) in string 0";
CM_ SG_ 576 DaisyChainBaseCrcError "Indicates whether a CRC error occurred in one of the AFEs in the main diasy chain (i.e., base diasy chain) in string 0";
CM_ SG_ 576 DaisyChainBaseVoltMeasOorError "Indicates whether an error occurred during the voltage measurement in one of the AFEs in the main diasy chain (i.e., base diasy chain) in string 0";
CM_ SG_ 576 DaisyChainBaseTempMeasOorError "Indicates whether an error occurred during the temperature measurement in one of the AFEs in the main diasy chain (i.e., base diasy chain) in string 0";
CM_ SG_ 576 CoulombCountingMeasurementError "Dedeciated coulomb counting sensing is not working";
CM_ SG_ 576 EnergyCountingMeasurementError "Dedeciated energy counting sensing is not working";
CM_ SG_ 576 VoltageSpreadPlausibilityError "0x00: No error, 0x01: Error";
CM_ SG_ 576 TemperatureSpreadPlausibilityErr "0x00: No error, 0x01: Error";
CM_ SG_ 576 IsStringFuseBlown "Indicates whether the fuse is blown or not";
CM_ SG_ 576 NegativeContactorError "0x00: No error, 0x01: Error";
CM_ SG_ 576 StringVoltageMeasurementError "Dedicated string voltage measurement not working";
CM_ SG_ 576 FusedStringVoltageMeasurementErr "Dedicated fused string voltage measurement not working";
CM_ SG_ 576 PackVoltageMeasurementError "Dedicated pack voltage measurement not working";
CM_ SG_ 576 StringOvercurrentError "Flag will be set if current capability of the string is violated (BS_MAXIMUM_STRING_CURRENT_mA)";
CM_ BO_ 581 "Message contains SOC, SOE and SOH state estimations (in:can_cbs_tx_f_string-state-estimation.c:CANTX_StringStateEstimation, fv:tx, type:String Information)";
CM_ SG_ 581 MinimumSoe "SOE is depending on current direction, if battery system is charging: SOE_max is transmitted, else SOE_min";
CM_ SG_ 581 Energy "Remaining energy left in this string";
CM_ SG_ 581 MaximumSoe "SOE is depending on current direction, if battery system is charging: SOE_max is transmitted, else SOE_min";
CM_ BO_ 579 "Message contains string voltage, current and power (in:can_cbs_tx_f_string-values-p0.c:CANTX_StringValuesP0, fv:tx, type:String Information)";
CM_ SG_ 579 Current "Current of string 0";
CM_ SG_ 579 Voltage "Voltage of string 0";
CM_ SG_ 579 Power "Power of string 0";
CM_ BO_ 580 "Message contains energy counting value (in:can_cbs_tx_f_string-values-p1.c:CANTX_StringValuesP1, fv:tx, type:String Information)";
CM_ SG_ 580 EnergyCounter "Energy counting value for string 0";
CM_ BO_ 537 "Message contains the state of our System state machine(in:can_cbs_tx_f_sys-state.c:CANTX_SysState, fv:tx, type:State Machine Information)";
CM_ BO_ 55 "(in:can_cbs_rx_imd_bender-iso165c-info.c:CANRX_ImdBenderIso165cInfo, fv:rx, type:Insulation Measurement Device)";
CM_ BO_ 34 "(in:can_cbs_tx_imd_bender-iso165c-request.c:CANTX_ImdRequest, fv:tx, type:Insulation Measurement Device)";
CM_ BO_ 35 "(in:can_cbs_rx_imd_bender-iso165c-response.c:CANRX_ImdBenderIso165cResponse, fv:rx, type:Insulation Measurement Device)";
BA_DEF_ BO_  "GenMsgCycleTime" INT 0 65535;
BA_DEF_ SG_  "GenSigStartValue" FLOAT -3.4E+038 3.4E+038;
BA_DEF_ SG_  "SigType" ENUM "Default","Range","RangeSigned","ASCII","Discrete","Control","ReferencePGN","DTC","StringDelimiter","StringLength","StringLengthControl","MessageCounter","MessageChecksum";
BA_DEF_DEF_  "GenMsgCycleTime" 0;
BA_DEF_DEF_  "GenSigStartValue" 0;
BA_DEF_DEF_  "SigType" "Default";
BA_ "GenMsgCycleTime" BO_ 608 4500;
BA_ "GenMsgCycleTime" BO_ 592 5400;
BA_ "GenMsgCycleTime" BO_ 562 100;
BA_ "GenMsgCycleTime" BO_ 560 100;
BA_ "GenMsgCycleTime" BO_ 561 100;
BA_ "GenMsgCycleTime" BO_ 565 1000;
BA_ "GenMsgCycleTime" BO_ 563 100;
BA_ "GenMsgCycleTime" BO_ 564 100;
BA_ "GenMsgCycleTime" BO_ 577 100;
BA_ "GenMsgCycleTime" BO_ 578 100;
BA_ "GenMsgCycleTime" BO_ 576 100;
BA_ "GenMsgCycleTime" BO_ 581 1000;
BA_ "GenMsgCycleTime" BO_ 579 100;
BA_ "GenMsgCycleTime" BO_ 580 100;
BA_ "GenMsgCycleTime" BO_ 537 100;
BA_ "GenMsgCycleTime" BO_ 55 1000;
BA_ "GenSigStartValue" SG_ 2147483904 IVT_HVBattery_Status 1;
BA_ "GenSigStartValue" SG_ 2147483904 IVT_HVBattery 524288;
BA_ "GenSigStartValue" SG_ 2147483904 IVT_Current_Status 1;
BA_ "GenSigStartValue" SG_ 2147483904 IVT_Current 8388608;
BA_ "GenSigStartValue" SG_ 2147483911 IVT_ShuntTemp 70;
BA_ "GenSigStartValue" SG_ 2147483905 IVT_VoltageLinkPlus_Status 1;
BA_ "GenSigStartValue" SG_ 2147483905 IVT_VoltageLinkMinus_Status 1;
BA_ "GenSigStartValue" SG_ 2147483905 IVT_VoltageLinkMinus 524288;
BA_ "GenSigStartValue" SG_ 2147483905 IVT_VoltageLinkPlus 524288;
BA_ "GenSigStartValue" SG_ 2147483906 IVT_VoltagePackMinus_Status 1;
BA_ "GenSigStartValue" SG_ 2147483906 IVT_VoltagePackMinus 524288;
BA_ "GenSigStartValue" SG_ 2147483906 IVT_VoltagePackPlus_Status 1;
BA_ "GenSigStartValue" SG_ 2147483906 IVT_VoltagePackPlus 524288;
BA_ "GenSigStartValue" SG_ 2147483907 IVT_VoltageLinkPreCharge_Status 1;
BA_ "GenSigStartValue" SG_ 2147483907 IVT_VoltageLinkPreCharge 524288;
BA_ "GenSigStartValue" SG_ 2147483907 IVT_VoltageLinkDiff_Status 1;
BA_ "GenSigStartValue" SG_ 2147483907 IVT_VoltageLinkDiff 524288;
BA_ "GenSigStartValue" SG_ 34 MS_IMC_MEAN_FACTOR 10;
BA_ "GenSigStartValue" SG_ 34 MS_IMC_R_ISO_WRN_THR 200;
BA_ "GenSigStartValue" SG_ 34 MC_IMC_SELFTEST_SCR 6;
BA_ "GenSigStartValue" SG_ 34 MS_IMC_R_ISO_ERR_THR 100;
BA_ "SigType" SG_ 769 shortHashLow7 3;
BA_ "SigType" SG_ 769 shortHashHigh7 3;
VAL_ 608 f_CellTemperatures_Mux 0 "CellTemperatures_000_005" 1 "CellTemperatures_006_011" 2 "CellTemperatures_012_017" 3 "CellTemperatures_018_023" 4 "CellTemperatures_024_029" 5 "CellTemperatures_030_035" 6 "CellTemperatures_036_041" 7 "CellTemperatures_042_047" 8 "CellTemperatures_048_053" 9 "CellTemperatures_054_059" 10 "CellTemperatures_060_065" 11 "CellTemperatures_066_071" 12 "CellTemperatures_072_077" 13 "CellTemperatures_078_083" 14 "CellTemperatures_084_089" 15 "CellTemperatures_090_095" 16 "CellTemperatures_096_101" 17 "CellTemperatures_102_107" 18 "CellTemperatures_108_113" 19 "CellTemperatures_114_119" 20 "CellTemperatures_120_125" 21 "CellTemperatures_126_131" 22 "CellTemperatures_132_137" 23 "CellTemperatures_138_143" 24 "CellTemperatures_144_149" 25 "CellTemperatures_150_155" 26 "CellTemperatures_156_161" 27 "CellTemperatures_162_167" 28 "CellTemperatures_168_173" 29 "CellTemperatures_174_179";
VAL_ 592 f_CellVoltages_Mux 0 "CellVoltages_000_003" 1 "CellVoltages_004_007" 2 "CellVoltages_008_011" 3 "CellVoltages_012_015" 4 "CellVoltages_016_019" 5 "CellVoltages_020_023" 6 "CellVoltages_024_027" 7 "CellVoltages_028_031" 8 "CellVoltages_032_035" 9 "CellVoltages_036_039" 10 "CellVoltages_040_043" 11 "CellVoltages_044_047" 12 "CellVoltages_048_051" 13 "CellVoltages_052_055" 14 "CellVoltages_056_059" 15 "CellVoltages_060_063" 16 "CellVoltages_064_067" 17 "CellVoltages_068_071" 18 "CellVoltages_072_075" 19 "CellVoltages_076_079" 20 "CellVoltages_080_083" 21 "CellVoltages_084_087" 22 "CellVoltages_088_091" 23 "CellVoltages_092_095" 24 "CellVoltages_096_099" 25 "CellVoltages_100_103" 26 "CellVoltages_104_107" 27 "CellVoltages_108_111" 28 "CellVoltages_112_115" 29 "CellVoltages_116_119" 30 "CellVoltages_120_123" 31 "CellVoltages_124_127" 32 "CellVoltages_128_131" 33 "CellVoltages_132_135" 34 "CellVoltages_136_139" 35 "CellVoltages_140_143" 36 "CellVoltages_144_147" 37 "CellVoltages_148_151" 38 "CellVoltages_152_155" 39 "CellVoltages_156_159"
40 "CellVoltages_160_163" 41 "CellVoltages_164_167" 42 "CellVoltages_168_171" 43 "CellVoltages_172_175" 44 "CellVoltages_176_179" 45 "CellVoltages_180_183" 46 "CellVoltages_184_187" 47 "CellVoltages_188_191" 48 "CellVoltages_192_195" 49 "CellVoltages_196_199" 50 "CellVoltages_200_203" 51 "CellVoltages_204_207" 52 "CellVoltages_208_211" 53 "CellVoltages_212_215";
VAL_ 255 f_CrashDump_Mux 0 "StackOverflow";
VAL_ 768 f_Debug_Mux 1 "Rtc" 0 "VersionInfo" 2 "SoftwareReset" 3 "FramInitialization" 4 "TimeInfo" 5 "UptimeInfo" 11 "SetSlopeFramCalibrationValue" 7 "IdentifyHardware" 9 "GetMeasValueForFramCalibration" 8 "FramRequestCalibrationValues" 10 "SetOffsetFramCalibrationValue";
VAL_ 771 f_DebugBuildConfiguration_Mux 36 "BatteryCell_MaxDischargeTemp" 39 "BatteryCell_MinDischargeTemp" 34 "BatteryCell_MaxChargeTemp" 38 "BatteryCell_MinChargeTemp" 37 "BatteryCell_MaxVolt" 40 "BatteryCell_MinVolt" 32 "BatteryCell" 33 "BatteryCell_MaxChargeCur" 35 "BatteryCell_MaxDischargeCur" 48 "BatterySystem_General1" 55 "BatterySystem_TotalNumbers" 51 "BatterySystem_CurrentSensor" 50 "BatterySystem_Contactors" 52 "BatterySystem_Fuse" 49 "BatterySystem_General2" 53 "BatterySystem_MaxCurrent" 16 "Application" 0 "Slave";
VAL_ 772 f_DebugIdentifyHardware_Mux 0 "BMS-Master" 1 "BMS-Slaves";
VAL_ 769 f_DebugResponse_Mux 3 "McuWaferInformation" 2 "McuLotNumber" 1 "McuUniqueDieId" 0 "BmsSoftwareVersionInfo" 15 "BootInformation" 4 "RtcTime" 6 "CommitHashLow7" 5 "CommitHashHigh7" 7 "Uptime" 14 "BootTimestamp" 8 "FramMeasValueForCalibration" 9 "FramSlopeCalibrationValue" 10 "FramOffsetCalibrationValue";
VAL_ 577 f_StringMinMaxCellTemperature_Mux 0 "String0";
VAL_ 578 f_StringMinMaxCellVoltage_Mux 0 "String0";
VAL_ 576 f_StringState_Mux 0 "String0";
VAL_ 581 f_StringStateEstimation_Mux 0 "String0";
VAL_ 579 f_StringValuesP0_Mux 0 "String0";
VAL_ 580 f_StringValuesP1_Mux 0 "String0";
VAL_ 34 IMD_BenderIso165c_Request_Mux 61 "S_IMC_GET_MANUFACTURER" 223 "S_VIFC_GET_POWER_MODE" 201 "S_VIFC_CTL_POWER_MODE" 222 "S_VIFC_GET_VERSION" 51 "S_IMC_GET_VERSION" 59 "S_IMC_GET_EEPROM" 203 "S_VIFC_CTL_MEASUREMENT" 43 "S_IMC_SET_MEAN_FACTOR" 42 "S_IMC_SET_EEPROM" 202 "S_VIFC_CTL_LOCK" 0 "S_VIFC_CTL_DUMMY" 210 "S_VIFC_SET_HV_RELAIS" 41 "S_IMC_SET_R_ISO_WRN_THR" 34 "S_IMC_CTL_CALIB" 33 "S_IMC_CTL_SELFTEST" 40 "S_IMC_SET_R_ISO_ERR_THR" 255 "S_IMD_ERROR_FRAME" 226 "S_VIFC_GET_IMC_ALIVE" 225 "S_VIFC_GET_TEMP" 224 "S_VIFC_GET_LOCK" 221 "S_VIFC_GET_HV_RELAIS" 220 "S_VIFC_GET_STATUS" 200 "S_VIFC_CTL_IMC_RESET" 90 "S_IMC_GET_TEST_CNT" 60 "S_IMC_GET_MEAN_FACTOR" 58 "S_IMC_GET_HV_2" 57 "S_IMC_GET_R_ISO_WRN_THR" 55 "S_IMC_GET_STATUS" 54 "S_IMC_GET_HV_1" 53 "S_IMC_GET_R_ISO" 50 "S_IMC_GET_R_ISO_ERR_THR" 35 "S_IMC_CTL_SYS_UPDATE";
VAL_ 35 IMD_BenderIso165c_Response_Mux 220 "S_VIFC_GET_STATUS" 55 "S_IMC_GET_STATUS" 222 "S_VIFC_GET_VERSION" 51 "S_IMC_GET_VERSION" 61 "S_IMC_GET_MANUFACTURER" 53 "S_IMC_GET_R_ISO" 225 "S_VIFC_GET_TEMP" 226 "S_VIFC_GET_IMC_ALIVE" 223 "S_VIFC_GET_POWER_MODE" 201 "S_VIFC_CTL_POWER_MODE" 43 "S_IMC_SET_MEAN_FACTOR" 42 "S_IMC_SET_EEPROM" 34 "S_IMC_CTL_CALIB" 41 "S_IMC_SET_R_ISO_WRN_THR" 40 "S_IMC_SET_R_ISO_ERR_THR" 202 "S_VIFC_CTL_LOCK" 203 "S_VIFC_CTL_MEASUREMENT" 210 "S_VIFC_SET_HV_RELAIS" 59 "S_IMC_GET_EEPROM" 60 "S_IMC_GET_MEAN_FACTOR" 224 "S_VIFC_GET_LOCK" 221 "S_VIFC_GET_HV_RELAIS" 255 "S_IMD_ERROR_FRAME" 58 "S_IMC_GET_HV_2" 54 "S_IMC_GET_HV_1" 57 "S_IMC_GET_R_ISO_WRN_THR" 50 "S_IMC_GET_R_ISO_ERR_THR" 33 "S_IMC_CTL_SELFTEST" 90 "S_IMC_GET_TEST_CNT" 0 "S_VIFC_CTL_DUMMY" 200 "S_VIFC_CTL_IMC_RESET" 35 "S_IMC_CTL_SYS_UPDATE";
VAL_ 2147485697 IVT_Coulomb_Status 15 "Error" 14 "Not_Available" 13 "reserved13" 12 "reserved12" 11 "reserved11" 10 "reserved10" 9 "reserved9" 8 "reserved8" 7 "reserved7" 6 "reserved6" 5 "reserved5" 4 "reserved4" 3 "Overcurrent L2" 2 "Overcurrent L1" 1 "Init" 0 "Valid";
VAL_ 2147485698 IVT_Energy_Status 15 "Error" 14 "Not_Available" 13 "reserved13" 12 "reserved12" 11 "reserved11" 10 "reserved10" 9 "reserved9" 8 "reserved8" 7 "reserved7" 6 "reserved6" 5 "reserved5" 4 "reserved4" 3 "Overload L2" 2 "Overload L1" 1 "Init" 0 "Valid";
VAL_ 2147483904 IVT_HVBattery_Status 15 "Error" 14 "Not_Available" 13 "reserved13" 12 "reserved12" 11 "reserved11" 10 "reserved10" 9 "reserved9" 8 "reserved8" 7 "reserved7" 6 "reserved6" 5 "reserved5" 4 "reserved4" 3 "reserved3" 2 "Overvoltage L1" 1 "Init" 0 "Valid";
VAL_ 2147483904 IVT_Current_Status 15 "Error" 14 "Not_Available" 13 "reserved13" 12 "reserved12" 11 "reserved11" 10 "reserved10" 9 "reserved9" 8 "reserved8" 7 "reserved7" 6 "reserved6" 5 "reserved5" 4 "reserved4" 3 "Overcurrent L2" 2 "Overcurrent L1" 1 "Init" 0 "Valid";
VAL_ 2147483911 IVT_ShuntTemp_Status 15 "Error" 14 "Not_Available" 13 "reserved13" 12 "reserved12" 11 "reserved11" 10 "reserved10" 9 "reserved9" 8 "reserved8" 7 "reserved7" 6 "reserved6" 5 "reserved5" 4 "reserved4" 3 "Undertemperature" 2 "Overtemperature" 1 "Init" 0 "Valid";
VAL_ 2147483905 IVT_VoltageLinkPlus_Status 15 "Error" 14 "Not_Available" 13 "reserved13" 12 "reserved12" 11 "reserved11" 10 "reserved10" 9 "reserved9" 8 "reserved8" 7 "reserved7" 6 "reserved6" 5 "reserved5" 4 "reserved4" 3 "reserved3" 2 "Overvoltage L1" 1 "Init" 0 "Valid";
VAL_ 2147483905 IVT_VoltageLinkMinus_Status 15 "Error" 14 "Not_Available" 13 "reserved13" 12 "reserved12" 11 "reserved11" 10 "reserved10" 9 "reserved9" 8 "reserved8" 7 "reserved7" 6 "reserved6" 5 "reserved5" 4 "reserved4" 3 "reserved3" 2 "Overvoltage L1" 1 "Init" 0 "Valid";
VAL_ 2147483906 IVT_VoltagePackMinus_Status 15 "Error" 14 "Not_Available" 13 "reserved13" 12 "reserved12" 11 "reserved11" 10 "reserved10" 9 "reserved9" 8 "reserved8" 7 "reserved7" 6 "reserved6" 5 "reserved5" 4 "reserved4" 3 "reserved3" 2 "Overvoltage L1" 1 "Init" 0 "Valid";
VAL_ 2147483906 IVT_VoltagePackPlus_Status 15 "Error" 14 "Not_Available" 13 "reserved13" 12 "reserved12" 11 "reserved11" 10 "reserved10" 9 "reserved9" 8 "reserved8" 7 "reserved7" 6 "reserved6" 5 "reserved5" 4 "reserved4" 3 "reserved3" 2 "Overvoltage L1" 1 "Init" 0 "Valid";
VAL_ 2147483907 IVT_VoltageLinkPreCharge_Status 15 "Error" 14 "Not_Available" 13 "reserved13" 12 "reserved12" 11 "reserved11" 10 "reserved10" 9 "reserved9" 8 "reserved8" 7 "reserved7" 6 "reserved6" 5 "reserved5" 4 "reserved4" 3 "reserved3" 2 "Overvoltage L1" 1 "Init" 0 "Valid";
VAL_ 2147483907 IVT_VoltageLinkDiff_Status 15 "Error" 14 "Not_Available" 13 "reserved13" 12 "reserved12" 11 "reserved11" 10 "reserved10" 9 "reserved9" 8 "reserved8" 7 "reserved7" 6 "reserved6" 5 "reserved5" 4 "reserved4" 3 "reserved3" 2 "Overvoltage L1" 1 "Init" 0 "Valid";
VAL_ 608 CellTemperature_000_invalidFlag 0 "Invalid" 1 "Valid";
VAL_ 608 CellTemperature_001_invalidFlag 0 "Invalid" 1 "Valid";
VAL_ 608 CellTemperature_002_invalidFlag 0 "Invalid" 1 "Valid";
VAL_ 608 CellTemperature_003_invalidFlag 0 "Invalid" 1 "Valid";
VAL_ 608 CellTemperature_004_invalidFlag 0 "Invalid" 1 "Valid";
VAL_ 608 CellTemperature_005_invalidFlag 0 "Invalid" 1 "Valid";
VAL_ 608 CellTemperature_006_invalidFlag 0 "Invalid" 1 "Valid";
VAL_ 608 CellTemperature_007_invalidFlag 0 "Invalid" 1 "Valid";
VAL_ 608 CellTemperature_008_invalidFlag 0 "Invalid" 1 "Valid";
VAL_ 608 CellTemperature_009_invalidFlag 0 "Invalid" 1 "Valid";
VAL_ 608 CellTemperature_010_invalidFlag 0 "Invalid" 1 "Valid";
VAL_ 608 CellTemperature_011_invalidFlag 0 "Invalid" 1 "Valid";
VAL_ 608 CellTemperature_012_invalidFlag 0 "Invalid" 1 "Valid";
VAL_ 608 CellTemperature_013_invalidFlag 0 "Invalid" 1 "Valid";
VAL_ 608 CellTemperature_014_invalidFlag 0 "Invalid" 1 "Valid";
VAL_ 608 CellTemperature_015_invalidFlag 0 "Invalid" 1 "Valid";
VAL_ 608 CellTemperature_016_invalidFlag 0 "Invalid" 1 "Valid";
VAL_ 608 CellTemperature_017_invalidFlag 0 "Invalid" 1 "Valid";
VAL_ 608 CellTemperature_018_invalidFlag 0 "Invalid" 1 "Valid";
VAL_ 608 CellTemperature_019_invalidFlag 0 "Invalid" 1 "Valid";
VAL_ 608 CellTemperature_020_invalidFlag 0 "Invalid" 1 "Valid";
VAL_ 608 CellTemperature_021_invalidFlag 0 "Invalid" 1 "Valid";
VAL_ 608 CellTemperature_022_invalidFlag 0 "Invalid" 1 "Valid";
VAL_ 608 CellTemperature_023_invalidFlag 0 "Invalid" 1 "Valid";
VAL_ 608 CellTemperature_024_invalidFlag 0 "Invalid" 1 "Valid";
VAL_ 608 CellTemperature_025_invalidFlag 0 "Invalid" 1 "Valid";
VAL_ 608 CellTemperature_026_invalidFlag 0 "Invalid" 1 "Valid";
VAL_ 608 CellTemperature_027_invalidFlag 0 "Invalid" 1 "Valid";
VAL_ 608 CellTemperature_028_invalidFlag 0 "Invalid" 1 "Valid";
VAL_ 608 CellTemperature_029_invalidFlag 0 "Invalid" 1 "Valid";
VAL_ 608 CellTemperature_030_invalidFlag 0 "Invalid" 1 "Valid";
VAL_ 608 CellTemperature_031_invalidFlag 0 "Invalid" 1 "Valid";
VAL_ 608 CellTemperature_032_invalidFlag 0 "Invalid" 1 "Valid";
VAL_ 608 CellTemperature_033_invalidFlag 0 "Invalid" 1 "Valid";
VAL_ 608 CellTemperature_034_invalidFlag 0 "Invalid" 1 "Valid";
VAL_ 608 CellTemperature_035_invalidFlag 0 "Invalid" 1 "Valid";
VAL_ 608 CellTemperature_036_invalidFlag 0 "Invalid" 1 "Valid";
VAL_ 608 CellTemperature_037_invalidFlag 0 "Invalid" 1 "Valid";
VAL_ 608 CellTemperature_038_invalidFlag 0 "Invalid" 1 "Valid";
VAL_ 608 CellTemperature_039_invalidFlag 0 "Invalid" 1 "Valid";
VAL_ 608 CellTemperature_040_invalidFlag 0 "Invalid" 1 "Valid";
VAL_ 608 CellTemperature_041_invalidFlag 0 "Invalid" 1 "Valid";
VAL_ 608 CellTemperature_042_invalidFlag 0 "Invalid" 1 "Valid";
VAL_ 608 CellTemperature_043_invalidFlag 0 "Invalid" 1 "Valid";
VAL_ 608 CellTemperature_044_invalidFlag 0 "Invalid" 1 "Valid";
VAL_ 608 CellTemperature_045_invalidFlag 0 "Invalid" 1 "Valid";
VAL_ 608 CellTemperature_046_invalidFlag 0 "Invalid" 1 "Valid";
VAL_ 608 CellTemperature_047_invalidFlag 0 "Invalid" 1 "Valid";
VAL_ 608 CellTemperature_048_invalidFlag 0 "Invalid" 1 "Valid";
VAL_ 608 CellTemperature_049_invalidFlag 0 "Invalid" 1 "Valid";
VAL_ 608 CellTemperature_050_invalidFlag 0 "Invalid" 1 "Valid";
VAL_ 608 CellTemperature_051_invalidFlag 0 "Invalid" 1 "Valid";
VAL_ 608 CellTemperature_052_invalidFlag 0 "Invalid" 1 "Valid";
VAL_ 608 CellTemperature_053_invalidFlag 0 "Invalid" 1 "Valid";
VAL_ 608 CellTemperature_054_invalidFlag 0 "Invalid" 1 "Valid";
VAL_ 608 CellTemperature_055_invalidFlag 0 "Invalid" 1 "Valid";
VAL_ 608 CellTemperature_056_invalidFlag 0 "Invalid" 1 "Valid";
VAL_ 608 CellTemperature_057_invalidFlag 0 "Invalid" 1 "Valid";
VAL_ 608 CellTemperature_058_invalidFlag 0 "Invalid" 1 "Valid";
VAL_ 608 CellTemperature_059_invalidFlag 0 "Invalid" 1 "Valid";
VAL_ 608 CellTemperature_060_invalidFlag 0 "Invalid" 1 "Valid";
VAL_ 608 CellTemperature_061_invalidFlag 0 "Invalid" 1 "Valid";
VAL_ 608 CellTemperature_062_invalidFlag 0 "Invalid" 1 "Valid";
VAL_ 608 CellTemperature_063_invalidFlag 0 "Invalid" 1 "Valid";
VAL_ 608 CellTemperature_064_invalidFlag 0 "Invalid" 1 "Valid";
VAL_ 608 CellTemperature_065_invalidFlag 0 "Invalid" 1 "Valid";
VAL_ 608 CellTemperature_066_invalidFlag 0 "Invalid" 1 "Valid";
VAL_ 608 CellTemperature_067_invalidFlag 0 "Invalid" 1 "Valid";
VAL_ 608 CellTemperature_068_invalidFlag 0 "Invalid" 1 "Valid";
VAL_ 608 CellTemperature_069_invalidFlag 0 "Invalid" 1 "Valid";
VAL_ 608 CellTemperature_070_invalidFlag 0 "Invalid" 1 "Valid";
VAL_ 608 CellTemperature_071_invalidFlag 0 "Invalid" 1 "Valid";
VAL_ 608 CellTemperature_072_invalidFlag 0 "Invalid" 1 "Valid";
VAL_ 608 CellTemperature_073_invalidFlag 0 "Invalid" 1 "Valid";
VAL_ 608 CellTemperature_074_invalidFlag 0 "Invalid" 1 "Valid";
VAL_ 608 CellTemperature_075_invalidFlag 0 "Invalid" 1 "Valid";
VAL_ 608 CellTemperature_076_invalidFlag 0 "Invalid" 1 "Valid";
VAL_ 608 CellTemperature_077_invalidFlag 0 "Invalid" 1 "Valid";
VAL_ 608 CellTemperature_078_invalidFlag 0 "Invalid" 1 "Valid";
VAL_ 608 CellTemperature_079_invalidFlag 0 "Invalid" 1 "Valid";
VAL_ 608 CellTemperature_080_invalidFlag 0 "Invalid" 1 "Valid";
VAL_ 608 CellTemperature_081_invalidFlag 0 "Invalid" 1 "Valid";
VAL_ 608 CellTemperature_082_invalidFlag 0 "Invalid" 1 "Valid";
VAL_ 608 CellTemperature_083_invalidFlag 0 "Invalid" 1 "Valid";
VAL_ 608 CellTemperature_084_invalidFlag 0 "Invalid" 1 "Valid";
VAL_ 608 CellTemperature_085_invalidFlag 0 "Invalid" 1 "Valid";
VAL_ 608 CellTemperature_086_invalidFlag 0 "Invalid" 1 "Valid";
VAL_ 608 CellTemperature_087_invalidFlag 0 "Invalid" 1 "Valid";
VAL_ 608 CellTemperature_088_invalidFlag 0 "Invalid" 1 "Valid";
VAL_ 608 CellTemperature_089_invalidFlag 0 "Invalid" 1 "Valid";
VAL_ 608 CellTemperature_090_invalidFlag 0 "Invalid" 1 "Valid";
VAL_ 608 CellTemperature_091_invalidFlag 0 "Invalid" 1 "Valid";
VAL_ 608 CellTemperature_092_invalidFlag 0 "Invalid" 1 "Valid";
VAL_ 608 CellTemperature_093_invalidFlag 0 "Invalid" 1 "Valid";
VAL_ 608 CellTemperature_094_invalidFlag 0 "Invalid" 1 "Valid";
VAL_ 608 CellTemperature_095_invalidFlag 0 "Invalid" 1 "Valid";
VAL_ 608 CellTemperature_096_invalidFlag 0 "Invalid" 1 "Valid";
VAL_ 608 CellTemperature_097_invalidFlag 0 "Invalid" 1 "Valid";
VAL_ 608 CellTemperature_098_invalidFlag 0 "Invalid" 1 "Valid";
VAL_ 608 CellTemperature_099_invalidFlag 0 "Invalid" 1 "Valid";
VAL_ 608 CellTemperature_100_invalidFlag 0 "Invalid" 1 "Valid";
VAL_ 608 CellTemperature_101_invalidFlag 0 "Invalid" 1 "Valid";
VAL_ 608 CellTemperature_102_invalidFlag 0 "Invalid" 1 "Valid";
VAL_ 608 CellTemperature_103_invalidFlag 0 "Invalid" 1 "Valid";
VAL_ 608 CellTemperature_104_invalidFlag 0 "Invalid" 1 "Valid";
VAL_ 608 CellTemperature_105_invalidFlag 0 "Invalid" 1 "Valid";
VAL_ 608 CellTemperature_106_invalidFlag 0 "Invalid" 1 "Valid";
VAL_ 608 CellTemperature_107_invalidFlag 0 "Invalid" 1 "Valid";
VAL_ 608 CellTemperature_108_invalidFlag 0 "Invalid" 1 "Valid";
VAL_ 608 CellTemperature_109_invalidFlag 0 "Invalid" 1 "Valid";
VAL_ 608 CellTemperature_110_invalidFlag 0 "Invalid" 1 "Valid";
VAL_ 608 CellTemperature_111_invalidFlag 0 "Invalid" 1 "Valid";
VAL_ 608 CellTemperature_112_invalidFlag 0 "Invalid" 1 "Valid";
VAL_ 608 CellTemperature_113_invalidFlag 0 "Invalid" 1 "Valid";
VAL_ 608 CellTemperature_114_invalidFlag 0 "Invalid" 1 "Valid";
VAL_ 608 CellTemperature_115_invalidFlag 0 "Invalid" 1 "Valid";
VAL_ 608 CellTemperature_116_invalidFlag 0 "Invalid" 1 "Valid";
VAL_ 608 CellTemperature_117_invalidFlag 0 "Invalid" 1 "Valid";
VAL_ 608 CellTemperature_118_invalidFlag 0 "Invalid" 1 "Valid";
VAL_ 608 CellTemperature_119_invalidFlag 0 "Invalid" 1 "Valid";
VAL_ 608 CellTemperature_120_invalidFlag 0 "Invalid" 1 "Valid";
VAL_ 608 CellTemperature_121_invalidFlag 0 "Invalid" 1 "Valid";
VAL_ 608 CellTemperature_122_invalidFlag 0 "Invalid" 1 "Valid";
VAL_ 608 CellTemperature_123_invalidFlag 0 "Invalid" 1 "Valid";
VAL_ 608 CellTemperature_124_invalidFlag 0 "Invalid" 1 "Valid";
VAL_ 608 CellTemperature_125_invalidFlag 0 "Invalid" 1 "Valid";
VAL_ 608 CellTemperature_126_invalidFlag 0 "Invalid" 1 "Valid";
VAL_ 608 CellTemperature_127_invalidFlag 0 "Invalid" 1 "Valid";
VAL_ 608 CellTemperature_128_invalidFlag 0 "Invalid" 1 "Valid";
VAL_ 608 CellTemperature_129_invalidFlag 0 "Invalid" 1 "Valid";
VAL_ 608 CellTemperature_130_invalidFlag 0 "Invalid" 1 "Valid";
VAL_ 608 CellTemperature_131_invalidFlag 0 "Invalid" 1 "Valid";
VAL_ 608 CellTemperature_132_invalidFlag 0 "Invalid" 1 "Valid";
VAL_ 608 CellTemperature_133_invalidFlag 0 "Invalid" 1 "Valid";
VAL_ 608 CellTemperature_134_invalidFlag 0 "Invalid" 1 "Valid";
VAL_ 608 CellTemperature_135_invalidFlag 0 "Invalid" 1 "Valid";
VAL_ 608 CellTemperature_136_invalidFlag 0 "Invalid" 1 "Valid";
VAL_ 608 CellTemperature_137_invalidFlag 0 "Invalid" 1 "Valid";
VAL_ 608 CellTemperature_138_invalidFlag 0 "Invalid" 1 "Valid";
VAL_ 608 CellTemperature_139_invalidFlag 0 "Invalid" 1 "Valid";
VAL_ 608 CellTemperature_140_invalidFlag 0 "Invalid" 1 "Valid";
VAL_ 608 CellTemperature_141_invalidFlag 0 "Invalid" 1 "Valid";
VAL_ 608 CellTemperature_142_invalidFlag 0 "Invalid" 1 "Valid";
VAL_ 608 CellTemperature_143_invalidFlag 0 "Invalid" 1 "Valid";
VAL_ 608 CellTemperature_144_invalidFlag 0 "Invalid" 1 "Valid";
VAL_ 608 CellTemperature_145_invalidFlag 0 "Invalid" 1 "Valid";
VAL_ 608 CellTemperature_146_invalidFlag 0 "Invalid" 1 "Valid";
VAL_ 608 CellTemperature_147_invalidFlag 0 "Invalid" 1 "Valid";
VAL_ 608 CellTemperature_148_invalidFlag 0 "Invalid" 1 "Valid";
VAL_ 608 CellTemperature_149_invalidFlag 0 "Invalid" 1 "Valid";
VAL_ 608 CellTemperature_150_invalidFlag 0 "Invalid" 1 "Valid";
VAL_ 608 CellTemperature_151_invalidFlag 0 "Invalid" 1 "Valid";
VAL_ 608 CellTemperature_152_invalidFlag 0 "Invalid" 1 "Valid";
VAL_ 608 CellTemperature_153_invalidFlag 0 "Invalid" 1 "Valid";
VAL_ 608 CellTemperature_154_invalidFlag 0 "Invalid" 1 "Valid";
VAL_ 608 CellTemperature_155_invalidFlag 0 "Invalid" 1 "Valid";
VAL_ 608 CellTemperature_156_invalidFlag 0 "Invalid" 1 "Valid";
VAL_ 608 CellTemperature_157_invalidFlag 0 "Invalid" 1 "Valid";
VAL_ 608 CellTemperature_158_invalidFlag 0 "Invalid" 1 "Valid";
VAL_ 608 CellTemperature_159_invalidFlag 0 "Invalid" 1 "Valid";
VAL_ 608 CellTemperature_160_invalidFlag 0 "Invalid" 1 "Valid";
VAL_ 608 CellTemperature_161_invalidFlag 0 "Invalid" 1 "Valid";
VAL_ 608 CellTemperature_162_invalidFlag 0 "Invalid" 1 "Valid";
VAL_ 608 CellTemperature_163_invalidFlag 0 "Invalid" 1 "Valid";
VAL_ 608 CellTemperature_164_invalidFlag 0 "Invalid" 1 "Valid";
VAL_ 608 CellTemperature_165_invalidFlag 0 "Invalid" 1 "Valid";
VAL_ 608 CellTemperature_166_invalidFlag 0 "Invalid" 1 "Valid";
VAL_ 608 CellTemperature_167_invalidFlag 0 "Invalid" 1 "Valid";
VAL_ 608 CellTemperature_168_invalidFlag 0 "Invalid" 1 "Valid";
VAL_ 608 CellTemperature_169_invalidFlag 0 "Invalid" 1 "Valid";
VAL_ 608 CellTemperature_170_invalidFlag 0 "Invalid" 1 "Valid";
VAL_ 608 CellTemperature_171_invalidFlag 0 "Invalid" 1 "Valid";
VAL_ 608 CellTemperature_172_invalidFlag 0 "Invalid" 1 "Valid";
VAL_ 608 CellTemperature_173_invalidFlag 0 "Invalid" 1 "Valid";
VAL_ 608 CellTemperature_174_invalidFlag 0 "Invalid" 1 "Valid";
VAL_ 608 CellTemperature_175_invalidFlag 0 "Invalid" 1 "Valid";
VAL_ 608 CellTemperature_176_invalidFlag 0 "Invalid" 1 "Valid";
VAL_ 608 CellTemperature_177_invalidFlag 0 "Invalid" 1 "Valid";
VAL_ 608 CellTemperature_178_invalidFlag 0 "Invalid" 1 "Valid";
VAL_ 608 CellTemperature_179_invalidFlag 0 "Invalid" 1 "Valid";
VAL_ 592 CellVoltage_000_invalidFlag 0 "Invalid" 1 "Valid";
VAL_ 592 CellVoltage_001_invalidFlag 0 "Invalid" 1 "Valid";
VAL_ 592 CellVoltage_002_invalidFlag 0 "Invalid" 1 "Valid";
VAL_ 592 CellVoltage_003_invalidFlag 0 "Invalid" 1 "Valid";
VAL_ 592 CellVoltage_004_invalidFlag 0 "Invalid" 1 "Valid";
VAL_ 592 CellVoltage_005_invalidFlag 0 "Invalid" 1 "Valid";
VAL_ 592 CellVoltage_006_invalidFlag 0 "Invalid" 1 "Valid";
VAL_ 592 CellVoltage_007_invalidFlag 0 "Invalid" 1 "Valid";
VAL_ 592 CellVoltage_008_invalidFlag 0 "Invalid" 1 "Valid";
VAL_ 592 CellVoltage_009_invalidFlag 0 "Invalid" 1 "Valid";
VAL_ 592 CellVoltage_010_invalidFlag 0 "Invalid" 1 "Valid";
VAL_ 592 CellVoltage_011_invalidFlag 0 "Invalid" 1 "Valid";
VAL_ 592 CellVoltage_012_invalidFlag 0 "Invalid" 1 "Valid";
VAL_ 592 CellVoltage_013_invalidFlag 0 "Invalid" 1 "Valid";
VAL_ 592 CellVoltage_014_invalidFlag 0 "Invalid" 1 "Valid";
VAL_ 592 CellVoltage_015_invalidFlag 0 "Invalid" 1 "Valid";
VAL_ 592 CellVoltage_016_invalidFlag 0 "Invalid" 1 "Valid";
VAL_ 592 CellVoltage_017_invalidFlag 0 "Invalid" 1 "Valid";
VAL_ 592 CellVoltage_018_invalidFlag 0 "Invalid" 1 "Valid";
VAL_ 592 CellVoltage_019_invalidFlag 0 "Invalid" 1 "Valid";
VAL_ 592 CellVoltage_020_invalidFlag 0 "Invalid" 1 "Valid";
VAL_ 592 CellVoltage_021_invalidFlag 0 "Invalid" 1 "Valid";
VAL_ 592 CellVoltage_022_invalidFlag 0 "Invalid" 1 "Valid";
VAL_ 592 CellVoltage_023_invalidFlag 0 "Invalid" 1 "Valid";
VAL_ 592 CellVoltage_024_invalidFlag 0 "Invalid" 1 "Valid";
VAL_ 592 CellVoltage_025_invalidFlag 0 "Invalid" 1 "Valid";
VAL_ 592 CellVoltage_026_invalidFlag 0 "Invalid" 1 "Valid";
VAL_ 592 CellVoltage_027_invalidFlag 0 "Invalid" 1 "Valid";
VAL_ 592 CellVoltage_028_invalidFlag 0 "Invalid" 1 "Valid";
VAL_ 592 CellVoltage_029_invalidFlag 0 "Invalid" 1 "Valid";
VAL_ 592 CellVoltage_030_invalidFlag 0 "Invalid" 1 "Valid";
VAL_ 592 CellVoltage_031_invalidFlag 0 "Invalid" 1 "Valid";
VAL_ 592 CellVoltage_032_invalidFlag 0 "Invalid" 1 "Valid";
VAL_ 592 CellVoltage_033_invalidFlag 0 "Invalid" 1 "Valid";
VAL_ 592 CellVoltage_034_invalidFlag 0 "Invalid" 1 "Valid";
VAL_ 592 CellVoltage_035_invalidFlag 0 "Invalid" 1 "Valid";
VAL_ 592 CellVoltage_036_invalidFlag 0 "Invalid" 1 "Valid";
VAL_ 592 CellVoltage_037_invalidFlag 0 "Invalid" 1 "Valid";
VAL_ 592 CellVoltage_038_invalidFlag 0 "Invalid" 1 "Valid";
VAL_ 592 CellVoltage_039_invalidFlag 0 "Invalid" 1 "Valid";
VAL_ 592 CellVoltage_040_invalidFlag 0 "Invalid" 1 "Valid";
VAL_ 592 CellVoltage_041_invalidFlag 0 "Invalid" 1 "Valid";
VAL_ 592 CellVoltage_042_invalidFlag 0 "Invalid" 1 "Valid";
VAL_ 592 CellVoltage_043_invalidFlag 0 "Invalid" 1 "Valid";
VAL_ 592 CellVoltage_044_invalidFlag 0 "Invalid" 1 "Valid";
VAL_ 592 CellVoltage_045_invalidFlag 0 "Invalid" 1 "Valid";
VAL_ 592 CellVoltage_046_invalidFlag 0 "Invalid" 1 "Valid";
VAL_ 592 CellVoltage_047_invalidFlag 0 "Invalid" 1 "Valid";
VAL_ 592 CellVoltage_048_invalidFlag 0 "Invalid" 1 "Valid";
VAL_ 592 CellVoltage_049_invalidFlag 0 "Invalid" 1 "Valid";
VAL_ 592 CellVoltage_050_invalidFlag 0 "Invalid" 1 "Valid";
VAL_ 592 CellVoltage_051_invalidFlag 0 "Invalid" 1 "Valid";
VAL_ 592 CellVoltage_052_invalidFlag 0 "Invalid" 1 "Valid";
VAL_ 592 CellVoltage_053_invalidFlag 0 "Invalid" 1 "Valid";
VAL_ 592 CellVoltage_054_invalidFlag 0 "Invalid" 1 "Valid";
VAL_ 592 CellVoltage_055_invalidFlag 0 "Invalid" 1 "Valid";
VAL_ 592 CellVoltage_056_invalidFlag 0 "Invalid" 1 "Valid";
VAL_ 592 CellVoltage_057_invalidFlag 0 "Invalid" 1 "Valid";
VAL_ 592 CellVoltage_058_invalidFlag 0 "Invalid" 1 "Valid";
VAL_ 592 CellVoltage_059_invalidFlag 0 "Invalid" 1 "Valid";
VAL_ 592 CellVoltage_060_invalidFlag 0 "Invalid" 1 "Valid";
VAL_ 592 CellVoltage_061_invalidFlag 0 "Invalid" 1 "Valid";
VAL_ 592 CellVoltage_062_invalidFlag 0 "Invalid" 1 "Valid";
VAL_ 592 CellVoltage_063_invalidFlag 0 "Invalid" 1 "Valid";
VAL_ 592 CellVoltage_064_invalidFlag 0 "Invalid" 1 "Valid";
VAL_ 592 CellVoltage_065_invalidFlag 0 "Invalid" 1 "Valid";
VAL_ 592 CellVoltage_066_invalidFlag 0 "Invalid" 1 "Valid";
VAL_ 592 CellVoltage_067_invalidFlag 0 "Invalid" 1 "Valid";
VAL_ 592 CellVoltage_068_invalidFlag 0 "Invalid" 1 "Valid";
VAL_ 592 CellVoltage_069_invalidFlag 0 "Invalid" 1 "Valid";
VAL_ 592 CellVoltage_070_invalidFlag 0 "Invalid" 1 "Valid";
VAL_ 592 CellVoltage_071_invalidFlag 0 "Invalid" 1 "Valid";
VAL_ 592 CellVoltage_072_invalidFlag 0 "Invalid" 1 "Valid";
VAL_ 592 CellVoltage_073_invalidFlag 0 "Invalid" 1 "Valid";
VAL_ 592 CellVoltage_074_invalidFlag 0 "Invalid" 1 "Valid";
VAL_ 592 CellVoltage_075_invalidFlag 0 "Invalid" 1 "Valid";
VAL_ 592 CellVoltage_076_invalidFlag 0 "Invalid" 1 "Valid";
VAL_ 592 CellVoltage_077_invalidFlag 0 "Invalid" 1 "Valid";
VAL_ 592 CellVoltage_078_invalidFlag 0 "Invalid" 1 "Valid";
VAL_ 592 CellVoltage_079_invalidFlag 0 "Invalid" 1 "Valid";
VAL_ 592 CellVoltage_080_invalidFlag 0 "Invalid" 1 "Valid";
VAL_ 592 CellVoltage_081_invalidFlag 0 "Invalid" 1 "Valid";
VAL_ 592 CellVoltage_082_invalidFlag 0 "Invalid" 1 "Valid";
VAL_ 592 CellVoltage_083_invalidFlag 0 "Invalid" 1 "Valid";
VAL_ 592 CellVoltage_084_invalidFlag 0 "Invalid" 1 "Valid";
VAL_ 592 CellVoltage_085_invalidFlag 0 "Invalid" 1 "Valid";
VAL_ 592 CellVoltage_086_invalidFlag 0 "Invalid" 1 "Valid";
VAL_ 592 CellVoltage_087_invalidFlag 0 "Invalid" 1 "Valid";
VAL_ 592 CellVoltage_088_invalidFlag 0 "Invalid" 1 "Valid";
VAL_ 592 CellVoltage_089_invalidFlag 0 "Invalid" 1 "Valid";
VAL_ 592 CellVoltage_090_invalidFlag 0 "Invalid" 1 "Valid";
VAL_ 592 CellVoltage_091_invalidFlag 0 "Invalid" 1 "Valid";
VAL_ 592 CellVoltage_092_invalidFlag 0 "Invalid" 1 "Valid";
VAL_ 592 CellVoltage_093_invalidFlag 0 "Invalid" 1 "Valid";
VAL_ 592 CellVoltage_094_invalidFlag 0 "Invalid" 1 "Valid";
VAL_ 592 CellVoltage_095_invalidFlag 0 "Invalid" 1 "Valid";
VAL_ 592 CellVoltage_096_invalidFlag 0 "Invalid" 1 "Valid";
VAL_ 592 CellVoltage_097_invalidFlag 0 "Invalid" 1 "Valid";
VAL_ 592 CellVoltage_098_invalidFlag 0 "Invalid" 1 "Valid";
VAL_ 592 CellVoltage_099_invalidFlag 0 "Invalid" 1 "Valid";
VAL_ 592 CellVoltage_100_invalidFlag 0 "Invalid" 1 "Valid";
VAL_ 592 CellVoltage_101_invalidFlag 0 "Invalid" 1 "Valid";
VAL_ 592 CellVoltage_102_invalidFlag 0 "Invalid" 1 "Valid";
VAL_ 592 CellVoltage_103_invalidFlag 0 "Invalid" 1 "Valid";
VAL_ 592 CellVoltage_104_invalidFlag 0 "Invalid" 1 "Valid";
VAL_ 592 CellVoltage_105_invalidFlag 0 "Invalid" 1 "Valid";
VAL_ 592 CellVoltage_106_invalidFlag 0 "Invalid" 1 "Valid";
VAL_ 592 CellVoltage_107_invalidFlag 0 "Invalid" 1 "Valid";
VAL_ 592 CellVoltage_108_invalidFlag 0 "Invalid" 1 "Valid";
VAL_ 592 CellVoltage_109_invalidFlag 0 "Invalid" 1 "Valid";
VAL_ 592 CellVoltage_110_invalidFlag 0 "Invalid" 1 "Valid";
VAL_ 592 CellVoltage_111_invalidFlag 0 "Invalid" 1 "Valid";
VAL_ 592 CellVoltage_112_invalidFlag 0 "Invalid" 1 "Valid";
VAL_ 592 CellVoltage_113_invalidFlag 0 "Invalid" 1 "Valid";
VAL_ 592 CellVoltage_114_invalidFlag 0 "Invalid" 1 "Valid";
VAL_ 592 CellVoltage_115_invalidFlag 0 "Invalid" 1 "Valid";
VAL_ 592 CellVoltage_116_invalidFlag 0 "Invalid" 1 "Valid";
VAL_ 592 CellVoltage_117_invalidFlag 0 "Invalid" 1 "Valid";
VAL_ 592 CellVoltage_118_invalidFlag 0 "Invalid" 1 "Valid";
VAL_ 592 CellVoltage_119_invalidFlag 0 "Invalid" 1 "Valid";
VAL_ 592 CellVoltage_120_invalidFlag 0 "Invalid" 1 "Valid";
VAL_ 592 CellVoltage_121_invalidFlag 0 "Invalid" 1 "Valid";
VAL_ 592 CellVoltage_122_invalidFlag 0 "Invalid" 1 "Valid";
VAL_ 592 CellVoltage_123_invalidFlag 0 "Invalid" 1 "Valid";
VAL_ 592 CellVoltage_124_invalidFlag 0 "Invalid" 1 "Valid";
VAL_ 592 CellVoltage_125_invalidFlag 0 "Invalid" 1 "Valid";
VAL_ 592 CellVoltage_126_invalidFlag 0 "Invalid" 1 "Valid";
VAL_ 592 CellVoltage_127_invalidFlag 0 "Invalid" 1 "Valid";
VAL_ 592 CellVoltage_128_invalidFlag 0 "Invalid" 1 "Valid";
VAL_ 592 CellVoltage_129_invalidFlag 0 "Invalid" 1 "Valid";
VAL_ 592 CellVoltage_130_invalidFlag 0 "Invalid" 1 "Valid";
VAL_ 592 CellVoltage_131_invalidFlag 0 "Invalid" 1 "Valid";
VAL_ 592 CellVoltage_132_invalidFlag 0 "Invalid" 1 "Valid";
VAL_ 592 CellVoltage_133_invalidFlag 0 "Invalid" 1 "Valid";
VAL_ 592 CellVoltage_134_invalidFlag 0 "Invalid" 1 "Valid";
VAL_ 592 CellVoltage_135_invalidFlag 0 "Invalid" 1 "Valid";
VAL_ 592 CellVoltage_136_invalidFlag 0 "Invalid" 1 "Valid";
VAL_ 592 CellVoltage_137_invalidFlag 0 "Invalid" 1 "Valid";
VAL_ 592 CellVoltage_138_invalidFlag 0 "Invalid" 1 "Valid";
VAL_ 592 CellVoltage_139_invalidFlag 0 "Invalid" 1 "Valid";
VAL_ 592 CellVoltage_140_invalidFlag 0 "Invalid" 1 "Valid";
VAL_ 592 CellVoltage_141_invalidFlag 0 "Invalid" 1 "Valid";
VAL_ 592 CellVoltage_142_invalidFlag 0 "Invalid" 1 "Valid";
VAL_ 592 CellVoltage_143_invalidFlag 0 "Invalid" 1 "Valid";
VAL_ 592 CellVoltage_144_invalidFlag 0 "Invalid" 1 "Valid";
VAL_ 592 CellVoltage_145_invalidFlag 0 "Invalid" 1 "Valid";
VAL_ 592 CellVoltage_146_invalidFlag 0 "Invalid" 1 "Valid";
VAL_ 592 CellVoltage_147_invalidFlag 0 "Invalid" 1 "Valid";
VAL_ 592 CellVoltage_148_invalidFlag 0 "Invalid" 1 "Valid";
VAL_ 592 CellVoltage_149_invalidFlag 0 "Invalid" 1 "Valid";
VAL_ 592 CellVoltage_150_invalidFlag 0 "Invalid" 1 "Valid";
VAL_ 592 CellVoltage_151_invalidFlag 0 "Invalid" 1 "Valid";
VAL_ 592 CellVoltage_152_invalidFlag 0 "Invalid" 1 "Valid";
VAL_ 592 CellVoltage_153_invalidFlag 0 "Invalid" 1 "Valid";
VAL_ 592 CellVoltage_154_invalidFlag 0 "Invalid" 1 "Valid";
VAL_ 592 CellVoltage_155_invalidFlag 0 "Invalid" 1 "Valid";
VAL_ 592 CellVoltage_156_invalidFlag 0 "Invalid" 1 "Valid";
VAL_ 592 CellVoltage_157_invalidFlag 0 "Invalid" 1 "Valid";
VAL_ 592 CellVoltage_158_invalidFlag 0 "Invalid" 1 "Valid";
VAL_ 592 CellVoltage_159_invalidFlag 0 "Invalid" 1 "Valid";
VAL_ 592 CellVoltage_160_invalidFlag 0 "Invalid" 1 "Valid";
VAL_ 592 CellVoltage_161_invalidFlag 0 "Invalid" 1 "Valid";
VAL_ 592 CellVoltage_162_invalidFlag 0 "Invalid" 1 "Valid";
VAL_ 592 CellVoltage_163_invalidFlag 0 "Invalid" 1 "Valid";
VAL_ 592 CellVoltage_164_invalidFlag 0 "Invalid" 1 "Valid";
VAL_ 592 CellVoltage_165_invalidFlag 0 "Invalid" 1 "Valid";
VAL_ 592 CellVoltage_166_invalidFlag 0 "Invalid" 1 "Valid";
VAL_ 592 CellVoltage_167_invalidFlag 0 "Invalid" 1 "Valid";
VAL_ 592 CellVoltage_168_invalidFlag 0 "Invalid" 1 "Valid";
VAL_ 592 CellVoltage_169_invalidFlag 0 "Invalid" 1 "Valid";
VAL_ 592 CellVoltage_170_invalidFlag 0 "Invalid" 1 "Valid";
VAL_ 592 CellVoltage_171_invalidFlag 0 "Invalid" 1 "Valid";
VAL_ 592 CellVoltage_172_invalidFlag 0 "Invalid" 1 "Valid";
VAL_ 592 CellVoltage_173_invalidFlag 0 "Invalid" 1 "Valid";
VAL_ 592 CellVoltage_174_invalidFlag 0 "Invalid" 1 "Valid";
VAL_ 592 CellVoltage_175_invalidFlag 0 "Invalid" 1 "Valid";
VAL_ 592 CellVoltage_176_invalidFlag 0 "Invalid" 1 "Valid";
VAL_ 592 CellVoltage_177_invalidFlag 0 "Invalid" 1 "Valid";
VAL_ 592 CellVoltage_178_invalidFlag 0 "Invalid" 1 "Valid";
VAL_ 592 CellVoltage_179_invalidFlag 0 "Invalid" 1 "Valid";
VAL_ 592 CellVoltage_180_invalidFlag 0 "Invalid" 1 "Valid";
VAL_ 592 CellVoltage_181_invalidFlag 0 "Invalid" 1 "Valid";
VAL_ 592 CellVoltage_182_invalidFlag 0 "Invalid" 1 "Valid";
VAL_ 592 CellVoltage_183_invalidFlag 0 "Invalid" 1 "Valid";
VAL_ 592 CellVoltage_184_invalidFlag 0 "Invalid" 1 "Valid";
VAL_ 592 CellVoltage_185_invalidFlag 0 "Invalid" 1 "Valid";
VAL_ 592 CellVoltage_186_invalidFlag 0 "Invalid" 1 "Valid";
VAL_ 592 CellVoltage_187_invalidFlag 0 "Invalid" 1 "Valid";
VAL_ 592 CellVoltage_188_invalidFlag 0 "Invalid" 1 "Valid";
VAL_ 592 CellVoltage_189_invalidFlag 0 "Invalid" 1 "Valid";
VAL_ 592 CellVoltage_190_invalidFlag 0 "Invalid" 1 "Valid";
VAL_ 592 CellVoltage_191_invalidFlag 0 "Invalid" 1 "Valid";
VAL_ 592 CellVoltage_192_invalidFlag 0 "Invalid" 1 "Valid";
VAL_ 592 CellVoltage_193_invalidFlag 0 "Invalid" 1 "Valid";
VAL_ 592 CellVoltage_194_invalidFlag 0 "Invalid" 1 "Valid";
VAL_ 592 CellVoltage_195_invalidFlag 0 "Invalid" 1 "Valid";
VAL_ 592 CellVoltage_196_invalidFlag 0 "Invalid" 1 "Valid";
VAL_ 592 CellVoltage_197_invalidFlag 0 "Invalid" 1 "Valid";
VAL_ 592 CellVoltage_198_invalidFlag 0 "Invalid" 1 "Valid";
VAL_ 592 CellVoltage_199_invalidFlag 0 "Invalid" 1 "Valid";
VAL_ 592 CellVoltage_200_invalidFlag 0 "Invalid" 1 "Valid";
VAL_ 592 CellVoltage_201_invalidFlag 0 "Invalid" 1 "Valid";
VAL_ 592 CellVoltage_202_invalidFlag 0 "Invalid" 1 "Valid";
VAL_ 592 CellVoltage_203_invalidFlag 0 "Invalid" 1 "Valid";
VAL_ 592 CellVoltage_204_invalidFlag 0 "Invalid" 1 "Valid";
VAL_ 592 CellVoltage_205_invalidFlag 0 "Invalid" 1 "Valid";
VAL_ 592 CellVoltage_206_invalidFlag 0 "Invalid" 1 "Valid";
VAL_ 592 CellVoltage_207_invalidFlag 0 "Invalid" 1 "Valid";
VAL_ 592 CellVoltage_208_invalidFlag 0 "Invalid" 1 "Valid";
VAL_ 592 CellVoltage_209_invalidFlag 0 "Invalid" 1 "Valid";
VAL_ 592 CellVoltage_210_invalidFlag 0 "Invalid" 1 "Valid";
VAL_ 592 CellVoltage_211_invalidFlag 0 "Invalid" 1 "Valid";
VAL_ 592 CellVoltage_212_invalidFlag 0 "Invalid" 1 "Valid";
VAL_ 592 CellVoltage_213_invalidFlag 0 "Invalid" 1 "Valid";
VAL_ 592 CellVoltage_214_invalidFlag 0 "Invalid" 1 "Valid";
VAL_ 592 CellVoltage_215_invalidFlag 0 "Invalid" 1 "Valid";
VAL_ 768 SetWeekday 1 "Monday" 2 "Tuesday" 3 "Wednesday" 4 "Thursday" 5 "Friday" 6 "Saturday" 0 "Sunday";
VAL_ 768 SetMonth 1 "January" 2 "February" 3 "March" 4 "April" 5 "May" 6 "June" 7 "July" 8 "August" 9 "September" 10 "October" 11 "November" 12 "December";
VAL_ 768 TriggerSoftwareReset 0 "NO_SOFTWARE_RESET" 1 "SOFTWARE_RESET";
VAL_ 768 InitializeFram 0 "Uninitialized" 1 "Initialized";
VAL_ 768 FramCalibrationChannel 0 "FRAM_CHANNEL_0" 1 "FRAM_CHANNEL_1" 2 "FRAM_CHANNEL_2" 3 "FRAM_CHANNEL_3" 4 "FRAM_CHANNEL_4" 5 "FRAM_CHANNEL_5" 6 "FRAM_CHANNEL_6" 7 "FRAM_CHANNEL_7" 8 "FRAM_CHANNEL_8" 9 "FRAM_CHANNEL_9";
VAL_ 768 CalibrationChannel9 0 "FRAM_CHANNEL_0" 1 "FRAM_CHANNEL_1" 2 "FRAM_CHANNEL_2" 3 "FRAM_CHANNEL_3" 4 "FRAM_CHANNEL_4" 5 "FRAM_CHANNEL_5" 6 "FRAM_CHANNEL_6" 7 "FRAM_CHANNEL_7" 8 "FRAM_CHANNEL_8" 9 "FRAM_CHANNEL_9";
VAL_ 768 CalibrationChannel8 0 "FRAM_CHANNEL_0" 1 "FRAM_CHANNEL_1" 2 "FRAM_CHANNEL_2" 3 "FRAM_CHANNEL_3" 4 "FRAM_CHANNEL_4" 5 "FRAM_CHANNEL_5" 6 "FRAM_CHANNEL_6" 7 "FRAM_CHANNEL_7" 8 "FRAM_CHANNEL_8" 9 "FRAM_CHANNEL_9";
VAL_ 768 CalibrationChannel10 0 "FRAM_CHANNEL_0" 1 "FRAM_CHANNEL_1" 2 "FRAM_CHANNEL_2" 3 "FRAM_CHANNEL_3" 4 "FRAM_CHANNEL_4" 5 "FRAM_CHANNEL_5" 6 "FRAM_CHANNEL_6" 7 "FRAM_CHANNEL_7" 8 "FRAM_CHANNEL_8" 9 "FRAM_CHANNEL_9";
VAL_ 771 SOC_algorithm 0 "None" 1 "Debug" 2 "Counting" 3 "Lookup Table";
VAL_ 771 SOE_algorithm 0 "None" 1 "Debug" 2 "Counting";
VAL_ 771 SOF_algorithm 0 "Trapezoid";
VAL_ 771 SOH_algorithm 0 "None" 1 "Debug";
VAL_ 771 Balancing_strategy 0 "none" 1 "voltage" 2 "history";
VAL_ 771 IMD 0 "none" 1 "Bender_iso165c" 2 "Bender_ir155";
VAL_ 771 Rtos 0 "freertos" 1 "safertos";
VAL_ 771 AFE 0 "Debug default" 1 "Debug CAN" 256 "LTC 6804-1" 257 "LTC 6806" 258 "LTC 6811-1" 259 "LTC 6812-1" 260 "LTC 6813-1" 512 "NXP MC33775A" 768 "MAXIM MAX17852" 1024 "ADI ADES1830" 1281 "TI Dummy";
VAL_ 771 TemperatureSensor 0 "Fak00" 1 "Epc00" 2 "Epc01" 3 "Mur00" 4 "Sem00" 5 "Vis00" 6 "Vis01" 7 "Vis02" 8 "Tdk00" 9 "Tdk01";
VAL_ 771 TemperatureSensorMethod 0 "polynomial" 1 "lookup-table";
VAL_ 769 DirtyFlag 0 "No" 1 "Yes";
VAL_ 769 ReleaseDistanceOverflow 0 "No" 1 "Yes";
VAL_ 769 UnderVersionControl 0 "No" 1 "Yes";
VAL_ 769 GetMonth 1 "January" 2 "February" 3 "March" 4 "April" 5 "May" 6 "June" 7 "July" 8 "August" 9 "September" 10 "October" 11 "November" 12 "December";
VAL_ 769 GetWeekday 1 "Monday" 2 "Tuesday" 3 "Wednesday" 4 "Thursday" 5 "Friday" 6 "Saturday" 0 "Sunday";
VAL_ 769 RtcRequestFlag 0 "No Request" 1 "Valid Request" 2 "Invalid Request";
VAL_ 769 GetBootMonth 1 "January" 2 "February" 3 "March" 4 "April" 5 "May" 6 "June" 7 "July" 8 "August" 9 "September" 10 "October" 11 "November" 12 "December";
VAL_ 769 GetbootWeekday 1 "Monday" 2 "Tuesday" 3 "Wednesday" 4 "Thursday" 5 "Friday" 6 "Saturday" 0 "Sunday";
VAL_ 769 CalibrationChannel8 0 "FRAM_CHANNEL_0" 1 "FRAM_CHANNEL_1" 2 "FRAM_CHANNEL_2" 3 "FRAM_CHANNEL_3" 4 "FRAM_CHANNEL_4" 5 "FRAM_CHANNEL_5" 6 "FRAM_CHANNEL_6" 7 "FRAM_CHANNEL_7" 8 "FRAM_CHANNEL_8" 9 "FRAM_CHANNEL_9";
VAL_ 769 CalibrationChannel9 0 "FRAM_CHANNEL_0" 1 "FRAM_CHANNEL_1" 2 "FRAM_CHANNEL_2" 3 "FRAM_CHANNEL_3" 4 "FRAM_CHANNEL_4" 5 "FRAM_CHANNEL_5" 6 "FRAM_CHANNEL_6" 7 "FRAM_CHANNEL_7" 8 "FRAM_CHANNEL_8" 9 "FRAM_CHANNEL_9";
VAL_ 769 CalibrationChannel10 0 "FRAM_CHANNEL_0" 1 "FRAM_CHANNEL_1" 2 "FRAM_CHANNEL_2" 3 "FRAM_CHANNEL_3" 4 "FRAM_CHANNEL_4" 5 "FRAM_CHANNEL_5" 6 "FRAM_CHANNEL_6" 7 "FRAM_CHANNEL_7" 8 "FRAM_CHANNEL_8" 9 "FRAM_CHANNEL_9";
VAL_ 576 IsStringConnected 0 "No" 1 "Yes";
VAL_ 576 IsBalancingActive 0 "No" 1 "Yes";
VAL_ 576 OvertemperatureChargeMslError 0 "No Error" 1 "Error";
VAL_ 576 UndertemperatureChargeMslError 0 "No Error" 1 "Error";
VAL_ 576 OvertemperatureDischargeMslError 0 "No Error" 1 "Error";
VAL_ 576 UndertemperatureDischargeMslErro 0 "No Error" 1 "Error";
VAL_ 576 CellOvercurrentChargeMslError 0 "No Error" 1 "Error";
VAL_ 576 CellOvercurrentDischargeMslError 0 "No Error" 1 "Error";
VAL_ 576 OvervoltageMslError 0 "No Error" 1 "Error";
VAL_ 576 UndervoltageMslError 0 "No Error" 1 "Error";
VAL_ 576 DeepDischargeError 0 "No Error" 1 "Error";
VAL_ 576 StringCurrentMeasurementError 0 "No Error" 1 "Error";
VAL_ 576 PositiveContactorError 0 "No Error" 1 "Error";
VAL_ 576 OpenWireError 0 "No Error" 1 "Error";
VAL_ 576 CellVoltagePlausibilityError 0 "No Error" 1 "Error";
VAL_ 576 CellTemperaturePlausibilityError 0 "No Error" 1 "Error";
VAL_ 576 StringVoltagePlausibilityError 0 "No Error" 1 "Error";
VAL_ 576 SlaveHardwareError 0 "No Error" 1 "Error";
VAL_ 576 DaisyChainBaseCommunicationError 0 "No Error" 1 "Error";
VAL_ 576 DaisyChainBaseCrcError 0 "No Error" 1 "Error";
VAL_ 576 DaisyChainBaseVoltMeasOorError 0 "No Error" 1 "Error";
VAL_ 576 DaisyChainBaseTempMeasOorError 0 "No Error" 1 "Error";
VAL_ 576 CoulombCountingMeasurementError 0 "No Error" 1 "Error";
VAL_ 576 EnergyCountingMeasurementError 0 "No Error" 1 "Error";
VAL_ 576 VoltageSpreadPlausibilityError 0 "No Error" 1 "Error";
VAL_ 576 TemperatureSpreadPlausibilityErr 0 "No Error" 1 "Error";
VAL_ 576 IsStringFuseBlown 0 "No" 1 "Yes";
VAL_ 576 OvervoltageMolWarning 0 "No Warning" 1 "Warning";
VAL_ 576 UndervoltageMolWarning 0 "No Warning" 1 "Warning";
VAL_ 576 OvertemperatureChargeMolWarning 0 "No Warning" 1 "Warning";
VAL_ 576 OvertemperatureDischargeMolWarni 0 "No Warning" 1 "Warning";
VAL_ 576 UndertemperatureChargeMolWarning 0 "No Warning" 1 "Warning";
VAL_ 576 UndertemperatureDischargeMolWarn 0 "No Warning" 1 "Warning";
VAL_ 576 CellOvercurrentChargeMolWarning 0 "No Warning" 1 "Warning";
VAL_ 576 CellOvercurrentDischargeMolWarni 0 "No Warning" 1 "Warning";
VAL_ 576 OvertemperatureChargeRslWarning 0 "No Warning" 1 "Warning";
VAL_ 576 UndertemperatureChargeRslWarning 0 "No Warning" 1 "Warning";
VAL_ 576 OvertemperatureDischargeRslWarni 0 "No Warning" 1 "Warning";
VAL_ 576 UndertemperatureDischargeRslWarn 0 "No Warning" 1 "Warning";
VAL_ 576 CellOvercurrentChargeRslWarning 0 "No Warning" 1 "Warning";
VAL_ 576 CellOvercurrentDischargeRslWarni 0 "No Warning" 1 "Warning";
VAL_ 576 OvervoltageRslWarning 0 "No Warning" 1 "Warning";
VAL_ 576 UndervoltageRslWarning 0 "No Warning" 1 "Warning";
VAL_ 576 NegativeContactorError 0 "No Error" 1 "Error";
VAL_ 576 StringVoltageMeasurementError 0 "No Error" 1 "Error";
VAL_ 576 FusedStringVoltageMeasurementErr 0 "No Error" 1 "Error";
VAL_ 576 PackVoltageMeasurementError 0 "No Error" 1 "Error";
VAL_ 576 StringOvercurrentError 0 "No Error" 1 "Error";
VAL_ 537 State 0 "SYS_FSM_STATE_DUMMY" 1 "SYS_FSM_STATE_HAS_NEVER_RUN" 2 "SYS_FSM_STATE_UNINITIALIZED" 3 "SYS_FSM_STATE_INITIALIZATION" 4 "SYS_FSM_STATE_PRE_RUNNING" 5 "SYS_FSM_STATE_RUNNING" 6 "SYS_FSM_STATE_ERROR";
VAL_ 537 Substate 0 "SYS_FSM_SUBSTATE_DUMMY" 1 "SYS_FSM_SUBSTATE_ENTRY" 2 "SYS_FSM_CHECK_DEEP_DISCHARGE" 3 "SYS_FSM_SUBSTATE_START_INITIALIZATION_SBC" 4 "SYS_FSM_SUBSTATE_INITIALIZE_INTERLOCK" 5 "SYS_FSM_SUBSTATE_WAIT_INITIALIZATION_SBC" 6 "SYS_FSM_SUBSTATE_INITIALIZATION_CAN" 7 "SYS_FSM_SUBSTATE_INITIALIZATION_RTC" 8 "SYS_FSM_SUBSTATE_START_UP_BIST" 9 "SYS_FSM_SUBSTATE_SEND_BOOT_MESSAGE" 10 "SYS_FSM_SUBSTATE_START_INITIALIZATION_BAL" 11 "SYS_FSM_SUBSTATE_WAIT_INITIALIZATION_BAL" 12 "SYS_FSM_SUBSTATE_WAIT_INITIALIZATION_BAL_GLOBAL_ENABLE" 13 "SYS_FSM_SUBSTATE_START_FIRST_MEASUREMENT_CYCLE" 14 "SYS_FSM_SUBSTATE_WAIT_FIRST_MEASUREMENT_CYCLE" 15 "SYS_FSM_SUBSTATE_START_CURRENT_SENSOR_PRESENCE_CHECK" 16 "SYS_FSM_SUBSTATE_WAIT_CURRENT_SENSOR_PRESENCE_CHECK" 17 "SYS_FSM_SUBSTATE_INITIALIZATION_MISC" 18 "SYS_FSM_SUBSTATE_INITIALIZATION_IMD" 19 "SYS_FSM_SUBSTATE_START_INITIALIZATION_BMS" 20 "SYS_FSM_SUBSTATE_WAIT_INITIALIZATION_BMS" 21 "SYS_FSM_SUBSTATE_SBC_INITIALIZATION_ERROR" 22 "SYS_FSM_SUBSTATE_BAL_INITIALIZATION_ERROR" 23 "SYS_FSM_SUBSTATE_BAL_GLOBAL_INITIALIZATION_ERROR"
24 "SYS_FSM_SUBSTATE_FIRST_MEAS_INITIALIZATION_ERROR" 25 "SYS_FSM_SUBSTATE_CURRENT_SENSOR_PRESENCE_ERROR" 26 "SYS_FSM_SUBSTATE_IMD_INITIALIZATION_ERROR" 27 "SYS_FSM_SUBSTATE_BMS_INITIALIZATION_ERROR";
VAL_ 55 II_VIFC_STATUS_04_VIFC_CmdError 1 "Error" 0 "NoError";
VAL_ 55 II_VIFC_STATUS_13_ST_ParamConfig 1 "NotExecuted" 0 "Executed";
VAL_ 55 II_VIFC_STATUS_12_ST_Overall 1 "NotExecuted" 0 "Executed";
VAL_ 55 II_VIFC_STATUS_02_IMC_Alive 1 "Error" 0 "NoError";
VAL_ 55 II_VIFC_STATUS_01_IMC_Connection 1 "Error" 0 "NoError";
VAL_ 55 II_VIFC_STATUS_00_IsoMeasurement 1 "Deactivated" 0 "Activated";
VAL_ 55 II_IMC_STATUS_05_IsoWarning 1 "Warning" 0 "NoWarning";
VAL_ 55 II_IMC_STATUS_04_Selftest 100 "Unknown" 1 "Running" 0 "NotRunning";
VAL_ 55 II_IMC_STATUS_03_Calibration 100 "Unknown" 1 "Running" 0 "NotRunning";
VAL_ 55 II_IMC_STATUS_02_System 1 "Error" 0 "NoError";
VAL_ 55 II_IMC_STATUS_01_Ground 1 "Error" 0 "NoError";
VAL_ 55 II_IMC_STATUS_00_IsoFailure 1 "Error" 0 "NoError";
VAL_ 34 MG_VIFC_POWER_MODE 100 "Unknown" 3 "PowerDown" 2 "PowerUp" 1 "PowerOn" 0 "PowerOff";
VAL_ 34 MC_VIFC_POWER_MODE 100 "Unknown" 3 "PowerDown" 2 "PowerUp" 1 "PowerOn" 0 "PowerOff";
VAL_ 34 MG_VIFC_VERSION_INDEX 2 "Firmware ID" 1 "Firmware" 0 "Bootloader";
VAL_ 34 MG_IMC_VERSION_INDEX 2 "Firmware ID" 1 "Firmware" 0 "Bootloader";
VAL_ 34 MC_VIFC_MEASURE_MODE 1 "Activated" 0 "Deactivated";
VAL_ 34 MC_VIFC_LOCK_MODE 100 "Unknown" 2 "BlockedToManyRetries" 1 "Locked" 0 "Unlocked";
VAL_ 34 MS_VIFC_HV_RELAIS_STATE 100 "Unknown" 1 "HVEnabled" 0 "HVDisabled";
VAL_ 34 MS_VIFC_HV_RELAIS 100 "Unknown" 1 "HV_1_POS" 0 "HV_1_NEG";
VAL_ 34 MC_IMC_CALIB_STEP 6 "GainCalibrationHV2" 5 "OffsetCalibrationHV2" 4 "ARef_12V_5V_Calibration" 3 "IsoCalibration" 2 "GainCalibrationHV1" 1 "OffsetCalibrationHV1" 0 "NoAction";
VAL_ 34 MC_IMC_SELFTEST_SCR 2 "ParameterConfig" 1 "OverAll" 0 "NoAction";
VAL_ 35 IG_VIFC_STATUS_04_VIFC_CmdError 1 "Error" 0 "NoError";
VAL_ 35 IG_VIFC_STATUS_13_ST_ParamConfig 1 "NotExecuted" 0 "Executed";
VAL_ 35 IG_VIFC_STATUS_12_ST_Overall 1 "NotExecuted" 0 "Executed";
VAL_ 35 IG_VIFC_STATUS_02_IMC_Alive 1 "Error" 0 "NoError";
VAL_ 35 IG_VIFC_STATUS_01_IMCConnection 1 "Error" 0 "NoError";
VAL_ 35 IG_VIFC_STATUS_00_IsoMeasurement 1 "Deactivated" 0 "Activated";
VAL_ 35 IG_IMC_STATUS_EXT_15_Reserved 1 "Error" 0 "NoError";
VAL_ 35 IG_IMC_STATUS_EXT_06_Reserved 1 "Error" 0 "NoError";
VAL_ 35 IG_IMC_STATUS_EXT_14_IDString 1 "Error" 0 "NoError";
VAL_ 35 IG_IMC_STATUS_EXT_13_HV2 1 "Error" 0 "NoError";
VAL_ 35 IG_IMC_STATUS_EXT_12_HV1 1 "Error" 0 "NoError";
VAL_ 35 IG_IMC_STATUS_EXT_11_FuseBits 1 "Error" 0 "NoError";
VAL_ 35 IG_IMC_STATUS_EXT_10_12V_NEG 1 "Error" 0 "NoError";
VAL_ 35 IG_IMC_STATUS_EXT_09_12V_POS 1 "Error" 0 "NoError";
VAL_ 35 IG_IMC_STATUS_EXT_08_TestPulse 1 "Error" 0 "NoError";
VAL_ 35 IG_IMC_STATUS_EXT_07_Parameter 1 "Error" 0 "NoError";
VAL_ 35 IG_IMC_STATUS_EXT_05_Stack 1 "Error" 0 "NoError";
VAL_ 35 IG_IMC_STATUS_EXT_04_RAM 1 "Error" 0 "NoError";
VAL_ 35 IG_IMC_STATUS_EXT_03_Flash 1 "Error" 0 "NoError";
VAL_ 35 IG_IMC_STATUS_EXT_02_EEPROM 1 "Error" 0 "NoError";
VAL_ 35 IG_IMC_STATUS_EXT_01_Hardware 1 "Error" 0 "NoError";
VAL_ 35 IG_IMC_STATUS_EXT_00_Calibration 1 "Error" 0 "NoError";
VAL_ 35 IG_IMC_STATUS_05_IsoWarning 1 "Warning" 0 "NoWarning";
VAL_ 35 IG_IMC_STATUS_04_Selftest 100 "Unknown" 1 "Running" 0 "NotRunning";
VAL_ 35 IG_IMC_STATUS_03_Calibration 100 "Unknown" 1 "Running" 0 "NotRunning";
VAL_ 35 IG_IMC_STATUS_02_System 1 "Error" 0 "NoError";
VAL_ 35 IG_IMC_STATUS_01_Ground 1 "Error" 0 "NoError";
VAL_ 35 IG_IMC_STATUS_00_IsoFailure 1 "Error" 0 "NoError";
VAL_ 35 IG_VIFC_VERSION_INDEX 1 "Firmware" 0 "Bootloader";
VAL_ 35 IG_IMC_VERSION_INDEX 3 "Firmware Hash" 2 "Firmware ID" 1 "Firmware" 0 "Bootloader";
VAL_ 35 IG_IMC_R_ISO_BIAS 2 "HV_1_POS" 1 "HV_1_NEG" 0 "Unknown";
VAL_ 35 IG_VIFC_IMC_ALIVE 100 "Unknown" 2 "OutOfRange" 1 "Error" 0 "Running";
VAL_ 35 IG_VIFC_POWER_MODE 100 "Unknown" 3 "PowerDown" 2 "PowerUp" 1 "PowerOn" 0 "PowerOff";
VAL_ 35 IC_VIFC_POWER_MODE 100 "Unknown" 3 "PowerDown" 2 "PowerUp" 1 "PowerOn" 0 "PowerOff";
VAL_ 35 IC_IMC_CALIB_STEP 6 "GainCalibrationHV2" 5 "OffsetCalibrationHV2" 4 "ARef_12V_5V_Calibration" 3 "IsoCalibration" 2 "GainCalibrationHV1" 1 "OffsetCalibrationHV1" 0 "NoAction";
VAL_ 35 IC_VIFC_LOCK_MODE 100 "Unknown" 2 "BlockedToManyRetries" 1 "Locked" 0 "Unlocked";
VAL_ 35 IS_VIFC_HV_RELAIS_STATE 100 "Unknown" 1 "HVEnabled" 0 "HVDisabled";
VAL_ 35 IS_VIFC_HV_RELAIS 100 "Unknown" 1 "HV_1_POS" 0 "HV_1_NEG";
VAL_ 35 IG_VIFC_LOCK_MODE 100 "Unknown" 2 "BlockedToManyRetries" 1 "Locked" 0 "Unlocked";
VAL_ 35 IG_VIFC_HV_RELAIS_STATE 100 "Unknown" 1 "HVEnabled" 0 "HVDisabled";
VAL_ 35 IG_VIFC_HV_RELAIS 100 "Unknown" 1 "HV_1_POS" 0 "HV_1_NEG";
VAL_ 35 IG_IMD_ERROR_CODE 1038 "VIFC_NoResponseTimeout" 1037 "VIFC_RepeatedOrMissingFrame" 1035 "VIFC_UnknownCommand" 1034 "VIFC_InvalidParameter" 1033 "VIFC_ChecksumErrorInFrame" 1032 "VIFC_Timeout10msExpired" 1001 "VIFC_QueueFullCommandRejected" 1000 "VIFC_CommandLocked" 37 "RepeatedOrMissingFrame" 36 "ErrorDuringWritingEEProms" 35 "UnknownCommand" 34 "InvalidParameter" 33 "ChecksumErrorInFrame" 32 "Timeout10msExpired";
VAL_ 35 IG_IMD_FAILED_CMD 255 "S_IMD_ERROR_FRAME" 226 "S_VIFC_GET_IMC_ALIVE" 225 "S_VIFC_GET_TEMP" 224 "S_VIFC_GET_LOCK" 223 "S_VIFC_GET_POWER_MODE" 222 "S_VIFC_GET_VERSION" 221 "S_VIFC_GET_HV_RELAIS" 220 "S_VIFC_GET_STATUS" 210 "S_VIFC_SET_HV_RELAIS" 203 "S_VIFC_CTL_MEASUREMENT" 202 "S_VIFC_CTL_LOCK" 201 "S_VIFC_CTL_POWER_MODE" 200 "S_VIFC_CTL_IMC_RESET" 90 "S_IMC_GET_TEST_CNT" 61 "S_IMC_GET_MANUFACTURER" 60 "S_IMC_GET_MEAN_FACTOR" 59 "S_IMC_GET_EEPROM" 58 "S_IMC_GET_HV_2" 57 "S_IMC_GET_R_ISO_WRN_THR" 55 "S_IMC_GET_STATUS" 54 "S_IMC_GET_HV_1" 53 "S_IMC_GET_R_ISO" 51 "S_IMC_GET_VERSION" 50 "S_IMC_GET_R_ISO_ERR_THR" 43 "S_IMC_SET_MEAN_FACTOR" 42 "S_IMC_SET_EEPROM" 41 "S_IMC_SET_R_ISO_WRN_THR" 40 "S_IMC_SET_R_ISO_ERR_THR" 35 "S_IMC_CTL_SYS_UPDATE" 34 "S_IMC_CTL_CALIB" 33 "S_IMC_CTL_SELFTEST" 0 "S_VIFC_CTL_DUMMY";
VAL_ 35 IC_IMC_SELFTEST_SCR 2 "ParameterConfig" 1 "OverAll" 0 "NoAction";
